VERSION ""

NS_ :

BS_:

BU_: BCM ELL ELR ERL ERR KHD N3P NAG NAP NCL NCP NPR NSP NVO PLG RSH RSL RSR SGW

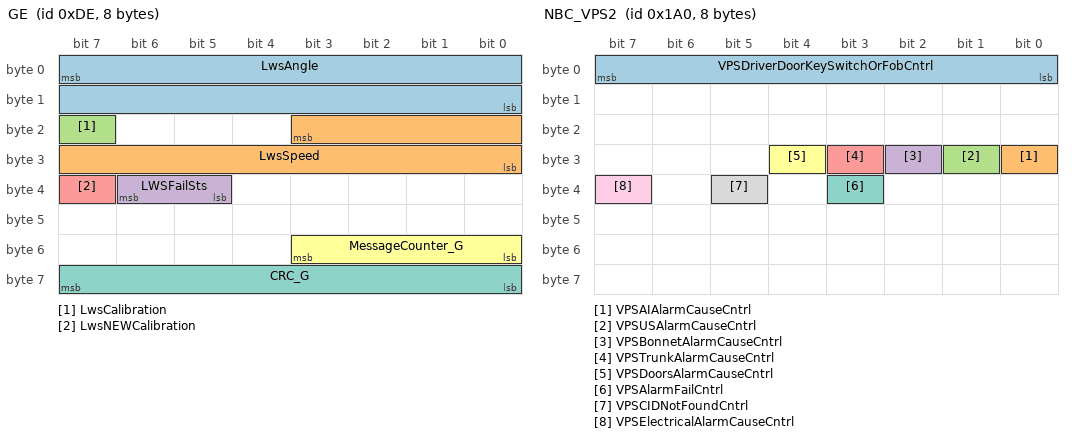
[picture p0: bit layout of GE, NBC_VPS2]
BO_ 222 GE: 8 SGW
 SG_ LwsAngle : 7|16@0+ (0.1,-720) [-720|720] "�" Vector__XXX
 SG_ LwsSpeed : 19|12@0+ (1,-2000) [-2000|2094] "�/S" Vector__XXX
 SG_ LwsCalibration : 23|1@0+ (1,0) [0|1] "" Vector__XXX
 SG_ LWSFailSts : 38|2@0+ (1,0) [0|3] "" Vector__XXX
 SG_ LwsNEWCalibration : 39|1@0+ (1,0) [0|1] "" Vector__XXX
 SG_ MessageCounter_G : 51|4@0+ (1,0) [0|15] "" Vector__XXX
 SG_ CRC_G : 63|8@0+ (1,0) [0|255] "" Vector__XXX

BO_ 359 RFHUB1: 8 BCM
 SG_ ExteriorRearSwitch : 0|1@0+ (1,0) [0|1] "" Vector__XXX
 SG_ IgnPosSts : 3|3@0+ (1,0) [0|7] "" Vector__XXX
 SG_ ValidKeySts : 5|2@0+ (1,0) [0|3] "" Vector__XXX
 SG_ CustKeyInIgnSts : 7|2@0+ (1,0) [0|3] "" Vector__XXX
 SG_ RFFuncReq : 8|5@0+ (1,0) [0|31] "" Vector__XXX
 SG_ RFFobNum : 12|4@0+ (1,0) [0|15] "" Vector__XXX
 SG_ RFRearFuncReq : 15|3@0+ (1,0) [0|7] "" Vector__XXX
 SG_ FobSearchResult : 16|8@0+ (1,0) [0|255] "" Vector__XXX
 SG_ RFReq : 19|3@0+ (1,0) [0|7] "" Vector__XXX
 SG_ EmergencyShutdown : 24|1@0+ (1,0) [0|1] "" Vector__XXX
 SG_ FobSearchFault : 32|1@0+ (1,0) [0|1] "" Vector__XXX
 SG_ HMIPowerOnReq : 33|1@0+ (1,0) [0|1] "" Vector__XXX
 SG_ FOBInterferenceAvoid : 34|1@0+ (1,0) [0|1] "raw" Vector__XXX
 SG_ DriverEnginOffRequest : 35|1@0+ (1,0) [0|1] "" Vector__XXX
 SG_ FobSearchResult_LongPressure : 39|3@0+ (1,0) [0|7] "" Vector__XXX
 SG_ FobSearchExteriorRear : 41|1@0+ (1,0) [0|1] "" Vector__XXX
 SG_ FobSearchExteriorLeft : 42|1@0+ (1,0) [0|1] "" Vector__XXX
 SG_ FobSearchExteriorRight : 43|1@0+ (1,0) [0|1] "" Vector__XXX
 SG_ FobSearchInterior : 44|1@0+ (1,0) [0|1] "" Vector__XXX
 SG_ FobSearchTrunk : 45|1@0+ (1,0) [0|1] "" Vector__XXX
 SG_ FobSearchStatus : 47|2@0+ (1,0) [0|3] "" Vector__XXX
 SG_ MessageCounter_HUB1 : 51|4@0+ (1,0) [0|15] ""  KHD
 SG_ KeyCommandReq : 52|1@0+ (1,0) [0|1] ""  KHD
 SG_ NPE_ActuationReq : 55|2@0+ (1,0) [0|3] "" Vector__XXX
 SG_ CRC_HUB1 : 63|8@0+ (1,0) [0|255] ""  KHD

BO_ 384 EXTERNAL_LIGHTS: 8 BCM
 SG_ FrontWiperServicePositionSts : 0|1@0+ (1,0) [0|1] ""  SGW
 SG_ FrontWindWiperCarWashErrSts : 1|1@0+ (1,0) [0|1] ""  SGW
 SG_ RearWindowWiperMotorErrorSts : 2|1@0+ (1,0) [0|1] ""  SGW
 SG_ RearWindowWiperSts : 3|1@0+ (1,0) [0|1] ""  NVO,SGW
 SG_ FrontWindshieldWiperMotErrSts : 4|1@0+ (1,0) [0|1] ""  SGW
 SG_ NightDaySts : 8|1@0+ (1,0) [0|1] ""  KHD,NVO,SGW
 SG_ RearFogLightSts : 9|1@0+ (1,0) [0|1] ""  SGW
 SG_ AHBFeature : 10|1@0+ (1,0) [0|1] ""  SGW
 SG_ LowBeamSts : 11|1@0+ (1,0) [0|1] ""  NVO,SGW
 SG_ HighBeamSts : 12|1@0+ (1,0) [0|1] ""  NVO,SGW
 SG_ LHParkTailLightSts : 13|1@0+ (1,0) [0|1] ""  SGW
 SG_ RHParkTailLightSts : 14|1@0+ (1,0) [0|1] ""  SGW
 SG_ LHRTurnLightFailSts : 16|1@0+ (1,0) [0|1] ""  SGW
 SG_ RHRTurnLightFailSts : 17|1@0+ (1,0) [0|1] ""  SGW
 SG_ EXT_LGH_ParkingLightCmd : 19|2@0+ (1,0) [0|3] ""  SGW
 SG_ RHeatedWindowSts : 20|1@0+ (1,0) [0|1] ""  NCL,SGW
 SG_ RHTurnSignalSts : 21|1@0+ (1,0) [0|1] ""  SGW
 SG_ LHTurnSignalSts : 22|1@0+ (1,0) [0|1] ""  SGW
 SG_ RHRearFogLightFailSts : 24|1@0+ (1,0) [0|1] ""  SGW
 SG_ LHRearFogLightFailSts : 25|1@0+ (1,0) [0|1] ""  SGW
 SG_ RHStopLightFailSts : 27|1@0+ (1,0) [0|1] ""  SGW
 SG_ LHStopLightFailSts : 28|1@0+ (1,0) [0|1] ""  SGW
 SG_ LHFTurnLightFailSts : 30|1@0+ (1,0) [0|1] ""  SGW
 SG_ RHFTurnLightFailSts : 31|1@0+ (1,0) [0|1] ""  SGW
 SG_ WindStopperSts : 34|3@0+ (1,0) [0|7] "" Vector__XXX
 SG_ PlateLightFailSts : 35|1@0+ (1,0) [0|1] ""  SGW
 SG_ LHRParkTailLightFailSts : 38|1@0+ (1,0) [0|1] ""  SGW
 SG_ RHRParkTailLightFailSts : 39|1@0+ (1,0) [0|1] ""  SGW
 SG_ ExternalLightsSts : 43|2@0+ (1,0) [0|3] ""  SGW
 SG_ MsgCnt_EXTERNAL_LIGHT : 51|4@0+ (1,0) [0|15] ""  SGW
 SG_ RearFog_Button : 53|2@0+ (1,0) [0|3] ""  SGW
 SG_ ParkingFeedbackLed : 55|2@0+ (1,0) [0|3] ""  SGW
 SG_ CRC_EXTERNAL_LIGHT : 63|8@0+ (1,0) [0|255] ""  SGW

BO_ 416 NBC_VPS2: 8 BCM
 SG_ VPSDriverDoorKeySwitchOrFobCntrl : 7|8@0+ (1,0) [0|255] ""  NCP,SGW
 SG_ VPSAIAlarmCauseCntrl : 24|1@0+ (1,0) [0|1] ""  SGW
 SG_ VPSUSAlarmCauseCntrl : 25|1@0+ (1,0) [0|1] ""  SGW
 SG_ VPSBonnetAlarmCauseCntrl : 26|1@0+ (1,0) [0|1] ""  SGW
 SG_ VPSTrunkAlarmCauseCntrl : 27|1@0+ (1,0) [0|1] ""  SGW
 SG_ VPSDoorsAlarmCauseCntrl : 28|1@0+ (1,0) [0|1] ""  SGW
 SG_ VPSAlarmFailCntrl : 35|1@0+ (1,0) [0|1] ""  SGW
 SG_ VPSCIDNotFoundCntrl : 37|1@0+ (1,0) [0|1] ""  SGW
 SG_ VPSElectricalAlarmCauseCntrl : 39|1@0+ (1,0) [0|1] ""  SGW

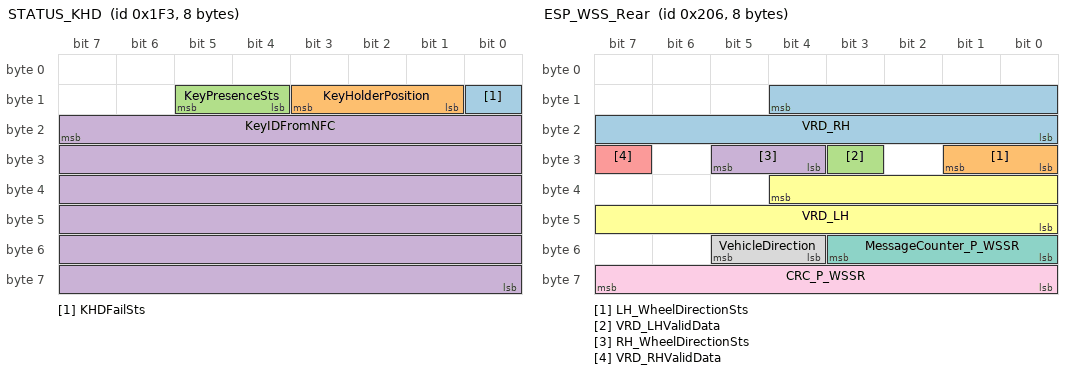
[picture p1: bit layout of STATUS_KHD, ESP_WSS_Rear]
BO_ 499 STATUS_KHD: 8 KHD
 SG_ KHDFailSts : 8|1@0+ (1,0) [0|1] ""  BCM,SGW
 SG_ KeyHolderPosition : 11|3@0+ (1,0) [0|7] ""  BCM,SGW
 SG_ KeyPresenceSts : 13|2@0+ (1,0) [0|3] ""  BCM,SGW
 SG_ KeyIDFromNFC : 23|48@0+ (1,0) [0|281474976710655] ""  BCM,SGW

BO_ 518 ESP_WSS_Rear: 8 SGW
 SG_ VRD_RH : 12|13@0+ (0.0625,0) [0.5|511.9375] "km/h"  ERL,ERR
 SG_ LH_WheelDirectionSts : 25|2@0+ (1,0) [0|3] "" Vector__XXX
 SG_ VRD_LHValidData : 27|1@0+ (1,0) [0|1] ""  ERL,ERR
 SG_ RH_WheelDirectionSts : 29|2@0+ (1,0) [0|3] "" Vector__XXX
 SG_ VRD_RHValidData : 31|1@0+ (1,0) [0|1] ""  ERL,ERR
 SG_ VRD_LH : 36|13@0+ (0.0625,0) [0.5|511.9375] "km/h"  ERL,ERR
 SG_ MessageCounter_P_WSSR : 51|4@0+ (1,0) [0|15] ""  ERL,ERR
 SG_ VehicleDirection : 53|2@0+ (1,0) [0|3] "" Vector__XXX
 SG_ CRC_P_WSSR : 63|8@0+ (1,0) [0|255] ""  ERL,ERR

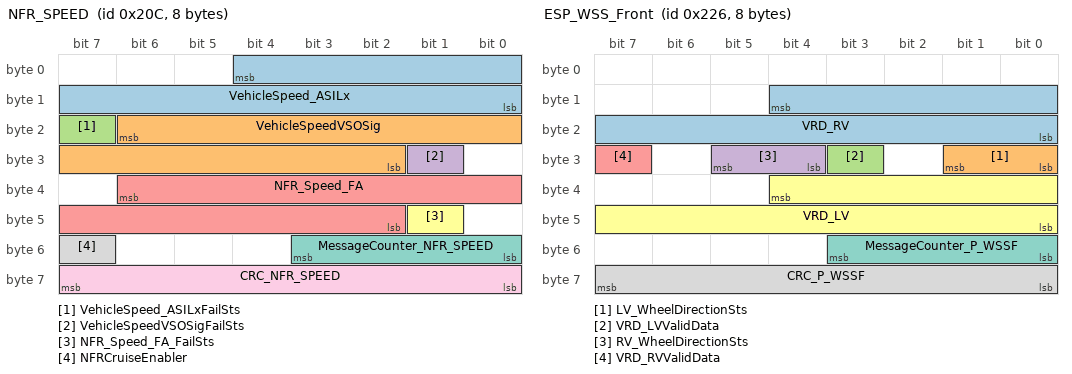
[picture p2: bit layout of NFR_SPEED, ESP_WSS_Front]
BO_ 524 NFR_SPEED: 8 SGW
 SG_ VehicleSpeed_ASILx : 4|13@0+ (0.0625,0) [0|511.9375] "km/h" Vector__XXX
 SG_ VehicleSpeedVSOSig : 22|13@0+ (0.0625,0) [0|511.9375] "km/h" Vector__XXX
 SG_ VehicleSpeed_ASILxFailSts : 23|1@0+ (1,0) [0|1] "" Vector__XXX
 SG_ VehicleSpeedVSOSigFailSts : 25|1@0+ (1,0) [0|1] "" Vector__XXX
 SG_ NFR_Speed_FA : 38|13@0+ (0.0625,0) [0|511.9375] "km/h"  ELL,ELR,ERL,ERR,KHD,NCP
 SG_ NFR_Speed_FA_FailSts : 41|1@0+ (1,0) [0|1] ""  ELL,ELR,ERL,ERR,KHD,NCP
 SG_ MessageCounter_NFR_SPEED : 51|4@0+ (1,0) [0|15] ""  ELL,ELR,ERL,ERR,NCP
 SG_ NFRCruiseEnabler : 55|1@0+ (1,0) [0|1] "" Vector__XXX
 SG_ CRC_NFR_SPEED : 63|8@0+ (1,0) [0|255] ""  ELL,ELR,ERL,ERR,NCP

BO_ 550 ESP_WSS_Front: 8 SGW
 SG_ VRD_RV : 12|13@0+ (0.0625,0) [0.5|511.9375] "km/h"  ERL,ERR
 SG_ LV_WheelDirectionSts : 25|2@0+ (1,0) [0|3] "" Vector__XXX
 SG_ VRD_LVValidData : 27|1@0+ (1,0) [0|1] ""  ERL,ERR
 SG_ RV_WheelDirectionSts : 29|2@0+ (1,0) [0|3] "" Vector__XXX
 SG_ VRD_RVValidData : 31|1@0+ (1,0) [0|1] ""  ERL,ERR
 SG_ VRD_LV : 36|13@0+ (0.0625,0) [0.5|511.9375] "km/h"  ERL,ERR
 SG_ MessageCounter_P_WSSF : 51|4@0+ (1,0) [0|15] ""  ERL,ERR
 SG_ CRC_P_WSSF : 63|8@0+ (1,0) [0|255] ""  ERL,ERR

BO_ 599 AIRBAG1: 8 BCM
 SG_ SBR2RowCentralSeatBuckleFailSts : 0|2@0+ (1,0) [0|3] "" Vector__XXX
 SG_ SBR2RowCentralSeatConfigSts : 1|1@0+ (1,0) [0|1] "" Vector__XXX
 SG_ AirBagFailSts : 7|2@0+ (1,0) [0|3] "" Vector__XXX
 SG_ SBR1RowDriverSeatFailSts : 8|2@0+ (1,0) [0|3] "" Vector__XXX
 SG_ SBR1RowDriverSeatConfigSts : 9|1@0+ (1,0) [0|1] "" Vector__XXX
 SG_ SBR2RowCentralSeatSts : 12|3@0+ (1,0) [0|7] "" Vector__XXX
 SG_ SBR1RowCentralSeatPPDFailSts : 14|2@0+ (1,0) [0|3] "" Vector__XXX
 SG_ SBR1RowPsngrSeatPPDFailSts : 17|2@0+ (1,0) [0|3] "" Vector__XXX
 SG_ SBR1RowPsngrSeatBuckleFailSts : 19|2@0+ (1,0) [0|3] "" Vector__XXX
 SG_ SBR1RowPsngrSeatConfigSts : 20|1@0+ (1,0) [0|1] "" Vector__XXX
 SG_ SBR1RowDriverSeatSts : 22|2@0+ (1,0) [0|3] "" Vector__XXX
 SG_ SBR2RowLeftSeatSts : 24|2@0+ (1,0) [0|3] ""  RSL
 SG_ SBR2RowRightSeatFailSts : 26|2@0+ (1,0) [0|3] "" Vector__XXX
 SG_ SBR2RowLeftSeatFailSts : 28|2@0+ (1,0) [0|3] "" Vector__XXX
 SG_ SBR1RowPsngrSeatSts : 31|3@0+ (1,0) [0|7] "" Vector__XXX
 SG_ CrashOutputSts : 36|8@0+ (1,0) [0|255] ""  ELL,ELR,ERL,ERR
 SG_ SBR2RowRightSeatSts : 38|2@0+ (1,0) [0|3] ""  RSR
 SG_ MessageCounter_NAB1 : 43|4@0+ (1,0) [0|15] ""  ELL,ELR,ERL,ERR,NCL,RSL,RSR
 SG_ CrashOutputValidData : 44|1@0+ (1,0) [0|1] ""  ELL,ELR,ERL,ERR
 SG_ CRC_NAB1 : 55|8@0+ (1,0) [0|255] ""  ELL,ELR,ERL,ERR,NCL,RSL,RSR
 SG_ AirBagWarningPADLampOnSts : 56|1@0+ (1,0) [0|1] "" Vector__XXX
 SG_ AirBagWarningPADLampOffSts : 57|1@0+ (1,0) [0|1] "" Vector__XXX
 SG_ SBR2RowRightSeatConfigSts : 58|1@0+ (1,0) [0|1] "" Vector__XXX
 SG_ SBR2RowLeftSeatConfigSts : 59|1@0+ (1,0) [0|1] "" Vector__XXX
 SG_ Ppd_psngr_info : 61|2@0+ (1,0) [0|3] ""  NCL
 SG_ AirBagWarningLampSts : 62|1@0+ (1,0) [0|1] "" Vector__XXX
 SG_ AirBagWarningPADPassengerAirbagS : 63|1@0+ (1,0) [0|1] "" Vector__XXX

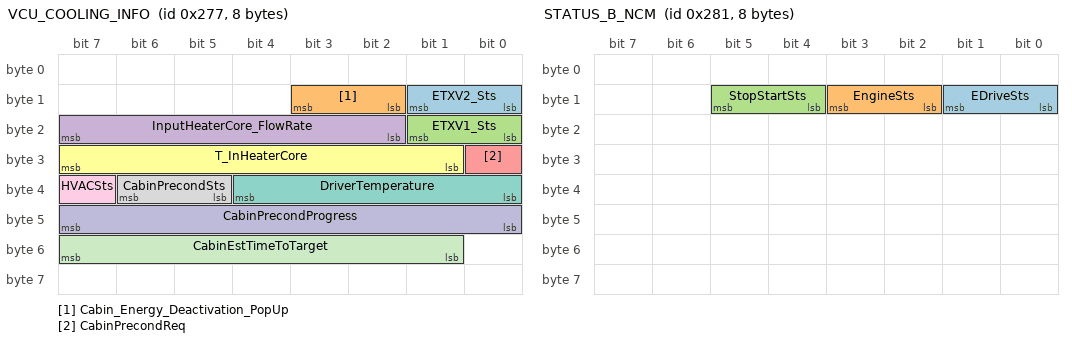
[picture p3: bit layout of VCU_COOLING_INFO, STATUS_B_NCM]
BO_ 631 VCU_COOLING_INFO: 8 SGW
 SG_ ETXV2_Sts : 9|2@0+ (1,0) [0|3] ""  NCL
 SG_ Cabin_Energy_Deactivation_PopUp : 11|2@0+ (1,0) [0|3] "" Vector__XXX
 SG_ ETXV1_Sts : 17|2@0+ (1,0) [0|3] ""  NCL
 SG_ InputHeaterCore_FlowRate : 23|6@0+ (1,0) [0|60] "l/min"  NCL
 SG_ CabinPrecondReq : 24|1@0+ (1,0) [0|1] ""  NCL
 SG_ T_InHeaterCore : 31|7@0+ (1,-20) [-20|90] "�C"  NCL
 SG_ DriverTemperature : 36|5@0+ (0.5,15.5) [15.5|28.5] ""  NCL
 SG_ CabinPrecondSts : 38|2@0+ (1,0) [0|3] "" Vector__XXX
 SG_ HVACSts : 39|1@0+ (1,0) [0|1] "" Vector__XXX
 SG_ CabinPrecondProgress : 47|8@0+ (0.5,0) [0|127.5] "%" Vector__XXX
 SG_ CabinEstTimeToTarget : 55|7@0+ (1,0) [0|127] "min" Vector__XXX

BO_ 641 STATUS_B_NCM: 8 BCM
 SG_ EDriveSts : 9|2@0+ (1,0) [0|3] ""  ELL,ELR,ERL,ERR,N3P,NAG,NAP,NCL,NCP,PLG,RSH,RSL,RSR
 SG_ EngineSts : 11|2@0+ (1,0) [0|3] ""  ELL,ELR,ERL,ERR,N3P,NAG,NAP,NCL,NCP,NPR,PLG,RSH,RSL,RSR
 SG_ StopStartSts : 13|2@0+ (1,0) [0|3] ""  ELL,ELR,ERL,ERR,NAG,NAP,NCL,NCP,PLG,RSL,RSR

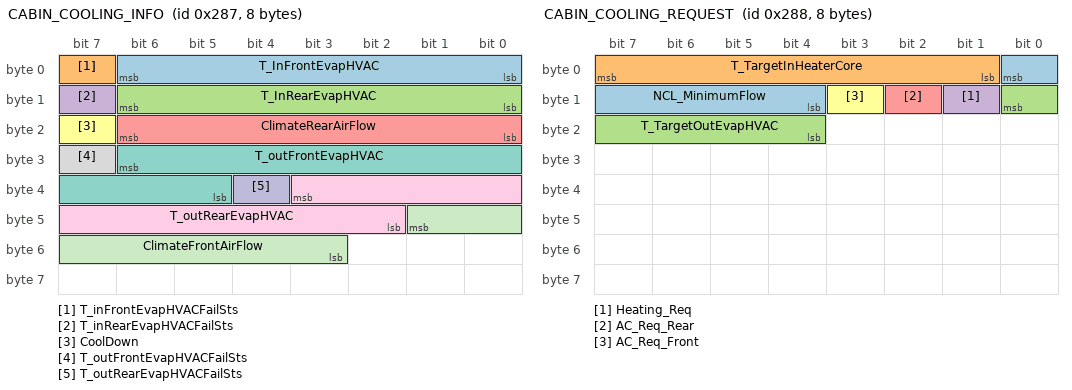
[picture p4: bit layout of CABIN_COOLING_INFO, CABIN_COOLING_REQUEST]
BO_ 647 CABIN_COOLING_INFO: 8 NCL
 SG_ T_InFrontEvapHVAC : 6|7@0+ (1,-10) [-10|90] "�C"  SGW
 SG_ T_inFrontEvapHVACFailSts : 7|1@0+ (1,0) [0|1] ""  SGW
 SG_ T_InRearEvapHVAC : 14|7@0+ (1,-10) [-10|90] "�C"  SGW
 SG_ T_inRearEvapHVACFailSts : 15|1@0+ (1,0) [0|1] ""  SGW
 SG_ ClimateRearAirFlow : 22|7@0+ (5,0) [0|500] "m3/h"  SGW
 SG_ CoolDown : 23|1@0+ (1,0) [0|1] ""  SGW
 SG_ T_outFrontEvapHVAC : 30|10@0+ (0.1,-10) [-10|70] "�C"  SGW
 SG_ T_outFrontEvapHVACFailSts : 31|1@0+ (1,0) [0|1] ""  SGW
 SG_ T_outRearEvapHVAC : 35|10@0+ (0.1,-10) [-10|70] "�C"  SGW
 SG_ T_outRearEvapHVACFailSts : 36|1@0+ (1,0) [0|1] ""  SGW
 SG_ ClimateFrontAirFlow : 41|7@0+ (5,0) [0|500] "m3/h"  SGW

BO_ 648 CABIN_COOLING_REQUEST: 8 NCL
 SG_ NCL_MinimumFlow : 0|5@0+ (1,0) [0|25] "l/min"  SGW
 SG_ T_TargetInHeaterCore : 7|7@0+ (1,-20) [-20|90] "�C"  SGW
 SG_ T_TargetOutEvapHVAC : 8|5@0+ (0.5,0) [0|10] "�C"  SGW
 SG_ Heating_Req : 9|1@0+ (1,0) [0|1] ""  SGW
 SG_ AC_Req_Rear : 10|1@0+ (1,0) [0|1] ""  SGW
 SG_ AC_Req_Front : 11|1@0+ (1,0) [0|1] ""  SGW

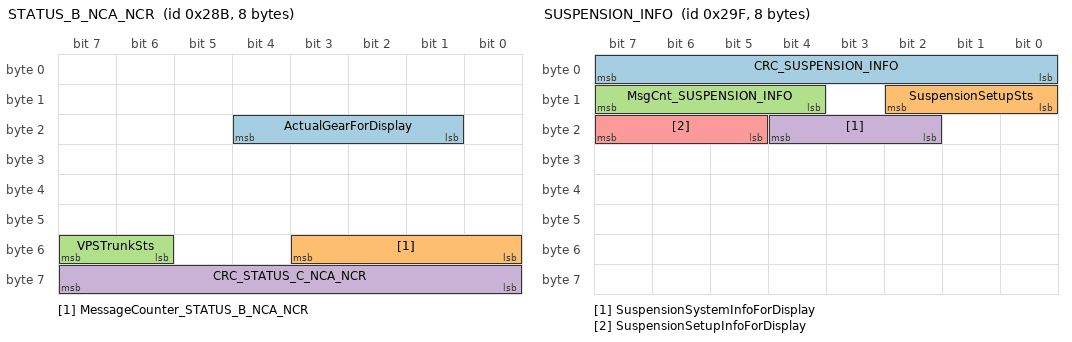
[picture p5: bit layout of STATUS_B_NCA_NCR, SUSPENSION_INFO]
BO_ 651 STATUS_B_NCA_NCR: 8 BCM
 SG_ ActualGearForDisplay : 20|4@0+ (1,0) [0|15] ""  SGW
 SG_ MessageCounter_STATUS_B_NCA_NCR : 51|4@0+ (1,0) [0|15] ""  RSL,RSR,SGW
 SG_ VPSTrunkSts : 55|2@0+ (1,0) [0|3] ""  RSL,RSR
 SG_ CRC_STATUS_C_NCA_NCR : 63|8@0+ (1,0) [0|255] ""  RSL,RSR,SGW

BO_ 671 SUSPENSION_INFO: 8 SGW
 SG_ CRC_SUSPENSION_INFO : 7|8@0+ (1,0) [0|255] ""  NVO
 SG_ SuspensionSetupSts : 10|3@0+ (1,0) [0|7] ""  NVO
 SG_ MsgCnt_SUSPENSION_INFO : 15|4@0+ (1,0) [0|14] ""  NVO
 SG_ SuspensionSystemInfoForDisplay : 20|3@0+ (1,0) [0|7] ""  NVO
 SG_ SuspensionSetupInfoForDisplay : 23|3@0+ (1,0) [0|7] "" Vector__XXX

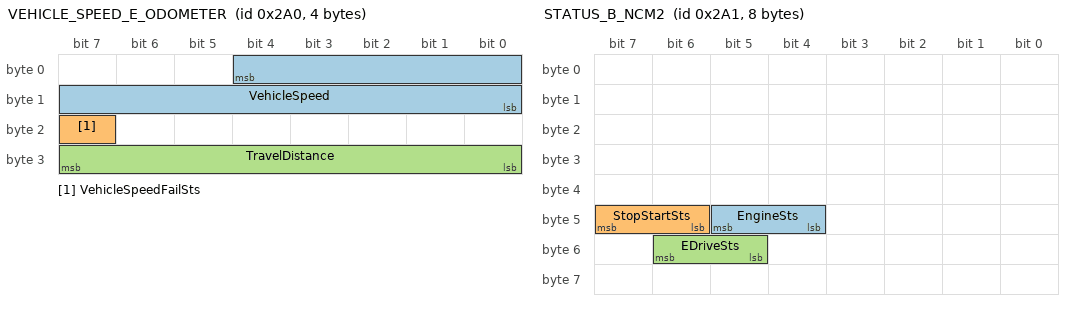
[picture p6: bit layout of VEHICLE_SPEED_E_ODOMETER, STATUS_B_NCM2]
BO_ 672 VEHICLE_SPEED_E_ODOMETER: 4 BCM
 SG_ VehicleSpeed : 4|13@0+ (0.1,0) [0|512] "km/h"  N3P,NAG,NAP,NCL,NCP,NPR,NSP,NVO,PLG,RSH,RSL,RSR,SGW
 SG_ VehicleSpeedFailSts : 23|1@0+ (1,0) [0|1] ""  N3P,NAG,NAP,NCL,NCP,NPR,NSP,NVO,PLG,RSH,RSL,RSR,SGW
 SG_ TravelDistance : 31|8@0+ (9.8,0) [0|2499] "m"  SGW

BO_ 673 STATUS_B_NCM2: 8 BCM
 SG_ EngineSts : 45|2@0+ (1,0) [0|3] ""  SGW
 SG_ StopStartSts : 47|2@0+ (1,0) [0|3] ""  SGW
 SG_ EDriveSts : 54|2@0+ (1,0) [0|3] ""  SGW

BO_ 684 STATUS_B_NAS: 4 BCM
 SG_ LWS_Angle : 7|16@0- (0.1,0) [-780|780] "�"  NSP,SGW
 SG_ LWS_OK : 23|1@0+ (1,0) [0|1] ""  NSP,SGW

BO_ 761 GEAR_INFO: 8 SGW
 SG_ GearLeverPositionforNPE : 20|3@0+ (1,0) [0|7] ""  KHD
 SG_ GearLeverFailForNPE : 24|1@0+ (1,0) [0|1] ""  KHD

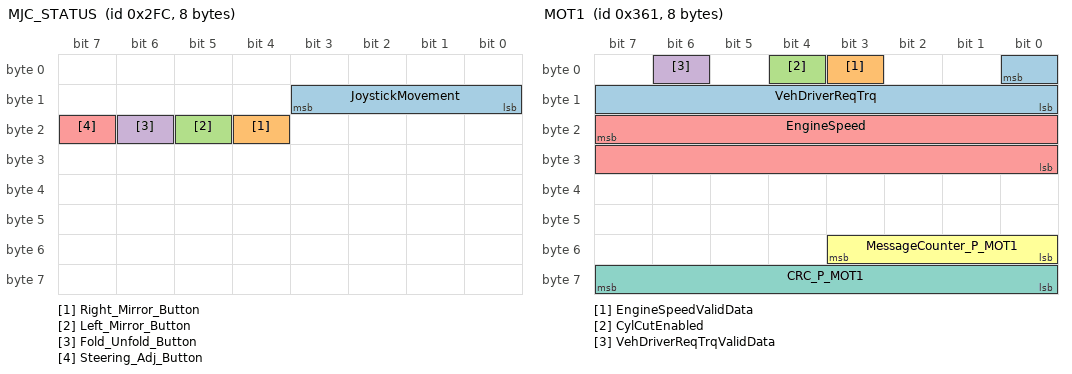
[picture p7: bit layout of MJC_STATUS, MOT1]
BO_ 764 MJC_STATUS: 8 BCM
 SG_ JoystickMovement : 11|4@0+ (1,0) [0|15] ""  NAG
 SG_ Right_Mirror_Button : 20|1@0+ (1,0) [0|1] ""  SGW
 SG_ Left_Mirror_Button : 21|1@0+ (1,0) [0|1] ""  SGW
 SG_ Fold_Unfold_Button : 22|1@0+ (1,0) [0|1] ""  SGW
 SG_ Steering_Adj_Button : 23|1@0+ (1,0) [0|1] ""  NAG

BO_ 765 AUDIO_INFO: 8 SGW
 SG_ AvasAlertSound : 10|1@0+ (1,0) [0|1] "" Vector__XXX
 SG_ AVASFailSts : 11|1@0+ (1,0) [0|1] ""  PLG

BO_ 865 MOT1: 8 SGW
 SG_ VehDriverReqTrq : 0|9@0+ (4,-508) [-508|1536] "Nm" Vector__XXX
 SG_ EngineSpeedValidData : 3|1@0+ (1,0) [0|1] ""  KHD,N3P,NCL,RSH
 SG_ CylCutEnabled : 4|1@0+ (1,0) [0|1] "" Vector__XXX
 SG_ VehDriverReqTrqValidData : 6|1@0+ (1,0) [0|1] "" Vector__XXX
 SG_ EngineSpeed : 23|16@0+ (1,0) [0|10240] "1/min"  KHD,N3P,NCL,RSH
 SG_ MessageCounter_P_MOT1 : 51|4@0+ (1,0) [0|15] ""  KHD,NCL
 SG_ CRC_P_MOT1 : 63|8@0+ (1,0) [0|255] ""  KHD,NCL

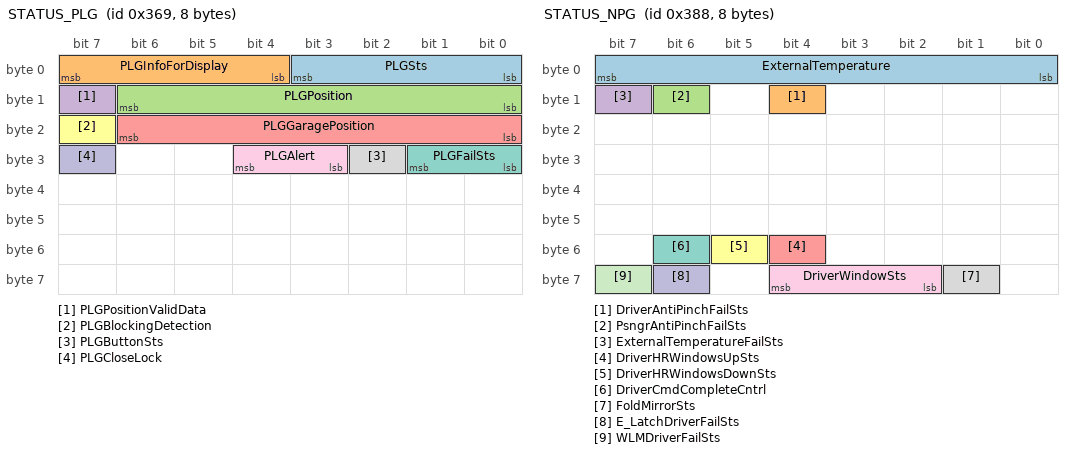
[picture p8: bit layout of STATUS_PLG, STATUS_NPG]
BO_ 873 STATUS_PLG: 8 PLG
 SG_ PLGSts : 3|4@0+ (1,0) [0|15] ""  BCM,SGW
 SG_ PLGInfoForDisplay : 7|4@0+ (1,0) [0|15] ""  SGW
 SG_ PLGPosition : 14|7@0+ (1,0) [0|100] "%"  SGW
 SG_ PLGPositionValidData : 15|1@0+ (1,0) [0|1] ""  SGW
 SG_ PLGGaragePosition : 22|7@0+ (1,0) [0|100] "%"  SGW
 SG_ PLGBlockingDetection : 23|1@0+ (1,0) [0|1] ""  SGW
 SG_ PLGFailSts : 25|2@0+ (1,0) [0|3] ""  SGW
 SG_ PLGButtonSts : 26|1@0+ (1,0) [0|1] ""  BCM,NCL,SGW
 SG_ PLGAlert : 28|2@0+ (1,0) [0|3] ""  SGW
 SG_ PLGCloseLock : 31|1@0+ (1,0) [0|1] ""  BCM,SGW

BO_ 896 STATUS_NBC: 8 BCM
 SG_ SysEOLSts : 2|1@0+ (1,0) [0|1] ""  SGW
 SG_ InternalLightSts : 3|1@0+ (1,0) [0|1] ""  KHD,NVO,SGW
 SG_ VehicleNotInUseSignaling : 4|1@0+ (1,0) [0|1] ""  SGW
 SG_ InternalBacklightStsKeyOff : 6|1@0+ (1,0) [0|1] ""  KHD,SGW
 SG_ BrakePadWearSts : 7|1@0+ (1,0) [0|1] ""  SGW
 SG_ WishWashSts : 9|1@0+ (1,0) [0|1] ""  NCL,SGW
 SG_ PsngrDoorSts : 11|1@0+ (1,0) [0|1] ""  NVO,SGW
 SG_ PLGCommand2 : 13|2@0+ (1,0) [0|3] ""  PLG,SGW
 SG_ RhatchSts : 14|1@0+ (1,0) [0|1] ""  NCL,NCP,SGW
 SG_ BonnetSts : 15|1@0+ (1,0) [0|1] ""  SGW
 SG_ ReverseGearBCSts : 18|1@0+ (1,0) [0|1] ""  NAG,NSP,SGW
 SG_ KeySts : 23|4@0+ (1,0) [0|15] "raw"  ELL,ELR,ERL,ERR,KHD,N3P,NAG,NAP,NCL,NPR,NSP,PLG,RSH,RSL,RSR,SGW
 SG_ BatteryVoltageLevel : 30|7@0+ (0.16,0) [0|18] "volt"  NAG,NAP,NCL,RSL,RSR,SGW
 SG_ NBCFISSts : 31|1@0+ (1,0) [0|1] ""  ELL,ELR,ERL,ERR,NCL,SGW
 SG_ FuelLevelFailSts : 32|1@0+ (1,0) [0|1] ""  SGW
 SG_ LowFuelWarningSts : 33|1@0+ (1,0) [0|1] ""  SGW
 SG_ FuelLevel : 47|8@0+ (1,0) [0|100] "%"  SGW
 SG_ IMMOCodeWarningLightSts : 54|7@0+ (1,0) [1|18] ""  SGW
 SG_ TurnIndicatorSts : 62|2@0+ (1,0) [0|3] ""  SGW
 SG_ RainSensorFailSts : 63|1@0+ (1,0) [0|1] ""  SGW

BO_ 904 STATUS_NPG: 8 BCM
 SG_ ExternalTemperature : 7|8@0+ (0.5,-40) [-39.5|87.5] "�C"  KHD,N3P,NAG,NAP,NCL,NCP,NPR,NSP,PLG,RSH,SGW
 SG_ DriverAntiPinchFailSts : 12|1@0+ (1,0) [0|1] ""  SGW
 SG_ PsngrAntiPinchFailSts : 14|1@0+ (1,0) [0|1] ""  SGW
 SG_ ExternalTemperatureFailSts : 15|1@0+ (1,0) [0|1] ""  KHD,N3P,NCL,NCP,NPR,NSP,PLG,RSH,SGW
 SG_ DriverHRWindowsUpSts : 52|1@0+ (1,0) [0|1] ""  NCP,SGW
 SG_ DriverHRWindowsDownSts : 53|1@0+ (1,0) [0|1] ""  NCP,SGW
 SG_ DriverCmdCompleteCntrl : 54|1@0+ (1,0) [0|1] ""  NCP,SGW
 SG_ FoldMirrorSts : 57|1@0+ (1,0) [0|1] ""  SGW
 SG_ DriverWindowSts : 60|3@0+ (1,0) [0|7] ""  NAG,NCP,SGW
 SG_ E_LatchDriverFailSts : 62|1@0+ (1,0) [0|1] ""  SGW
 SG_ WLMDriverFailSts : 63|1@0+ (1,0) [0|1] ""  SGW

BO_ 906 STATUS_NCL: 8 NCL
 SG_ MaxDefrostSts : 4|1@0+ (1,0) [0|1] ""  BCM,SGW
 SG_ RHeatedWindowCntrl : 5|1@0+ (1,0) [0|1] ""  BCM,SGW
 SG_ PowerModeSts : 13|2@0+ (1,0) [0|3] ""  BCM,SGW
 SG_ ADAS_heater : 18|1@0+ (1,0) [0|1] ""  SGW
 SG_ FogRisk : 23|1@0+ (1,0) [0|1] ""  SGW
 SG_ AirQualityIndex : 24|9@0+ (1,0) [0|511] ""  SGW
 SG_ NCL_RimHeatingCommand : 40|1@0+ (1,0) [0|1] ""  BCM,SGW
 SG_ TargetVoltage : 45|5@0+ (2,0) [0|62] "V"  NPR,SGW
 SG_ NPRActivationReq : 46|1@0+ (1,0) [0|1] ""  NPR,SGW
 SG_ NCL_FrontPassengerHeating : 49|2@0+ (1,0) [0|3] ""  NAP
 SG_ NCL_PassengerFans : 51|2@0+ (1,0) [0|3] ""  NAP
 SG_ NCL_FrontDriverHeating : 53|2@0+ (1,0) [0|3] ""  NAG
 SG_ NCL_DriverFans : 55|2@0+ (1,0) [0|3] ""  NAG
 SG_ NCL_RRHeating : 57|2@0+ (1,0) [0|3] ""  RSH
 SG_ NCL_RRFans : 59|2@0+ (1,0) [0|3] ""  RSH
 SG_ NCL_RLHeating : 61|2@0+ (1,0) [0|3] ""  RSH
 SG_ NCL_RLFans : 63|2@0+ (1,0) [0|3] ""  RSH

BO_ 952 STATUS_NSP2: 8 NSP
 SG_ FrameNumber : 1|2@0+ (1,0) [0|3] ""  SGW
 SG_ TotalFrameNumber : 3|2@0+ (1,0) [0|3] ""  SGW
 SG_ NSPFailSts : 5|2@0+ (1,0) [0|3] ""  NCP,SGW
 SG_ NSPControlSts : 7|2@0+ (1,0) [0|3] ""  SGW
 SG_ LHNSPBuzzerReqSts : 8|1@0+ (1,0) [0|1] ""  SGW
 SG_ LHLateralcolour : 10|2@0+ (1,0) [0|3] ""  SGW
 SG_ LHLateralObstacleDistance : 15|5@0+ (4,30) [30|154] "cm"  SGW
 SG_ RHNSPBuzzerReqSts : 16|1@0+ (1,0) [0|1] ""  SGW
 SG_ LHCentralcolour : 18|2@0+ (1,0) [0|3] ""  SGW
 SG_ LHCentralObstacleDistance : 23|5@0+ (4,30) [30|154] "cm"  SGW
 SG_ CNSPBuzzerReqSts : 24|1@0+ (1,0) [0|1] ""  SGW
 SG_ RHCentralcolour : 26|2@0+ (1,0) [0|3] ""  SGW
 SG_ RHCentralObstacleDistance : 31|5@0+ (4,30) [30|154] "cm"  SGW
 SG_ RHLateralcolour : 34|2@0+ (1,0) [0|3] ""  SGW
 SG_ RHLateralObstacleDistance : 39|5@0+ (4,30) [30|154] "cm"  SGW
 SG_ CapoteMovement : 45|2@0+ (1,0) [0|3] ""  NCP,SGW
 SG_ NSPBuzzerRepetitionRate : 47|2@0+ (1,0) [0|3] ""  SGW

BO_ 960 STATUS_NBC_2: 8 BCM
 SG_ ExternalLightSensorSts : 0|1@0+ (1,0) [0|1] ""  SGW
 SG_ FuelFlapSts : 1|1@0+ (1,0) [0|1] ""  SGW
 SG_ TyrePressureSystemFailSts : 8|1@0+ (1,0) [0|1] ""  SGW
 SG_ Night_E_DaySensorFailSts : 10|1@0+ (1,0) [0|1] ""  SGW
 SG_ RHRTyrePressureSts : 17|2@0+ (1,0) [0|3] ""  SGW
 SG_ LHRTyrePressureSts : 19|2@0+ (1,0) [0|3] ""  SGW
 SG_ RHFTyrePressureSts : 21|2@0+ (1,0) [0|3] ""  SGW
 SG_ LHFTyrePressureSts : 23|2@0+ (1,0) [0|3] ""  SGW
 SG_ LeftChildLockCntrl : 24|1@0+ (1,0) [0|1] ""  SGW
 SG_ RechargeFlapDisplayInfo : 28|4@0+ (1,0) [0|15] ""  SGW
 SG_ PLGBlink_Fbk : 29|1@0+ (1,0) [0|1] ""  SGW
 SG_ RimHeatingFbk : 31|2@0+ (1,0) [0|3] ""  NCL,SGW
 SG_ DriverSide : 38|1@0+ (1,0) [0|1] ""  NAG,NAP,NCP,RSL,RSR,SGW
 SG_ RHatchStsForNCP : 41|1@0+ (1,0) [0|1] ""  NCP,SGW
 SG_ PowerModeSts : 43|2@0+ (1,0) [0|3] ""  NCL,NCP,SGW
 SG_ TrunkCinchSts : 55|2@0+ (1,0) [0|3] ""  NCP,SGW
 SG_ RightChildLockCntrl : 56|1@0+ (1,0) [0|1] ""  SGW
 SG_ PLGCommandSource : 59|2@0+ (1,0) [0|3] ""  PLG,SGW
 SG_ CIDOnBoard : 60|1@0+ (1,0) [0|1] ""  NAG,SGW
 SG_ RHatchStsForPLG : 61|1@0+ (1,0) [0|1] ""  PLG,SGW
 SG_ PLGCommand : 63|2@0+ (1,0) [0|3] ""  NCL,PLG,SGW

BO_ 961 STATUS_NBC_3: 8 BCM
 SG_ UserPresence : 9|2@0+ (1,0) [0|3] ""  SGW
 SG_ RearCeilingLightsSts : 11|2@0+ (1,0) [0|3] ""  SGW
 SG_ LCC_RearDefrostCommand : 16|1@0+ (1,0) [0|1] ""  NCL,SGW
 SG_ LaunchLeverPos : 19|2@0+ (1,0) [0|3] ""  SGW
 SG_ FollowMeHomeEnable_Fbk : 23|4@0+ (1,0) [0|15] ""  SGW
 SG_ VehicleSts : 27|4@0+ (1,0) [0|7] ""  SGW
 SG_ RearRightWindowSwitch : 28|1@0+ (1,0) [0|1] ""  SGW
 SG_ RearLeftWindowSwitch : 29|1@0+ (1,0) [0|1] ""  SGW
 SG_ Deactivation_DoorOpening_Led : 30|1@0+ (1,0) [0|0] ""  SGW
 SG_ LCC_MaxDefrostCommand : 31|1@0+ (1,0) [0|1] ""  NCL,SGW
 SG_ LaunchLeverFailSts : 32|1@0+ (1,0) [0|1] ""  SGW
 SG_ LowBeam_Button : 34|2@0+ (1,0) [0|3] ""  SGW
 SG_ PlugReleaseReq : 37|1@0+ (1,0) [0|1] ""  SGW
 SG_ RearSeats : 39|2@0+ (1,0) [0|3] ""  NAG,NAP,SGW
 SG_ AHBSts : 41|2@0+ (1,0) [0|3] ""  SGW
 SG_ RearFog_Button : 43|2@0+ (1,0) [0|3] ""  SGW
 SG_ MirrorRHFailSts : 44|1@0+ (1,0) [0|1] ""  SGW
 SG_ MirrorLHFailSts : 45|1@0+ (1,0) [0|1] ""  SGW
 SG_ RearSeatsRightBackrestSts : 46|1@0+ (1,0) [0|1] ""  N3P,NAG,SGW
 SG_ RearSeatsLeftBackrestSts : 47|1@0+ (1,0) [0|1] ""  N3P,NAG,SGW

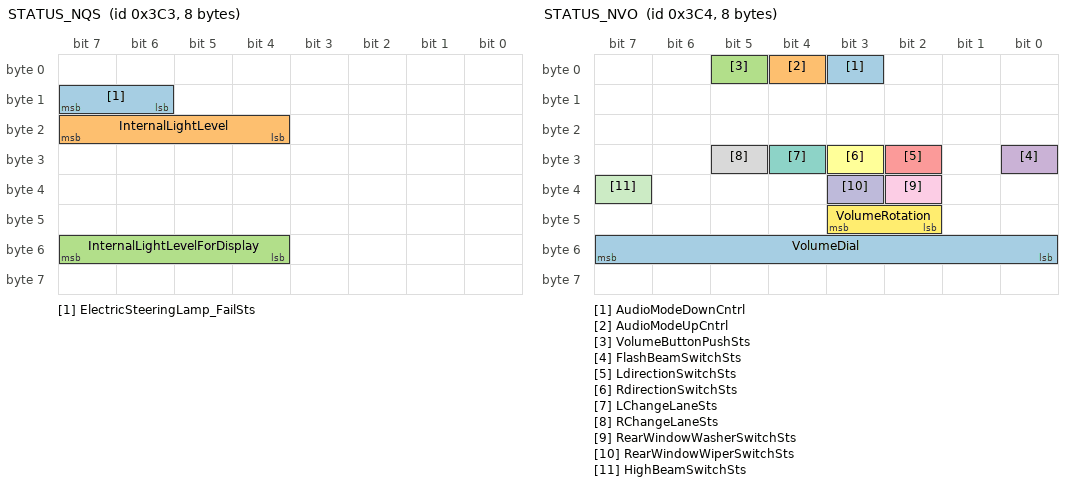
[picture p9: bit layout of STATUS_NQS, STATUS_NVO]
BO_ 963 STATUS_NQS: 8 SGW
 SG_ ElectricSteeringLamp_FailSts : 15|2@0+ (1,0) [0|3] ""  BCM
 SG_ InternalLightLevel : 23|4@0+ (1,0) [0|15] ""  BCM,NVO
 SG_ InternalLightLevelForDisplay : 55|4@0+ (1,0) [0|15] "" Vector__XXX

BO_ 964 STATUS_NVO: 8 NVO
 SG_ AudioModeDownCntrl : 3|1@0+ (1,0) [0|1] ""  BCM,SGW
 SG_ AudioModeUpCntrl : 4|1@0+ (1,0) [0|1] ""  BCM,SGW
 SG_ VolumeButtonPushSts : 5|1@0+ (1,0) [0|1] ""  BCM,SGW
 SG_ FlashBeamSwitchSts : 24|1@0+ (1,0) [0|1] ""  BCM,SGW
 SG_ LdirectionSwitchSts : 26|1@0+ (1,0) [0|1] ""  SGW
 SG_ RdirectionSwitchSts : 27|1@0+ (1,0) [0|1] ""  SGW
 SG_ LChangeLaneSts : 28|1@0+ (1,0) [0|1] ""  SGW
 SG_ RChangeLaneSts : 29|1@0+ (1,0) [0|1] ""  SGW
 SG_ RearWindowWasherSwitchSts : 34|1@0+ (1,0) [0|1] ""  BCM,SGW
 SG_ RearWindowWiperSwitchSts : 35|1@0+ (1,0) [0|1] ""  BCM,SGW
 SG_ HighBeamSwitchSts : 39|1@0+ (1,0) [0|1] ""  BCM,SGW
 SG_ VolumeRotation : 43|2@0+ (1,0) [0|3] ""  BCM,SGW
 SG_ VolumeDial : 55|8@0+ (1,0) [0|255] ""  SGW

BO_ 965 STATUS_NVO_2: 8 NVO
 SG_ ADAS_OnOffSts : 0|1@0+ (1,0) [0|1] ""  SGW
 SG_ RimTemperature : 15|8@0+ (0.5,-40) [-40|87.5] ""  BCM,NCL,SGW

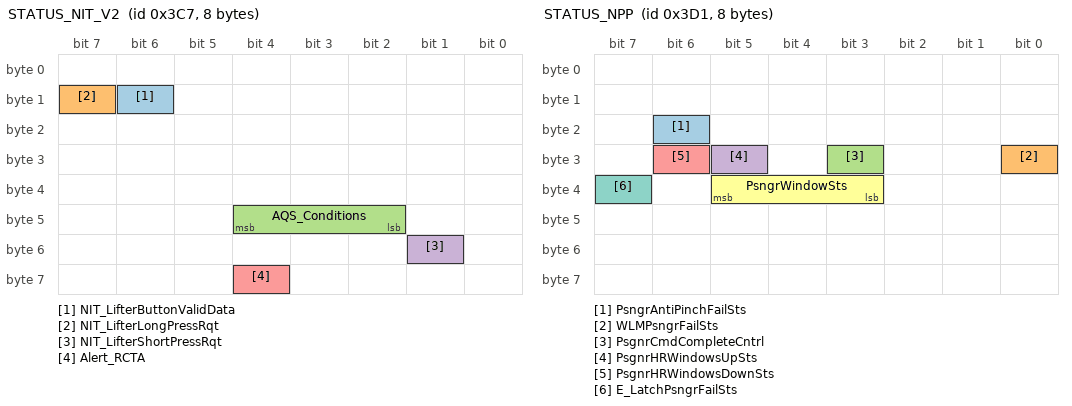
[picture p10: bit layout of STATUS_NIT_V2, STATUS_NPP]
BO_ 967 STATUS_NIT_V2: 8 SGW
 SG_ NIT_LifterButtonValidData : 14|1@0+ (1,0) [0|1] "" Vector__XXX
 SG_ NIT_LifterLongPressRqt : 15|1@0+ (1,0) [0|1] "" Vector__XXX
 SG_ AQS_Conditions : 44|3@0+ (1,0) [0|7] ""  NCL
 SG_ NIT_LifterShortPressRqt : 49|1@0+ (1,0) [0|1] "" Vector__XXX
 SG_ Alert_RCTA : 60|1@0+ (1,0) [0|1] "" Vector__XXX

BO_ 969 STATUS_NCP: 8 NCP
 SG_ CapoteBuzzerReq : 1|2@0+ (1,0) [0|3] ""  SGW
 SG_ CapoteFailSts : 3|2@0+ (1,0) [0|3] ""  BCM,NCL,SGW
 SG_ TrunkReleaseReqCntrl : 4|1@0+ (1,0) [0|1] ""  SGW
 SG_ CapoteSts : 7|3@0+ (1,0) [0|7] ""  BCM,NAG,NAP,NCL,SGW
 SG_ FrontWindowsEnable : 8|1@0+ (1,0) [0|1] ""  BCM,SGW
 SG_ TrunkEnable : 9|1@0+ (1,0) [0|1] ""  SGW
 SG_ CapoteInfoForDisplay : 15|6@0+ (1,0) [0|63] ""  SGW
 SG_ DriverHRWindowsSts : 17|2@0+ (1,0) [0|3] ""  BCM,SGW
 SG_ FrontWindowsMovementCmd : 19|2@0+ (1,0) [0|3] ""  BCM,SGW
 SG_ CapoteStsForDisplay : 23|4@0+ (1,0) [0|15] ""  SGW
 SG_ ObstacleDetectionSts : 24|2@0+ (1,0) [0|3] ""  SGW
 SG_ PowerModeSts : 26|2@0+ (1,0) [0|3] ""  BCM,SGW
 SG_ PsgnrHRWindowInitializedSts : 27|1@0+ (1,0) [0|1] ""  BCM,SGW
 SG_ DriverHRWindowInitializedSts : 28|1@0+ (1,0) [0|1] ""  BCM,SGW
 SG_ AutomaticDownCntrl : 29|1@0+ (1,0) [0|1] ""  BCM,SGW
 SG_ PsgnrHRWindowsSts : 31|2@0+ (1,0) [0|3] ""  BCM,SGW
 SG_ BackWindowInitializedSts : 32|1@0+ (1,0) [0|1] ""  SGW
 SG_ BackWindowSts : 34|2@0+ (1,0) [0|3] ""  BCM,SGW
 SG_ NCPAutoStopFailSts : 35|1@0+ (1,0) [0|1] ""  SGW
 SG_ NCPAutoStopEnableSts : 36|1@0+ (1,0) [0|1] ""  SGW
 SG_ NCPAutoStopStaySts : 37|1@0+ (1,0) [0|1] ""  SGW
 SG_ PowerStrikerUpEnable : 38|1@0+ (1,0) [0|1] ""  SGW
 SG_ TonneauCoverSts : 41|2@0+ (1,0) [0|3] ""  SGW
 SG_ STS_NCP_MsgCnt : 51|4@0+ (1,0) [0|15] ""  BCM,NAG,NAP,NCL,SGW
 SG_ CRC_STS_NCP : 63|8@0+ (1,0) [0|255] ""  BCM,NAG,NAP,NCL,SGW

BO_ 970 NPS_INFO: 8 SGW
 SG_ NPS_FrontSensorButtonSts : 23|1@0+ (1,0) [0|1] ""  NSP

BO_ 971 STATUS_ELL_V2: 8 ELL
 SG_ STS_LH_OsHandle_Lock_Active : 0|1@0+ (1,0) [0|1] ""  BCM,SGW
 SG_ STS_LH_OsHandle_Active : 1|1@0+ (1,0) [0|1] ""  BCM,SGW
 SG_ STS_LH_CinchStatus : 2|1@0+ (1,0) [0|1] ""  SGW
 SG_ STS_LH_DoorStatus : 4|2@0+ (1,0) [0|3] ""  BCM,SGW
 SG_ STS_LH_FailSts : 5|1@0+ (1,0) [0|1] ""  BCM,PLG,SGW
 SG_ STS_LH_Latch : 7|2@0+ (1,0) [0|3] ""  BCM,SGW
 SG_ STS_LH_DB_HomeSensor : 8|1@0+ (1,0) [0|1] "" Vector__XXX
 SG_ STS_LH_DB_ClockFail : 9|1@0+ (1,0) [0|1] "" Vector__XXX
 SG_ ELLCrashSts : 10|1@0+ (1,0) [0|1] ""  BCM,ELR,ERL,ERR,SGW
 SG_ STS_LH_HandleSpeedFailSts : 11|1@0+ (1,0) [0|1] ""  SGW
 SG_ STS_LH_ShortDropMode : 12|1@0+ (1,0) [0|1] ""  BCM,SGW
 SG_ STS_LH_PowerModeSts : 14|2@0+ (1,0) [0|3] ""  SGW
 SG_ STS_LH_IsHandle_Active : 15|1@0+ (1,0) [0|1] ""  BCM,SGW
 SG_ STS_LH_DB_CinchStatus : 21|1@0+ (1,0) [0|1] "" Vector__XXX
 SG_ STS_LH_DB_GStatusTEFault : 22|1@0+ (1,0) [0|1] "" Vector__XXX
 SG_ STS_LH_DB_ADC_DataReliable : 23|1@0+ (1,0) [0|1] "" Vector__XXX
 SG_ MessageCounter_STS_LH : 51|4@0+ (1,0) [0|15] ""  BCM,SGW
 SG_ CRC_STS_LH : 63|8@0+ (1,0) [0|255] ""  BCM,SGW

BO_ 972 STATUS_ELR_V2: 8 ELR
 SG_ STS_RH_OsHandle_Lock_Active : 0|1@0+ (1,0) [0|1] ""  BCM,SGW
 SG_ STS_RH_OsHandle_Active : 1|1@0+ (1,0) [0|1] ""  BCM,SGW
 SG_ STS_RH_CinchStatus : 2|1@0+ (1,0) [0|1] ""  SGW
 SG_ STS_RH_DoorStatus : 4|2@0+ (1,0) [0|3] ""  BCM,SGW
 SG_ STS_RH_FailSts : 5|1@0+ (1,0) [0|1] ""  BCM,PLG,SGW
 SG_ STS_RH_Latch : 7|2@0+ (1,0) [0|3] ""  BCM,SGW
 SG_ STS_RH_DB_HomeSensor : 8|1@0+ (1,0) [0|1] "" Vector__XXX
 SG_ STS_RH_DB_ClockFail : 9|1@0+ (1,0) [0|1] "" Vector__XXX
 SG_ ELRCrashSts : 10|1@0+ (1,0) [0|1] ""  BCM,ELL,ERL,ERR,SGW
 SG_ STS_RH_HandleSpeedFailSts : 11|1@0+ (1,0) [0|1] ""  SGW
 SG_ STS_RH_ShortDropMode : 12|1@0+ (1,0) [0|1] ""  BCM,SGW
 SG_ STS_RH_PowerModeSts : 14|2@0+ (1,0) [0|3] ""  SGW
 SG_ STS_RH_IsHandle_Active : 15|1@0+ (1,0) [0|1] ""  BCM,SGW
 SG_ STS_RH_DB_CinchStatus : 21|1@0+ (1,0) [0|1] "" Vector__XXX
 SG_ STS_RH_DB_GStatusTEFault : 22|1@0+ (1,0) [0|1] "" Vector__XXX
 SG_ STS_RH_DB_ADC_DataReliable : 23|1@0+ (1,0) [0|1] "" Vector__XXX
 SG_ MessageCounter_STS_RH : 51|4@0+ (1,0) [0|15] ""  BCM,SGW
 SG_ CRC_STS_RH : 63|8@0+ (1,0) [0|255] ""  BCM,SGW

BO_ 973 STATUS_ERL_V2: 8 ERL
 SG_ STS_LV_OsHandle_Lock_Active : 0|1@0+ (1,0) [0|1] ""  BCM,SGW
 SG_ STS_LV_OsHandle_Active : 1|1@0+ (1,0) [0|1] ""  BCM,SGW
 SG_ STS_LV_CinchStatus : 2|1@0+ (1,0) [0|1] ""  SGW
 SG_ STS_LV_DoorStatus : 4|2@0+ (1,0) [0|3] ""  BCM,SGW
 SG_ STS_LV_FailSts : 5|1@0+ (1,0) [0|1] ""  BCM,PLG,SGW
 SG_ STS_LV_Latch : 7|2@0+ (1,0) [0|3] ""  BCM,SGW
 SG_ STS_LV_PowerDoorSts : 11|4@0+ (1,0) [0|15] ""  BCM,SGW
 SG_ STS_LV_ShortDropMode : 12|1@0+ (1,0) [0|1] ""  BCM,SGW
 SG_ STS_LV_IsHandle_Active : 15|1@0+ (1,0) [0|1] ""  BCM,SGW
 SG_ STS_LV_PowerDoorPosValidData : 16|1@0+ (1,0) [0|1] ""  SGW
 SG_ STS_LV_PowerDoorPosition : 23|7@0+ (1,0) [0|100] ""  SGW
 SG_ ERLCrashSts : 24|1@0+ (1,0) [0|1] ""  BCM,ELL,ELR,ERR,SGW
 SG_ STS_LV_HandleSpeedFailSts : 25|1@0+ (1,0) [0|1] ""  SGW
 SG_ STS_LV_PDFailSts : 26|1@0+ (1,0) [0|1] ""  SGW
 SG_ STS_LV_ChildLockFailSts : 27|1@0+ (1,0) [0|1] ""  BCM,SGW
 SG_ STS_LV_DoorAlert : 29|2@0+ (1,0) [0|3] ""  PLG,SGW
 SG_ STS_LV_ChildLock_Feedback : 30|1@0+ (1,0) [0|1] ""  BCM,SGW
 SG_ STS_LV_ISwitch_Active : 31|1@0+ (1,0) [0|1] ""  BCM,SGW
 SG_ STS_LV_DB_ADC_DataReliable : 32|1@0+ (1,0) [0|1] "" Vector__XXX
 SG_ STS_LV_DB_AccFailSts_FrozenData : 33|1@0+ (1,0) [0|1] "" Vector__XXX
 SG_ STS_LV_DB_ChildLockMemFail : 34|1@0+ (1,0) [0|1] "" Vector__XXX
 SG_ STS_LV_DB_AccFailSts_WrongMode : 35|1@0+ (1,0) [0|1] "" Vector__XXX
 SG_ STS_LV_DB_HomeSensor : 36|1@0+ (1,0) [0|1] "" Vector__XXX
 SG_ STS_LV_DB_AccFailSts_NoAnswer : 37|1@0+ (1,0) [0|1] "" Vector__XXX
 SG_ STS_LV_DB_ClockFail : 38|1@0+ (1,0) [0|1] "" Vector__XXX
 SG_ LReleaseReq : 39|1@0+ (1,0) [0|1] ""  ELL,SGW
 SG_ STS_LV_DB_AccFailSts_StProcFail : 40|1@0+ (1,0) [0|1] "" Vector__XXX
 SG_ STS_LV_DB_FbDriveMode : 43|3@0+ (1,0) [0|7] "" Vector__XXX
 SG_ STS_LV_DB_DoorEngaged : 44|1@0+ (1,0) [0|1] "" Vector__XXX
 SG_ STS_LV_DB_OSSwitchClose : 45|1@0+ (1,0) [0|1] "" Vector__XXX
 SG_ STS_LV_DB_CinchStatus : 46|1@0+ (1,0) [0|1] "" Vector__XXX
 SG_ STS_LV_DB_GStatusTEFault : 47|1@0+ (1,0) [0|1] "" Vector__XXX
 SG_ MessageCounter_STS_LV : 51|4@0+ (1,0) [0|15] ""  BCM,SGW
 SG_ STS_LV_DB_PDUIssue : 54|3@0+ (1,0) [0|7] "" Vector__XXX
 SG_ STS_LV_DB_PDUActive : 55|1@0+ (1,0) [0|1] "" Vector__XXX
 SG_ CRC_STS_LV : 63|8@0+ (1,0) [0|255] ""  BCM,SGW

BO_ 974 STATUS_ERR_V2: 8 ERR
 SG_ STS_RV_OsHandle_Lock_Active : 0|1@0+ (1,0) [0|1] ""  BCM,SGW
 SG_ STS_RV_OsHandle_Active : 1|1@0+ (1,0) [0|1] ""  BCM,SGW
 SG_ STS_RV_CinchStatus : 2|1@0+ (1,0) [0|1] ""  SGW
 SG_ STS_RV_DoorStatus : 4|2@0+ (1,0) [0|3] ""  BCM,SGW
 SG_ STS_RV_FailSts : 5|1@0+ (1,0) [0|1] ""  BCM,PLG,SGW
 SG_ STS_RV_Latch : 7|2@0+ (1,0) [0|3] ""  BCM,SGW
 SG_ STS_RV_PowerDoorSts : 11|4@0+ (1,0) [0|15] ""  BCM,SGW
 SG_ STS_RV_ShortDropMode : 12|1@0+ (1,0) [0|1] ""  BCM,SGW
 SG_ STS_RV_IsHandle_Active : 15|1@0+ (1,0) [0|1] ""  BCM,SGW
 SG_ STS_RV_PowerDoorPosValidData : 16|1@0+ (1,0) [0|1] ""  SGW
 SG_ STS_RV_PowerDoorPosition : 23|7@0+ (1,0) [0|100] ""  SGW
 SG_ ERRCrashSts : 24|1@0+ (1,0) [0|1] ""  BCM,ELL,ELR,ERL,SGW
 SG_ STS_RV_HandleSpeedFailSts : 25|1@0+ (1,0) [0|1] ""  SGW
 SG_ STS_RV_PDFailSts : 26|1@0+ (1,0) [0|1] ""  SGW
 SG_ STS_RV_ChildLockFailSts : 27|1@0+ (1,0) [0|1] ""  BCM,SGW
 SG_ STS_RV_DoorAlert : 29|2@0+ (1,0) [0|3] ""  PLG,SGW
 SG_ STS_RV_ChildLock_Feedback : 30|1@0+ (1,0) [0|1] ""  BCM,SGW
 SG_ STS_RV_ISwitch_Active : 31|1@0+ (1,0) [0|1] ""  BCM,SGW
 SG_ STS_RV_DB_ADC_DataReliable : 32|1@0+ (1,0) [0|1] "" Vector__XXX
 SG_ STS_RV_DB_AccFailSts_FrozenData : 33|1@0+ (1,0) [0|1] "" Vector__XXX
 SG_ STS_RV_DB_ChildLockMemFail : 34|1@0+ (1,0) [0|1] "" Vector__XXX
 SG_ STS_RV_DB_AccFailSts_WrongMode : 35|1@0+ (1,0) [0|1] "" Vector__XXX
 SG_ STS_RV_DB_HomeSensor : 36|1@0+ (1,0) [0|1] "" Vector__XXX
 SG_ STS_RV_DB_AccFailSts_NoAnswer : 37|1@0+ (1,0) [0|1] "" Vector__XXX
 SG_ STS_RV_DB_ClockFail : 38|1@0+ (1,0) [0|1] "" Vector__XXX
 SG_ RReleaseReq : 39|1@0+ (1,0) [0|1] ""  ELR,SGW
 SG_ STS_RV_DB_AccFailSts_StProcFail : 40|1@0+ (1,0) [0|1] "" Vector__XXX
 SG_ STS_RV_DB_FbDriveMode : 43|3@0+ (1,0) [0|7] "" Vector__XXX
 SG_ STS_RV_DB_DoorEngaged : 44|1@0+ (1,0) [0|1] "" Vector__XXX
 SG_ STS_RV_DB_OSSwitchClose : 45|1@0+ (1,0) [0|1] "" Vector__XXX
 SG_ STS_RV_DB_CinchStatus : 46|1@0+ (1,0) [0|1] "" Vector__XXX
 SG_ STS_RV_DB_GStatusTEFault : 47|1@0+ (1,0) [0|1] "" Vector__XXX
 SG_ MessageCounter_STS_RV : 51|4@0+ (1,0) [0|15] ""  BCM,SGW
 SG_ STS_RV_DB_PDUIssue : 54|3@0+ (1,0) [0|7] "" Vector__XXX
 SG_ STS_RV_DB_PDUActive : 55|1@0+ (1,0) [0|1] "" Vector__XXX
 SG_ CRC_STS_RV : 63|8@0+ (1,0) [0|255] ""  BCM,SGW

BO_ 975 NBCtoEL: 8 BCM
 SG_ STS_LH_ShortDropFeedback : 0|1@0+ (1,0) [0|1] ""  ELL
 SG_ RChildlockCommandDoorSts : 1|1@0+ (1,0) [0|1] ""  ERR
 SG_ LChildlockCommandDoorSts : 2|1@0+ (1,0) [0|1] ""  ERL
 SG_ NBC_RV_Unlock : 3|1@0+ (1,0) [0|1] ""  ERR
 SG_ NBC_LV_Unlock : 4|1@0+ (1,0) [0|1] ""  ERL
 SG_ NBC_RH_Unlock : 5|1@0+ (1,0) [0|1] ""  ELR
 SG_ NBC_LH_Unlock : 6|1@0+ (1,0) [0|1] ""  ELL
 SG_ NBC_Lock : 7|1@0+ (1,0) [0|1] ""  ELL,ELR,ERL,ERR
 SG_ STS_RV_ShortDropFeedback : 13|1@0+ (1,0) [0|1] ""  ERR
 SG_ STS_LV_ShortDropFeedback : 14|1@0+ (1,0) [0|1] ""  ERL
 SG_ STS_RH_ShortDropFeedback : 15|1@0+ (1,0) [0|1] ""  ELR
 SG_ Position_FbkWLML : 19|4@0+ (10,0) [0|100] "" Vector__XXX
 SG_ Position_FbkWLMR : 23|4@0+ (10,0) [0|100] "" Vector__XXX
 SG_ Position_FbkWMRR : 43|4@0+ (10,0) [0|100] ""  ERR
 SG_ MessageCounter_NBCtoEL : 51|4@0+ (1,0) [0|15] ""  ELL,ELR,ERL,ERR
 SG_ Position_FbkWMRL : 55|4@0+ (10,0) [0|100] ""  ERL
 SG_ CRC_NBCtoEL : 63|8@0+ (1,0) [0|255] ""  ELL,ELR,ERL,ERR

BO_ 977 STATUS_NPP: 8 BCM
 SG_ PsngrAntiPinchFailSts : 22|1@0+ (1,0) [0|1] ""  SGW
 SG_ WLMPsngrFailSts : 24|1@0+ (1,0) [0|1] ""  SGW
 SG_ PsgnrCmdCompleteCntrl : 27|1@0+ (1,0) [0|1] ""  NCP,SGW
 SG_ PsgnrHRWindowsUpSts : 29|1@0+ (1,0) [0|1] ""  NCP,SGW
 SG_ PsgnrHRWindowsDownSts : 30|1@0+ (1,0) [0|1] ""  NCP,SGW
 SG_ PsngrWindowSts : 37|3@0+ (1,0) [0|7] ""  NAP,NCP,SGW
 SG_ E_LatchPsngrFailSts : 39|1@0+ (1,0) [0|1] ""  SGW

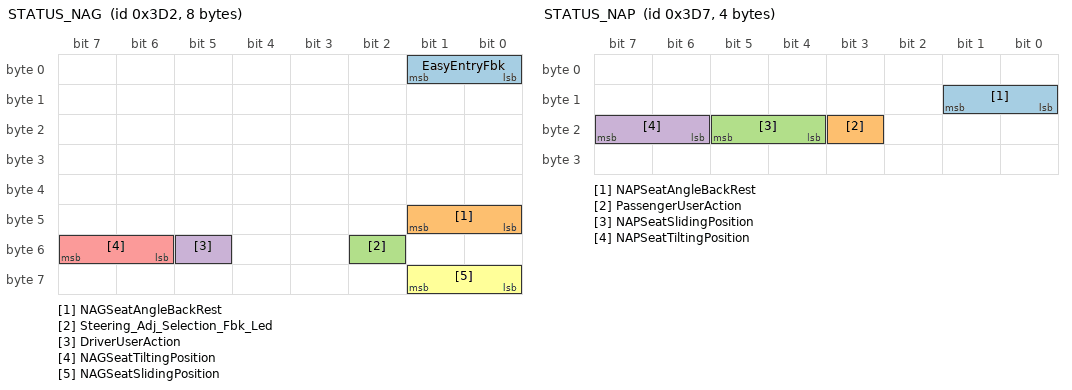
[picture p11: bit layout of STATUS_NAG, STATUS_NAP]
BO_ 978 STATUS_NAG: 8 NAG
 SG_ EasyEntryFbk : 1|2@0+ (1,0) [0|3] ""  SGW
 SG_ NAGSeatAngleBackRest : 41|2@0+ (1,0) [0|3] ""  RSL,RSR,SGW
 SG_ Steering_Adj_Selection_Fbk_Led : 50|1@0+ (1,0) [0|1] ""  BCM
 SG_ DriverUserAction : 53|1@0+ (1,0) [0|1] ""  BCM,SGW
 SG_ NAGSeatTiltingPosition : 55|2@0+ (1,0) [0|3] ""  RSL,RSR,SGW
 SG_ NAGSeatSlidingPosition : 57|2@0+ (1,0) [0|3] ""  RSL,RSR,SGW

BO_ 983 STATUS_NAP: 4 NAP
 SG_ NAPSeatAngleBackRest : 9|2@0+ (1,0) [0|3] ""  RSL,RSR
 SG_ PassengerUserAction : 19|1@0+ (1,0) [0|1] ""  BCM
 SG_ NAPSeatSlidingPosition : 21|2@0+ (1,0) [0|3] ""  RSL,RSR
 SG_ NAPSeatTiltingPosition : 23|2@0+ (1,0) [0|3] ""  RSL,RSR

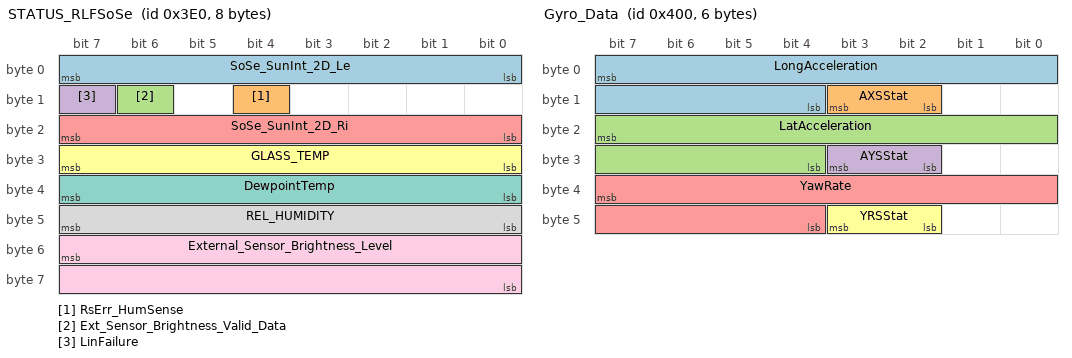
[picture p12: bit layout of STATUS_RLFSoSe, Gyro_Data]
BO_ 992 STATUS_RLFSoSe: 8 BCM
 SG_ SoSe_SunInt_2D_Le : 7|8@0+ (5,0) [0|1275] "W/m2"  NCL,SGW
 SG_ RsErr_HumSense : 12|1@0+ (1,0) [0|1] ""  NCL,SGW
 SG_ Ext_Sensor_Brightness_Valid_Data : 14|1@0+ (1,0) [0|1] ""  SGW
 SG_ LinFailure : 15|1@0+ (1,0) [0|1] ""  NCL,SGW
 SG_ SoSe_SunInt_2D_Ri : 23|8@0+ (5,0) [0|1275] "W/m2"  NCL,SGW
 SG_ GLASS_TEMP : 31|8@0+ (0.5,-40) [-40|87.5] "�C"  NCL,NPR,SGW
 SG_ DewpointTemp : 39|8@0+ (0.5,-40) [-40|87.5] "�C"  NCL,SGW
 SG_ REL_HUMIDITY : 47|8@0+ (0.5,0) [0|127.5] "%"  NCL,SGW
 SG_ External_Sensor_Brightness_Level : 55|16@0+ (1,0) [0|65535] "lux"  SGW

BO_ 1024 Gyro_Data: 6 BCM
 SG_ LongAcceleration : 7|12@0+ (0.02,-40.96) [-40.96|40.92] "m/s�" Vector__XXX
 SG_ AXSStat : 11|2@0+ (1,0) [0|3] "" Vector__XXX
 SG_ LatAcceleration : 23|12@0+ (0.02,-40.96) [-40.96|40.92] "m/s�"  NCP
 SG_ AYSStat : 27|2@0+ (1,0) [0|3] ""  NCP
 SG_ YawRate : 39|12@0+ (0.08,-163.84) [-163.84|163.68] "�/s" Vector__XXX
 SG_ YRSStat : 43|2@0+ (1,0) [0|3] "" Vector__XXX

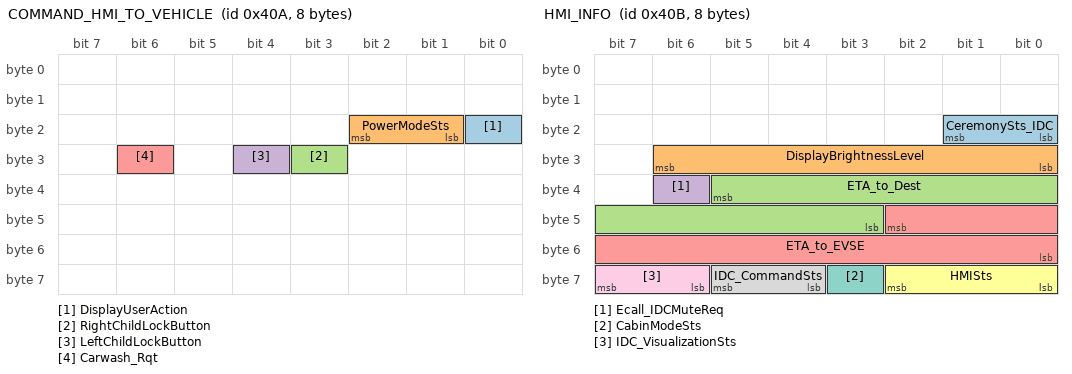
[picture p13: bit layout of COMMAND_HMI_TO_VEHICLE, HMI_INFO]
BO_ 1034 COMMAND_HMI_TO_VEHICLE: 8 SGW
 SG_ DisplayUserAction : 16|1@0+ (1,0) [0|1] ""  BCM
 SG_ PowerModeSts : 18|2@0+ (1,0) [0|3] ""  BCM
 SG_ RightChildLockButton : 27|1@0+ (1,0) [0|1] ""  BCM
 SG_ LeftChildLockButton : 28|1@0+ (1,0) [0|1] ""  BCM
 SG_ Carwash_Rqt : 30|1@0+ (1,0) [0|1] "" Vector__XXX

BO_ 1035 HMI_INFO: 8 SGW
 SG_ CeremonySts_IDC : 17|2@0+ (1,0) [0|3] "" Vector__XXX
 SG_ DisplayBrightnessLevel : 30|7@0+ (1,0) [0|127] "" Vector__XXX
 SG_ ETA_to_Dest : 37|11@0+ (1,0) [0|2047] "min" Vector__XXX
 SG_ Ecall_IDCMuteReq : 38|1@0+ (1,0) [0|1] "" Vector__XXX
 SG_ ETA_to_EVSE : 42|11@0+ (1,0) [0|2047] "min" Vector__XXX
 SG_ HMISts : 58|3@0+ (1,0) [0|3] ""  KHD,N3P,NAG,NAP,NCL,RSH,RSL,RSR
 SG_ CabinModeSts : 59|1@0+ (1,0) [0|1] ""  NCL
 SG_ IDC_CommandSts : 61|2@0+ (1,0) [0|3] "" Vector__XXX
 SG_ IDC_VisualizationSts : 63|2@0+ (1,0) [0|3] "" Vector__XXX

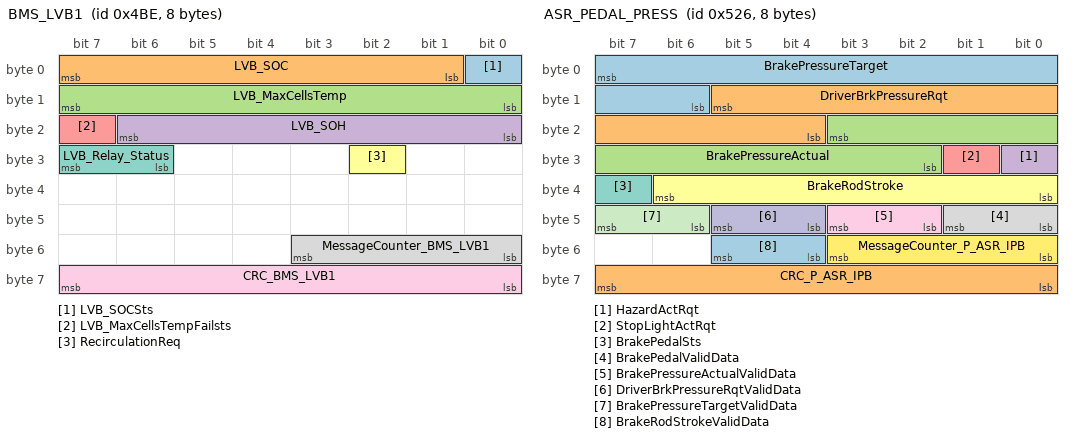
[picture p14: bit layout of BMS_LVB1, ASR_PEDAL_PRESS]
BO_ 1214 BMS_LVB1: 8 SGW
 SG_ LVB_SOCSts : 0|1@0+ (1,0) [0|1] ""  NAG,NAP,NCL,RSL,RSR
 SG_ LVB_SOC : 7|7@0+ (1,0) [0|100] "%"  NAG,NAP,NCL,RSL,RSR
 SG_ LVB_MaxCellsTemp : 15|8@0+ (1,-45) [-45|170] "�C" Vector__XXX
 SG_ LVB_SOH : 22|7@0+ (1,0) [0|100] "%" Vector__XXX
 SG_ LVB_MaxCellsTempFailsts : 23|1@0+ (1,0) [0|1] "" Vector__XXX
 SG_ RecirculationReq : 26|1@0+ (1,0) [0|1] ""  NCL
 SG_ LVB_Relay_Status : 31|2@0+ (1,0) [0|3] "" Vector__XXX
 SG_ MessageCounter_BMS_LVB1 : 51|4@0+ (1,0) [0|15] ""  NAG,NAP,NCL,RSL,RSR
 SG_ CRC_BMS_LVB1 : 63|8@0+ (1,0) [0|255] ""  NAG,NAP,NCL,RSL,RSR

BO_ 1313 STATUS_DOORS: 8 BCM
 SG_ STS_DRS_DriverLatchsts : 1|2@0+ (1,0) [0|3] "" Vector__XXX
 SG_ STS_DRS_PsngrDoorSts : 3|2@0+ (1,0) [0|3] ""  NAG,NAP,RSL,RSR
 SG_ STS_DRS_DriverDoorSts : 5|2@0+ (1,0) [0|3] ""  NAG,NAP,RSL,RSR
 SG_ STS_DRS_VPSTrunkSts : 7|2@0+ (1,0) [0|3] "" Vector__XXX
 SG_ STS_DRS_RearRightLatchsts : 9|2@0+ (1,0) [0|3] "" Vector__XXX
 SG_ STS_DRS_RearLeftDoorSts : 11|2@0+ (1,0) [0|3] ""  NAG,NAP,RSL,RSR
 SG_ STS_DRS_RearRightDoorSts : 13|2@0+ (1,0) [0|3] ""  NAG,NAP,RSL,RSR
 SG_ STS_DRS_PsngrLatchsts : 15|2@0+ (1,0) [0|3] "" Vector__XXX
 SG_ STS_DRS_PsngrWindowSts : 17|3@0+ (1,0) [0|7] "" Vector__XXX
 SG_ STS_DRS_DriverWindowSts : 20|3@0+ (1,0) [0|7] "" Vector__XXX
 SG_ STS_DRS_VPSLockValidData : 21|1@0+ (1,0) [0|1] "" Vector__XXX
 SG_ STS_DRS_RearLeftLatchsts : 23|2@0+ (1,0) [0|3] "" Vector__XXX
 SG_ TrunkInternalButton : 24|1@0+ (1,0) [0|1] "" Vector__XXX
 SG_ STS_DRS_RearRightWindowSts : 27|3@0+ (1,0) [0|7] "" Vector__XXX
 SG_ STS_DRS_RearLeftWindowSts : 30|3@0+ (1,0) [0|7] "" Vector__XXX
 SG_ Interior_Lock : 35|1@0+ (1,0) [0|1] "" Vector__XXX
 SG_ VPSDoorSts : 37|2@0+ (1,0) [0|3] ""  KHD
 SG_ LockUnlockDoors_Button : 38|1@0+ (1,0) [0|1] "" Vector__XXX
 SG_ TrunkExternalButton : 39|1@0+ (1,0) [0|1] "" Vector__XXX
 SG_ MessageCounter_STS_DRS : 51|4@0+ (1,0) [0|15] ""  KHD,NAG,NAP
 SG_ CRC_STS_DRS : 63|8@0+ (1,0) [0|255] ""  KHD,NAG,NAP

BO_ 1318 ASR_PEDAL_PRESS: 8 SGW
 SG_ BrakePressureTarget : 7|10@0+ (0.25,0) [0|200] "bar" Vector__XXX
 SG_ DriverBrkPressureRqt : 13|10@0+ (0.25,0) [0|200] "bar"  KHD
 SG_ BrakePressureActual : 19|10@0+ (0.25,0) [0|200] "bar" Vector__XXX
 SG_ HazardActRqt : 24|1@0+ (1,0) [0|1] "" Vector__XXX
 SG_ StopLightActRqt : 25|1@0+ (1,0) [0|1] "" Vector__XXX
 SG_ BrakeRodStroke : 38|7@0+ (0.2,0) [0|20] "mm" Vector__XXX
 SG_ BrakePedalSts : 39|1@0+ (1,0) [0|1] "" Vector__XXX
 SG_ BrakePedalValidData : 41|2@0+ (1,0) [0|3] "" Vector__XXX
 SG_ BrakePressureActualValidData : 43|2@0+ (1,0) [0|3] "" Vector__XXX
 SG_ DriverBrkPressureRqtValidData : 45|2@0+ (1,0) [0|3] ""  KHD
 SG_ BrakePressureTargetValidData : 47|2@0+ (1,0) [0|3] "" Vector__XXX
 SG_ MessageCounter_P_ASR_IPB : 51|4@0+ (1,0) [0|15] ""  KHD
 SG_ BrakeRodStrokeValidData : 53|2@0+ (1,0) [0|3] "" Vector__XXX
 SG_ CRC_P_ASR_IPB : 63|8@0+ (1,0) [0|255] ""  KHD

BO_ 1351 HAPTIC1: 8 SGW
 SG_ HALF_CHIME_TYPESts : 3|4@0+ (1,0) [0|15] "" Vector__XXX
 SG_ TSR_Fault : 4|1@0+ (1,0) [0|1] "" Vector__XXX
 SG_ TSR_ON : 5|1@0+ (1,0) [0|1] "" Vector__XXX
 SG_ LDWSystemSts : 7|2@0+ (1,0) [0|3] "" Vector__XXX
 SG_ StatusLKA : 9|2@0+ (1,0) [0|3] "" Vector__XXX
 SG_ LDWSensitivitySts : 13|2@0+ (1,0) [0|3] "" Vector__XXX
 SG_ HALF_RF_CHIME_RQSts : 14|1@0+ (1,0) [0|1] "" Vector__XXX
 SG_ HALF_LF_CHIME_RQSts : 15|1@0+ (1,0) [0|1] "" Vector__XXX
 SG_ TSA_ON : 17|2@0+ (1,0) [0|3] "" Vector__XXX
 SG_ HandsOnSts : 21|3@0+ (1,0) [0|7] "" Vector__XXX
 SG_ StatusDDA : 23|2@0+ (1,0) [0|3] "" Vector__XXX
 SG_ ADAS_Unavailable_Camera : 27|2@0+ (1,0) [0|3] "" Vector__XXX
 SG_ TSAMainSign2Fbk : 29|2@0+ (1,0) [0|3] "" Vector__XXX
 SG_ TSASignChangeFbk : 31|2@0+ (1,0) [0|3] "" Vector__XXX
 SG_ DDAW_Level : 35|4@0+ (1,0) [0|15] "" Vector__XXX
 SG_ DrowsinessSts : 37|2@0+ (1,0) [0|3] "" Vector__XXX
 SG_ LDWWarningType_fbk : 39|2@0+ (1,0) [0|3] "" Vector__XXX
 SG_ DisplaySts : 40|8@0+ (1,0) [0|255] "" Vector__XXX
 SG_ SensorBlinded : 41|1@0+ (1,0) [0|1] "" Vector__XXX
 SG_ AHBFault : 42|1@0+ (1,0) [0|1] "" Vector__XXX
 SG_ AHB_ON : 43|1@0+ (1,0) [0|1] "" Vector__XXX
 SG_ TSR_Sts : 46|1@0+ (1,0) [0|1] "" Vector__XXX
 SG_ HALF_heaterSts : 47|1@0+ (1,0) [0|1] ""  NCL
 SG_ DDAW_Index : 48|9@0+ (0.2,0) [0|100] "" Vector__XXX

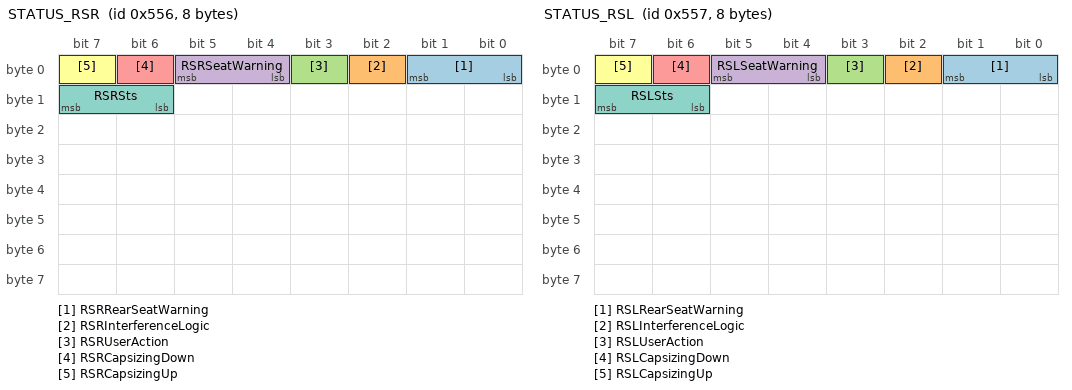
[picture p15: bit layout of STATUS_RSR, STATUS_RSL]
BO_ 1366 STATUS_RSR: 8 RSR
 SG_ RSRRearSeatWarning : 1|2@0+ (1,0) [0|3] ""  SGW
 SG_ RSRInterferenceLogic : 2|1@0+ (1,0) [0|1] ""  NAG,NAP,SGW
 SG_ RSRUserAction : 3|1@0+ (1,0) [0|1] ""  BCM
 SG_ RSRSeatWarning : 5|2@0+ (1,0) [0|3] ""  NAG,NAP
 SG_ RSRCapsizingDown : 6|1@0+ (1,0) [0|1] ""  NAG,NAP,SGW
 SG_ RSRCapsizingUp : 7|1@0+ (1,0) [0|1] ""  NAG,NAP,SGW
 SG_ RSRSts : 15|2@0+ (1,0) [0|3] ""  NAG,NAP

BO_ 1367 STATUS_RSL: 8 RSL
 SG_ RSLRearSeatWarning : 1|2@0+ (1,0) [0|3] ""  SGW
 SG_ RSLInterferenceLogic : 2|1@0+ (1,0) [0|1] ""  NAG,NAP,SGW
 SG_ RSLUserAction : 3|1@0+ (1,0) [0|1] ""  BCM
 SG_ RSLSeatWarning : 5|2@0+ (1,0) [0|3] ""  NAG,NAP
 SG_ RSLCapsizingDown : 6|1@0+ (1,0) [0|1] ""  NAG,NAP,SGW
 SG_ RSLCapsizingUp : 7|1@0+ (1,0) [0|1] ""  NAG,NAP,SGW
 SG_ RSLSts : 15|2@0+ (1,0) [0|3] ""  NAG,NAP

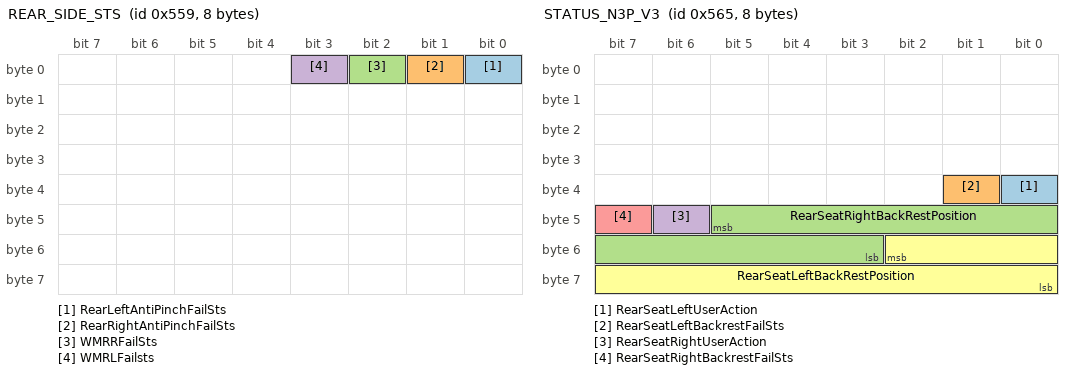
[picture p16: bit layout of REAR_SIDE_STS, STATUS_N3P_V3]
BO_ 1369 REAR_SIDE_STS: 8 BCM
 SG_ RearLeftAntiPinchFailSts : 0|1@0+ (1,0) [0|1] ""  SGW
 SG_ RearRightAntiPinchFailSts : 1|1@0+ (1,0) [0|1] ""  SGW
 SG_ WMRRFailSts : 2|1@0+ (1,0) [0|1] ""  SGW
 SG_ WMRLFailsts : 3|1@0+ (1,0) [0|1] ""  SGW

BO_ 1381 STATUS_N3P_V3: 8 N3P
 SG_ RearSeatLeftUserAction : 32|1@0+ (1,0) [0|1] ""  BCM
 SG_ RearSeatLeftBackrestFailSts : 33|1@0+ (1,0) [0|1] "" Vector__XXX
 SG_ RearSeatRightBackRestPosition : 45|11@0+ (1,0) [0|2047] "" Vector__XXX
 SG_ RearSeatRightUserAction : 46|1@0+ (1,0) [0|1] ""  BCM
 SG_ RearSeatRightBackrestFailSts : 47|1@0+ (1,0) [0|1] "" Vector__XXX
 SG_ RearSeatLeftBackRestPosition : 50|11@0+ (1,0) [0|2047] "" Vector__XXX

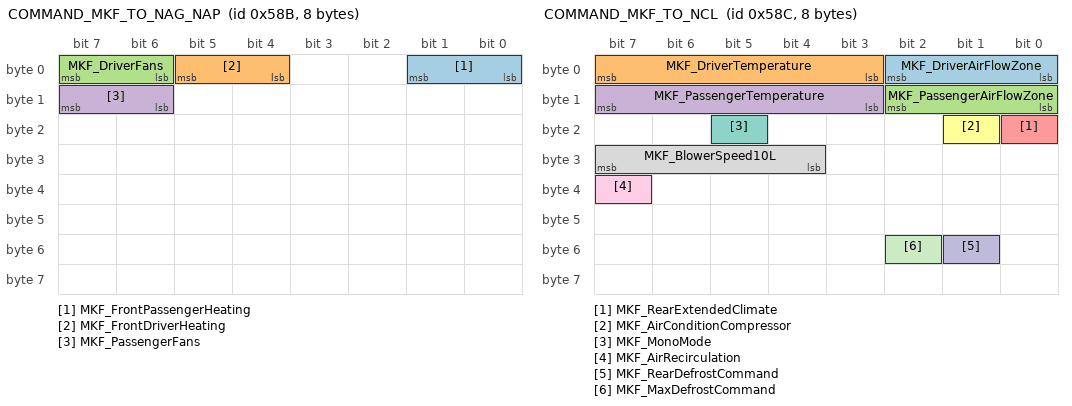
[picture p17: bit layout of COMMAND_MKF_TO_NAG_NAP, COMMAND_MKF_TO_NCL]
BO_ 1419 COMMAND_MKF_TO_NAG_NAP: 8 Vector__XXX
 SG_ MKF_FrontPassengerHeating : 1|2@0+ (1,0) [0|3] ""  NCL
 SG_ MKF_FrontDriverHeating : 5|2@0+ (1,0) [0|3] ""  NCL
 SG_ MKF_DriverFans : 7|2@0+ (1,0) [0|3] ""  NCL
 SG_ MKF_PassengerFans : 15|2@0+ (1,0) [0|3] ""  NCL

BO_ 1420 COMMAND_MKF_TO_NCL: 8 Vector__XXX
 SG_ MKF_DriverAirFlowZone : 2|3@0+ (1,0) [0|7] ""  NCL
 SG_ MKF_DriverTemperature : 7|5@0+ (0.5,15.5) [15.5|28.5] ""  NCL
 SG_ MKF_PassengerAirFlowZone : 10|3@0+ (1,0) [0|7] ""  NCL
 SG_ MKF_PassengerTemperature : 15|5@0+ (0.5,15.5) [15.5|28.5] ""  NCL
 SG_ MKF_RearExtendedClimate : 16|1@0+ (1,0) [0|1] ""  NCL
 SG_ MKF_AirConditionCompressor : 17|1@0+ (1,0) [0|1] ""  NCL
 SG_ MKF_MonoMode : 21|1@0+ (1,0) [0|1] ""  NCL
 SG_ MKF_BlowerSpeed10L : 31|4@0+ (1,0) [0|15] ""  NCL
 SG_ MKF_AirRecirculation : 39|1@0+ (1,0) [0|1] ""  NCL
 SG_ MKF_RearDefrostCommand : 49|1@0+ (1,0) [0|1] ""  NCL
 SG_ MKF_MaxDefrostCommand : 50|1@0+ (1,0) [0|1] ""  NCL

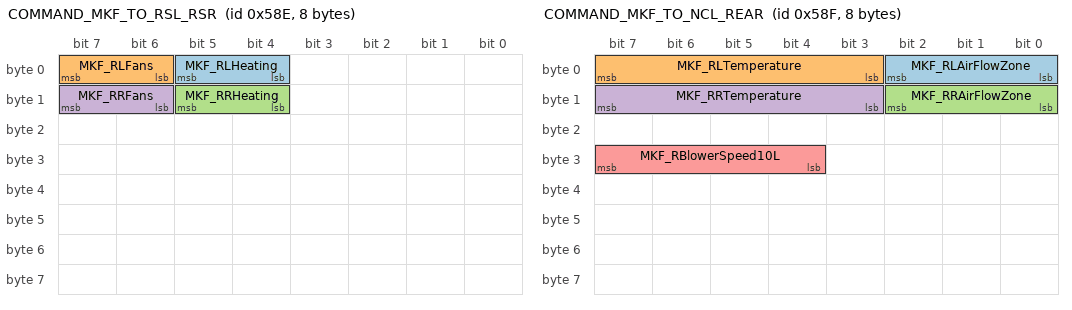
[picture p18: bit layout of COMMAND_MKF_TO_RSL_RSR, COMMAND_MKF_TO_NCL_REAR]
BO_ 1422 COMMAND_MKF_TO_RSL_RSR: 8 Vector__XXX
 SG_ MKF_RLHeating : 5|2@0+ (1,0) [0|3] ""  NCL
 SG_ MKF_RLFans : 7|2@0+ (1,0) [0|3] ""  NCL
 SG_ MKF_RRHeating : 13|2@0+ (1,0) [0|3] ""  NCL
 SG_ MKF_RRFans : 15|2@0+ (1,0) [0|3] ""  NCL

BO_ 1423 COMMAND_MKF_TO_NCL_REAR: 8 Vector__XXX
 SG_ MKF_RLAirFlowZone : 2|3@0+ (1,0) [0|7] ""  NCL
 SG_ MKF_RLTemperature : 7|5@0+ (0.5,15.5) [15.5|28.5] ""  NCL
 SG_ MKF_RRAirFlowZone : 10|3@0+ (1,0) [0|7] ""  NCL
 SG_ MKF_RRTemperature : 15|5@0+ (0.5,15.5) [15.5|28.5] ""  NCL
 SG_ MKF_RBlowerSpeed10L : 31|4@0+ (1,0) [0|15] ""  NCL

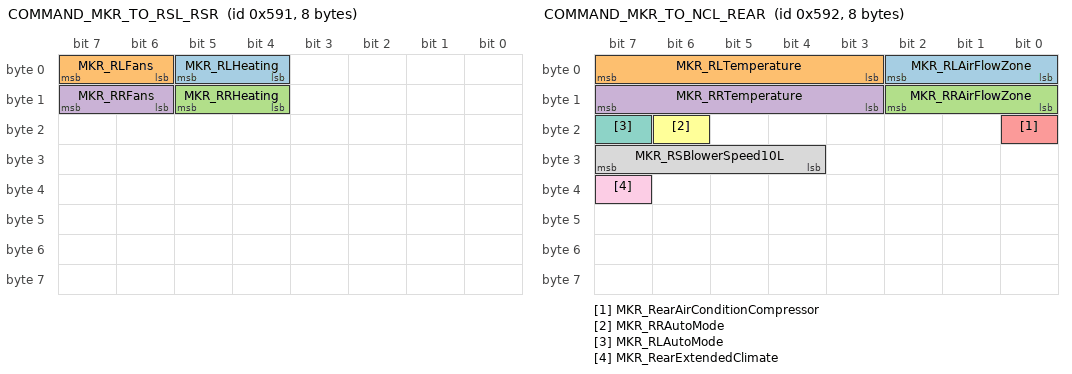
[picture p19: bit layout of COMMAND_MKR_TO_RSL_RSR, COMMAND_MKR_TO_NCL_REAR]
BO_ 1425 COMMAND_MKR_TO_RSL_RSR: 8 Vector__XXX
 SG_ MKR_RLHeating : 5|2@0+ (1,0) [0|3] ""  NCL
 SG_ MKR_RLFans : 7|2@0+ (1,0) [0|3] ""  NCL
 SG_ MKR_RRHeating : 13|2@0+ (1,0) [0|3] ""  NCL
 SG_ MKR_RRFans : 15|2@0+ (1,0) [0|3] ""  NCL

BO_ 1426 COMMAND_MKR_TO_NCL_REAR: 8 Vector__XXX
 SG_ MKR_RLAirFlowZone : 2|3@0+ (1,0) [0|7] ""  NCL
 SG_ MKR_RLTemperature : 7|5@0+ (0.5,15.5) [15.5|28.5] ""  NCL
 SG_ MKR_RRAirFlowZone : 10|3@0+ (1,0) [0|7] ""  NCL
 SG_ MKR_RRTemperature : 15|5@0+ (0.5,15.5) [15.5|28.5] ""  NCL
 SG_ MKR_RearAirConditionCompressor : 16|1@0+ (1,0) [0|1] ""  NCL
 SG_ MKR_RRAutoMode : 22|1@0+ (1,0) [0|1] ""  NCL
 SG_ MKR_RLAutoMode : 23|1@0+ (1,0) [0|1] ""  NCL
 SG_ MKR_RSBlowerSpeed10L : 31|4@0+ (1,0) [0|15] ""  NCL
 SG_ MKR_RearExtendedClimate : 39|1@0+ (1,0) [0|1] ""  NCL

CM_ "Network database provenance and ownership metadata redacted.";
CM_ BU_ BCM "Nodo Body Computer";
CM_ BU_ NCL "Nodo Climatizzatore";
CM_ BU_ NCP "Nodo Capote";
CM_ BU_ NSP "Nodo Sensore Parcheggio";
CM_ BU_ NVO "Nodo Volante";
CM_ SG_ 222 CRC_G "CRC according to SAE J1850 standard ";
CM_ SG_ 359 RFRearFuncReq "Signal name: RFRearFuncReq";
CM_ SG_ 359 FobSearchResult "   7         6       5       4         3              2                 1                 0
|Status|Status|Fault|Trunk|Interior|ExteriorRight|ExteriorLeft|ExteriorRear|

Status is 2 bits encoded as:
  7     6
  0     0   = NO_ACTION
  0     1   = IN_PROGRESS
  1     0   = COMPLETE
  1     1   = TIMEOUT

Fault: 0 = NO_FAULT, 1 = FAULT

Trunk, Interior, ExteriorRight, ExteriorLeft, ExteriorRear: 
0 = NO_FOB_IN_ZONE, 1 = FOB_IN_ZONE";
CM_ SG_ 359 FobSearchResult_LongPressure "Passive Entry system (ASC-PE)";
CM_ SG_ 384 LHRearFogLightFailSts "For 937 only:
The signal name used in 937 is RearFogLightFailSts";
CM_ SG_ 384 LHStopLightFailSts "For 937 only:
The signal name used in 937 is StopLightFailSts";
CM_ SG_ 384 LHFTurnLightFailSts "For 937 only:
The signal name used in 937 is LHTurnLightFailSts";
CM_ SG_ 384 RHFTurnLightFailSts "For 937 only:
The signal name used in 937 is RHTurnLightFailSts";
CM_ SG_ 384 LHRParkTailLightFailSts "For 937 only:
The signal name used in 937 is LHParkTailLightFailSts";
CM_ SG_ 384 RHRParkTailLightFailSts "For 937 only:
The signal name used in 937 is RHParkTailLightFailSts";
CM_ SG_ 416 VPSDriverDoorKeySwitchOrFobCntrl "{For PE: Sig_name = VPSDriverDoorKeySwitchOrFobCntrl}";
CM_ SG_ 518 VRD_RH "Wheel Speed Right Rear.
{For NON-S&S applications: Range_MIN = 2,75}
IF speed < Range_MIN then speed = Range_MIN
Signal not valid for 600ms after startup";
CM_ SG_ 518 LH_WheelDirectionSts "Left Rear.
Signal not valid for 600ms after startup";
CM_ SG_ 518 VRD_LHValidData "Signal not valid for 600ms after startup";
CM_ SG_ 518 RH_WheelDirectionSts "Right Rear.
Signal not valid for 600ms after startup";
CM_ SG_ 518 VRD_RHValidData "Signal not valid for 600ms after startup";
CM_ SG_ 518 VRD_LH "Wheel Speed Left Rear.
{For NON-S&S applications: Range_MIN = 2,75}
IF speed < Range_MIN then speed = Range_MIN
Signal not valid for 600ms after startup";
CM_ SG_ 524 VehicleSpeedVSOSig "Speed is computed based on driven wheels (rear wheels for this vehicle platform)
This value is computed as the STATUS_C-NFR.VehicleSpeed received by NBC.
Signal not valid for 500ms after startup ";
CM_ SG_ 524 VehicleSpeedVSOSigFailSts "Signal not valid for 500ms after startup";
CM_ SG_ 524 MessageCounter_NFR_SPEED "SAE J1850";
CM_ SG_ 524 CRC_NFR_SPEED "According to SAE J1850";
CM_ SG_ 550 VRD_RV "Wheel Speed Right Front.
{For NON-S&S applications: Range_MIN = 2,75}
IF speed < Range_MIN then speed = Range_MIN
Signal not valid for 600ms after startup";
CM_ SG_ 550 LV_WheelDirectionSts "Left Front.
Signal not valid for 600ms after startup";
CM_ SG_ 550 VRD_LVValidData "Signal not valid for 600ms after startup";
CM_ SG_ 550 RV_WheelDirectionSts "Right Front.
Signal not valid for 600ms after startup";
CM_ SG_ 550 VRD_RVValidData "Signal not valid for 600ms after startup";
CM_ SG_ 550 VRD_LV "Wheel Speed Left Front.
{For NON-S&S applications: Range_MIN = 2,75}
IF speed < Range_MIN then speed = Range_MIN
Signal not valid for 600ms after startup";
CM_ SG_ 599 CRC_NAB1 "According SAE J-1850";
CM_ SG_ 672 VehicleSpeed "For 841 the Accuracy is 2%
Signal not valid for 600ms after startup";
CM_ SG_ 672 VehicleSpeedFailSts "Signal not valid for 600ms after startup";
CM_ BO_ 684 "gateway on B-CAN about info from NAS (C-CAN)";
CM_ SG_ 684 LWS_OK "Steering Angle Value Valid";
CM_ SG_ 865 VehDriverReqTrq "Nm @ clutch level";
CM_ SG_ 865 CylCutEnabled "Partial_cylinder_injection_cut_[enabled/not_enabled]_for_DCT";
CM_ SG_ 865 EngineSpeed "For this vehicle application FFFFhex means :
Data NotValid (Failure)
140322: Remove NOTE $FFFF as invalid value";
CM_ SG_ 896 SysEOLSts "See document 'Programmazione EOL e diagnostica'";
CM_ SG_ 896 FuelLevel "Note for F149:
The value 0xFF means signal 'Not Valid'";
CM_ SG_ 906 FogRisk "This signal indicates that the  windscreen fogging conditions are verified";
CM_ SG_ 960 RHatchStsForPLG "It indicates to PLG the status of Trunk_latch microswitch";
CM_ SG_ 969 CapoteInfoForDisplay "The Property and Value details are reported in the F045";
CM_ SG_ 969 CapoteStsForDisplay "The Property and Value details are reported in the F045";
CM_ SG_ 969 NCPAutoStopFailSts "This signal indicates if is present a faillure related to NCP that compromises S&S functionality";
CM_ SG_ 969 NCPAutoStopEnableSts "This signal indicates if the conditions managed by NCP needed for enabling the automatic stop are fulfilled or not";
CM_ SG_ 969 NCPAutoStopStaySts "This signal indicates if the conditions managed by NCP needed for remaining with the engine in automatic stop or not.";
CM_ SG_ 971 MessageCounter_STS_LH "Passive Entry system (ASC-PE)";
CM_ SG_ 971 CRC_STS_LH "According SAE J-1850 - Passive Entry system (ASC-PE)";
CM_ SG_ 972 MessageCounter_STS_RH "Passive Entry system (ASC-PE)";
CM_ SG_ 972 CRC_STS_RH "According SAE J-1850 - Passive Entry system (ASC-PE)";
CM_ SG_ 973 STS_LV_PowerDoorPosition "Passive Entry system (ASC-PE)";
CM_ SG_ 973 MessageCounter_STS_LV "Passive Entry system (ASC-PE)";
CM_ SG_ 973 CRC_STS_LV "According SAE J-1850 - Passive Entry system (ASC-PE)";
CM_ SG_ 974 STS_RV_PowerDoorPosition "Passive Entry system (ASC-PE)";
CM_ SG_ 974 MessageCounter_STS_RV "Passive Entry system (ASC-PE)";
CM_ SG_ 974 CRC_STS_RV "According SAE J-1850 - Passive Entry system (ASC-PE)";
CM_ SG_ 975 CRC_NBCtoEL "According SAE J-1850 - Passive Entry system (ASC-PE)";
CM_ SG_ 1313 STS_DRS_DriverLatchsts "Passive Entry system (ASC-PE)";
CM_ SG_ 1313 STS_DRS_PsngrDoorSts "Passive Entry system (ASC-PE)";
CM_ SG_ 1313 STS_DRS_DriverDoorSts "Passive Entry system (ASC-PE)";
CM_ SG_ 1313 STS_DRS_RearRightLatchsts "Passive Entry system (ASC-PE)";
CM_ SG_ 1313 STS_DRS_RearLeftDoorSts "Passive Entry system (ASC-PE)";
CM_ SG_ 1313 STS_DRS_RearRightDoorSts "Passive Entry system (ASC-PE)";
CM_ SG_ 1313 STS_DRS_PsngrLatchsts "Passive Entry system (ASC-PE)";
CM_ SG_ 1313 STS_DRS_RearLeftLatchsts "Passive Entry system (ASC-PE)";
CM_ SG_ 1313 MessageCounter_STS_DRS "Passive Entry system (ASC-PE)";
CM_ SG_ 1313 CRC_STS_DRS "According SAE J-1850 - Passive Entry system (ASC-PE)";
CM_ SG_ 1318 BrakePressureTarget "Target pressure value available by wire (p_TAR), it includes externnal brake requests (ACC, ?) NOT Available in Back Up mode";
CM_ SG_ 1318 DriverBrkPressureRqt "If valid, it is the master cylinder pressure (pMC), in the 'driver circuit'. Only in by wire mode is related to Brake Rod Stroke (sPTS) by the DBR-curve. In back Up mode reflects the actual pressure in the caliper circuit. ";
CM_ SG_ 1318 BrakePressureActual "Maximum pressure value available at wheels (pS_SP). NOTAvailable in Back Up mode";
CM_ SG_ 1318 StopLightActRqt "This signal is internally used by NBC only. There aren?t any changes for Gateway Function.";
CM_ SG_ 1318 BrakeRodStroke "Available in both 'by wire' and 'Back Up' mode.
Indicate if the Bake pedal is pressed or not AND the amount of the Rod stroke";
CM_ SG_ 1318 BrakePedalSts "Available in both 'by wire' and 'Back Up' mode.
Indicate if the Bake pedal is pressed or not";
CM_ SG_ 1318 DriverBrkPressureRqtValidData "Signal not valid for 800ms after startup";
BA_DEF_ SG_  "GenSigSendType" ENUM  "NotUsed","OnWrite","OnWriteWithRepetition","OnChange","OnChangeWithRepetition","IfActive","IfActiveWithRepetition","NoSigSendType";
BA_DEF_ SG_  "GenSigInactiveValue" INT 0 2147483647;
BA_DEF_ SG_  "GenSigStartValue" INT 0 2147483647;
BA_DEF_ BO_  "DiagState" ENUM  "No","Yes";
BA_DEF_ BO_  "GenMsgDelayTime" INT 0 65535;
BA_DEF_ BO_  "GenMsgCycleTimeFast" INT 0 65535;
BA_DEF_ BO_  "GenMsgStartDelayTime" INT 0 65535;
BA_DEF_ BO_  "GenMsgILSupport" ENUM  "No","Yes";
BA_DEF_ BO_  "GenMsgTimeoutTime" INT 0 10000;
BA_DEF_ BO_  "GenMsgSendType" ENUM  "Cyclic","NotUsed","NotUsed","NotUsed","NotUsed","NotUsed","NotUsed","NotUsed","NoMsgSendType";
BA_DEF_ BO_  "NmMessage" ENUM  "No","Yes";
BA_DEF_ BO_  "Type" ENUM  "P","C","PE","COC","PE_Cntrl","E","E_Cntrl","OC","S","BAF","DC","EM","MM","-";
BA_DEF_ BO_  "Period" INT 0 65535;
BA_DEF_ BU_  "TpOwnSystemEcuNumber" HEX 0 255;
BA_DEF_ BU_  "NwmNodeType" ENUM  "kMaster","kSlave15","kSlave30","none";
BA_DEF_ BU_  "NmNodeType" ENUM  "kMaster","kSlave15","kSlave30","none";
BA_DEF_ BU_  "ILUsed" ENUM  "No","Yes";
BA_DEF_ BU_  "NmNode" ENUM  "No","Yes";
BA_DEF_ BU_  "NmStationAddress" HEX 0 255;
BA_DEF_ BU_  "NodeLayerModules" STRING ;
BA_DEF_ BU_  "Description" STRING ;
BA_DEF_ BU_  "NodeAddress" INT 0 127;
BA_DEF_  "Manufacturer" STRING ;
BA_DEF_  "VersionYear" INT 0 99;
BA_DEF_  "VersionWeek" INT 0 53;
BA_DEF_  "Version" HEX 0 255;
BA_DEF_  "DBName" STRING ;
BA_DEF_  "Baudrate_ARB" INT 0 1000000;
BA_DEF_  "Baudrate_DATA" INT 0 0;
BA_DEF_  "NmType" STRING ;
BA_DEF_  "BusType" STRING ;
BA_DEF_ SG_  "EventTrans" ENUM  "Yes","No";
BA_DEF_ SG_  "Accuracy" STRING ;
BA_DEF_ SG_  "SignalAge" INT 0 100000;
BA_DEF_ SG_  "InitialValue" INT -65536 65535;
BA_DEF_ BO_  "DiagResponse" ENUM  "No","Yes";
BA_DEF_ BO_  "DiagRequest" ENUM  "No","Yes";
BA_DEF_ BO_  "GenMsgCycleTime" INT 0 10000;
BA_DEF_ SG_  "SystemSignalLongSymbol" STRING ;
BA_DEF_DEF_  "GenSigSendType" "NoSigSendType";
BA_DEF_DEF_  "GenSigInactiveValue" 0;
BA_DEF_DEF_  "GenSigStartValue" 0;
BA_DEF_DEF_  "DiagState" "No";
BA_DEF_DEF_  "GenMsgDelayTime" 0;
BA_DEF_DEF_  "GenMsgCycleTimeFast" 0;
BA_DEF_DEF_  "GenMsgStartDelayTime" 0;
BA_DEF_DEF_  "GenMsgILSupport" "No";
BA_DEF_DEF_  "GenMsgTimeoutTime" 0;
BA_DEF_DEF_  "GenMsgSendType" "NoMsgSendType";
BA_DEF_DEF_  "NmMessage" "No";
BA_DEF_DEF_  "Type" "-";
BA_DEF_DEF_  "Period" 0;
BA_DEF_DEF_  "TpOwnSystemEcuNumber" 0;
BA_DEF_DEF_  "NwmNodeType" "none";
BA_DEF_DEF_  "NmNodeType" "none";
BA_DEF_DEF_  "ILUsed" "Yes";
BA_DEF_DEF_  "NmNode" "Yes";
BA_DEF_DEF_  "NmStationAddress" 0;
BA_DEF_DEF_  "NodeLayerModules" "Osek_TP.dll";
BA_DEF_DEF_  "Description" "";
BA_DEF_DEF_  "NodeAddress" 0;
BA_DEF_DEF_  "Manufacturer" "OEM";
BA_DEF_DEF_  "VersionYear" 13;
BA_DEF_DEF_  "VersionWeek" 51;
BA_DEF_DEF_  "Version" 160;
BA_DEF_DEF_  "DBName" "CAN";
BA_DEF_DEF_  "Baudrate_ARB" 500000;
BA_DEF_DEF_  "Baudrate_DATA" 500000;
BA_DEF_DEF_  "NmType" "";
BA_DEF_DEF_  "BusType" "";
BA_DEF_DEF_  "EventTrans" "No";
BA_DEF_DEF_  "Accuracy" "";
BA_DEF_DEF_  "SignalAge" 0;
BA_DEF_DEF_  "InitialValue" 0;
BA_DEF_DEF_  "DiagResponse" "No";
BA_DEF_DEF_  "DiagRequest" "No";
BA_DEF_DEF_  "GenMsgCycleTime" 0;
BA_DEF_DEF_  "SystemSignalLongSymbol" "";
BA_ "BusType" "CAN";
BA_ "NmType" "FIAT";
BA_ "Version" 0;
BA_ "VersionWeek" 0;
BA_ "VersionYear" 0;
BA_ "DBName" "BHCAN";
BA_ "Description" BU_ BCM "Body Computer Module";
BA_ "NmNodeType" BU_ BCM 0;
BA_ "NmStationAddress" BU_ BCM 64;
BA_ "NwmNodeType" BU_ BCM 0;
BA_ "TpOwnSystemEcuNumber" BU_ BCM 64;
BA_ "NmNodeType" BU_ ELL 2;
BA_ "NmStationAddress" BU_ ELL 115;
BA_ "NodeAddress" BU_ ELL 94;
BA_ "NwmNodeType" BU_ ELL 2;
BA_ "TpOwnSystemEcuNumber" BU_ ELL 115;
BA_ "NmNodeType" BU_ ELR 2;
BA_ "NmStationAddress" BU_ ELR 114;
BA_ "NodeAddress" BU_ ELR 95;
BA_ "NwmNodeType" BU_ ELR 2;
BA_ "TpOwnSystemEcuNumber" BU_ ELR 114;
BA_ "NmNodeType" BU_ ERL 2;
BA_ "NmStationAddress" BU_ ERL 124;
BA_ "NodeAddress" BU_ ERL 96;
BA_ "NwmNodeType" BU_ ERL 2;
BA_ "TpOwnSystemEcuNumber" BU_ ERL 124;
BA_ "NmNodeType" BU_ ERR 2;
BA_ "NmStationAddress" BU_ ERR 125;
BA_ "NodeAddress" BU_ ERR 97;
BA_ "NwmNodeType" BU_ ERR 2;
BA_ "TpOwnSystemEcuNumber" BU_ ERR 125;
BA_ "NmNodeType" BU_ KHD 2;
BA_ "NmStationAddress" BU_ KHD 99;
BA_ "NodeAddress" BU_ KHD 87;
BA_ "NwmNodeType" BU_ KHD 2;
BA_ "TpOwnSystemEcuNumber" BU_ KHD 99;
BA_ "Description" BU_ N3P "Nodo 3 posti";
BA_ "NmStationAddress" BU_ N3P 226;
BA_ "NodeAddress" BU_ N3P 121;
BA_ "TpOwnSystemEcuNumber" BU_ N3P 226;
BA_ "Description" BU_ NAG "Nodo Assetto Guidatore";
BA_ "NmNodeType" BU_ NAG 2;
BA_ "NmStationAddress" BU_ NAG 26;
BA_ "NodeAddress" BU_ NAG 18;
BA_ "NwmNodeType" BU_ NAG 2;
BA_ "TpOwnSystemEcuNumber" BU_ NAG 26;
BA_ "Description" BU_ NAP "Nodo Assetto Passeggero";
BA_ "NmNodeType" BU_ NAP 2;
BA_ "NmStationAddress" BU_ NAP 155;
BA_ "NodeAddress" BU_ NAP 23;
BA_ "NwmNodeType" BU_ NAP 2;
BA_ "TpOwnSystemEcuNumber" BU_ NAP 155;
BA_ "NmNodeType" BU_ NCL 2;
BA_ "NmStationAddress" BU_ NCL 8;
BA_ "NodeAddress" BU_ NCL 10;
BA_ "NwmNodeType" BU_ NCL 2;
BA_ "TpOwnSystemEcuNumber" BU_ NCL 8;
BA_ "NmNodeType" BU_ NCP 2;
BA_ "NmStationAddress" BU_ NCP 28;
BA_ "NodeAddress" BU_ NCP 31;
BA_ "NwmNodeType" BU_ NCP 2;
BA_ "TpOwnSystemEcuNumber" BU_ NCP 28;
BA_ "NmStationAddress" BU_ NPR 81;
BA_ "NodeAddress" BU_ NPR 120;
BA_ "TpOwnSystemEcuNumber" BU_ NPR 81;
BA_ "Description" BU_ NSP "Nodo Sensore Parcheggio";
BA_ "NmStationAddress" BU_ NSP 134;
BA_ "NodeAddress" BU_ NSP 24;
BA_ "TpOwnSystemEcuNumber" BU_ NSP 134;
BA_ "NmStationAddress" BU_ NVO 143;
BA_ "NodeAddress" BU_ NVO 4;
BA_ "TpOwnSystemEcuNumber" BU_ NVO 143;
BA_ "Description" BU_ PLG "Portellone";
BA_ "NmStationAddress" BU_ PLG 138;
BA_ "NodeAddress" BU_ PLG 9;
BA_ "TpOwnSystemEcuNumber" BU_ PLG 138;
BA_ "Description" BU_ RSH "Rear Seat Heater";
BA_ "NmNodeType" BU_ RSH 2;
BA_ "NmStationAddress" BU_ RSH 227;
BA_ "NodeAddress" BU_ RSH 122;
BA_ "NwmNodeType" BU_ RSH 2;
BA_ "TpOwnSystemEcuNumber" BU_ RSH 227;
BA_ "Description" BU_ RSL "Rear Seat Left";
BA_ "NmNodeType" BU_ RSL 2;
BA_ "NmStationAddress" BU_ RSL 94;
BA_ "NodeAddress" BU_ RSL 81;
BA_ "NwmNodeType" BU_ RSL 2;
BA_ "TpOwnSystemEcuNumber" BU_ RSL 94;
BA_ "Description" BU_ RSR "Rear Seat Right";
BA_ "NmNodeType" BU_ RSR 2;
BA_ "NmStationAddress" BU_ RSR 95;
BA_ "NodeAddress" BU_ RSR 82;
BA_ "NwmNodeType" BU_ RSR 2;
BA_ "TpOwnSystemEcuNumber" BU_ RSR 95;
BA_ "NmStationAddress" BU_ SGW 203;
BA_ "NodeAddress" BU_ SGW 89;
BA_ "TpOwnSystemEcuNumber" BU_ SGW 203;
BA_ "GenMsgCycleTime" BO_ 222 10;
BA_ "GenMsgILSupport" BO_ 222 1;
BA_ "GenMsgSendType" BO_ 222 0;
BA_ "GenMsgTimeoutTime" BO_ 222 2500;
BA_ "Period" BO_ 222 10;
BA_ "Type" BO_ 222 1;
BA_ "GenMsgCycleTime" BO_ 359 20;
BA_ "GenMsgILSupport" BO_ 359 1;
BA_ "GenMsgSendType" BO_ 359 0;
BA_ "GenMsgTimeoutTime" BO_ 359 2500;
BA_ "Period" BO_ 359 20;
BA_ "Type" BO_ 359 1;
BA_ "GenMsgCycleTime" BO_ 384 250;
BA_ "GenMsgILSupport" BO_ 384 1;
BA_ "GenMsgSendType" BO_ 384 0;
BA_ "GenMsgTimeoutTime" BO_ 384 2500;
BA_ "Period" BO_ 384 250;
BA_ "Type" BO_ 384 3;
BA_ "GenMsgILSupport" BO_ 416 1;
BA_ "GenMsgTimeoutTime" BO_ 416 2500;
BA_ "Type" BO_ 416 8;
BA_ "GenMsgCycleTime" BO_ 499 20;
BA_ "GenMsgILSupport" BO_ 499 1;
BA_ "GenMsgSendType" BO_ 499 0;
BA_ "GenMsgTimeoutTime" BO_ 499 2500;
BA_ "Period" BO_ 499 20;
BA_ "Type" BO_ 499 1;
BA_ "GenMsgCycleTime" BO_ 518 20;
BA_ "GenMsgILSupport" BO_ 518 1;
BA_ "GenMsgSendType" BO_ 518 0;
BA_ "GenMsgTimeoutTime" BO_ 518 2500;
BA_ "Period" BO_ 518 20;
BA_ "Type" BO_ 518 0;
BA_ "GenMsgCycleTime" BO_ 524 20;
BA_ "GenMsgILSupport" BO_ 524 1;
BA_ "GenMsgSendType" BO_ 524 0;
BA_ "GenMsgTimeoutTime" BO_ 524 2500;
BA_ "Period" BO_ 524 20;
BA_ "Type" BO_ 524 0;
BA_ "GenMsgCycleTime" BO_ 550 20;
BA_ "GenMsgILSupport" BO_ 550 1;
BA_ "GenMsgSendType" BO_ 550 0;
BA_ "GenMsgTimeoutTime" BO_ 550 2500;
BA_ "Period" BO_ 550 20;
BA_ "Type" BO_ 550 0;
BA_ "GenMsgCycleTime" BO_ 599 100;
BA_ "GenMsgDelayTime" BO_ 599 10;
BA_ "GenMsgILSupport" BO_ 599 1;
BA_ "GenMsgSendType" BO_ 599 0;
BA_ "GenMsgTimeoutTime" BO_ 599 2500;
BA_ "Period" BO_ 599 100;
BA_ "Type" BO_ 599 3;
BA_ "GenMsgCycleTime" BO_ 631 100;
BA_ "GenMsgILSupport" BO_ 631 1;
BA_ "GenMsgSendType" BO_ 631 0;
BA_ "GenMsgTimeoutTime" BO_ 631 2500;
BA_ "Period" BO_ 631 100;
BA_ "Type" BO_ 631 1;
BA_ "GenMsgCycleTime" BO_ 641 50;
BA_ "GenMsgDelayTime" BO_ 641 10;
BA_ "GenMsgILSupport" BO_ 641 1;
BA_ "GenMsgSendType" BO_ 641 0;
BA_ "GenMsgStartDelayTime" BO_ 641 10;
BA_ "GenMsgTimeoutTime" BO_ 641 2500;
BA_ "Period" BO_ 641 50;
BA_ "Type" BO_ 641 0;
BA_ "GenMsgCycleTime" BO_ 647 100;
BA_ "GenMsgILSupport" BO_ 647 1;
BA_ "GenMsgSendType" BO_ 647 0;
BA_ "GenMsgTimeoutTime" BO_ 647 2500;
BA_ "Period" BO_ 647 100;
BA_ "Type" BO_ 647 1;
BA_ "GenMsgCycleTime" BO_ 648 100;
BA_ "GenMsgILSupport" BO_ 648 1;
BA_ "GenMsgSendType" BO_ 648 0;
BA_ "GenMsgTimeoutTime" BO_ 648 2500;
BA_ "Period" BO_ 648 100;
BA_ "Type" BO_ 648 1;
BA_ "GenMsgCycleTime" BO_ 651 100;
BA_ "GenMsgDelayTime" BO_ 651 10;
BA_ "GenMsgILSupport" BO_ 651 1;
BA_ "GenMsgSendType" BO_ 651 0;
BA_ "GenMsgStartDelayTime" BO_ 651 10;
BA_ "GenMsgTimeoutTime" BO_ 651 2500;
BA_ "Period" BO_ 651 100;
BA_ "Type" BO_ 651 0;
BA_ "GenMsgCycleTime" BO_ 671 100;
BA_ "GenMsgILSupport" BO_ 671 1;
BA_ "GenMsgTimeoutTime" BO_ 671 2500;
BA_ "Period" BO_ 671 100;
BA_ "Type" BO_ 671 1;
BA_ "GenMsgCycleTime" BO_ 672 100;
BA_ "GenMsgDelayTime" BO_ 672 10;
BA_ "GenMsgILSupport" BO_ 672 1;
BA_ "GenMsgSendType" BO_ 672 0;
BA_ "GenMsgStartDelayTime" BO_ 672 10;
BA_ "GenMsgTimeoutTime" BO_ 672 2500;
BA_ "Period" BO_ 672 100;
BA_ "Type" BO_ 672 1;
BA_ "GenMsgCycleTime" BO_ 673 50;
BA_ "GenMsgILSupport" BO_ 673 1;
BA_ "GenMsgSendType" BO_ 673 0;
BA_ "GenMsgTimeoutTime" BO_ 673 2500;
BA_ "Period" BO_ 673 50;
BA_ "Type" BO_ 673 1;
BA_ "GenMsgCycleTime" BO_ 684 100;
BA_ "GenMsgDelayTime" BO_ 684 10;
BA_ "GenMsgILSupport" BO_ 684 1;
BA_ "GenMsgSendType" BO_ 684 0;
BA_ "GenMsgStartDelayTime" BO_ 684 10;
BA_ "GenMsgTimeoutTime" BO_ 684 2500;
BA_ "Period" BO_ 684 100;
BA_ "Type" BO_ 684 0;
BA_ "GenMsgCycleTime" BO_ 761 100;
BA_ "GenMsgILSupport" BO_ 761 1;
BA_ "GenMsgSendType" BO_ 761 0;
BA_ "GenMsgTimeoutTime" BO_ 761 2500;
BA_ "Period" BO_ 761 100;
BA_ "Type" BO_ 761 1;
BA_ "GenMsgCycleTime" BO_ 764 100;
BA_ "GenMsgILSupport" BO_ 764 1;
BA_ "GenMsgSendType" BO_ 764 0;
BA_ "GenMsgTimeoutTime" BO_ 764 2500;
BA_ "Period" BO_ 764 100;
BA_ "Type" BO_ 764 1;
BA_ "GenMsgCycleTime" BO_ 765 100;
BA_ "GenMsgILSupport" BO_ 765 1;
BA_ "GenMsgSendType" BO_ 765 0;
BA_ "GenMsgTimeoutTime" BO_ 765 2500;
BA_ "Period" BO_ 765 100;
BA_ "Type" BO_ 765 1;
BA_ "GenMsgCycleTime" BO_ 865 10;
BA_ "GenMsgILSupport" BO_ 865 1;
BA_ "GenMsgSendType" BO_ 865 0;
BA_ "GenMsgTimeoutTime" BO_ 865 2500;
BA_ "Period" BO_ 865 10;
BA_ "Type" BO_ 865 0;
BA_ "GenMsgCycleTime" BO_ 873 250;
BA_ "GenMsgILSupport" BO_ 873 1;
BA_ "GenMsgSendType" BO_ 873 0;
BA_ "GenMsgTimeoutTime" BO_ 873 2500;
BA_ "Period" BO_ 873 250;
BA_ "Type" BO_ 873 3;
BA_ "GenMsgCycleTime" BO_ 896 250;
BA_ "GenMsgDelayTime" BO_ 896 10;
BA_ "GenMsgILSupport" BO_ 896 1;
BA_ "GenMsgSendType" BO_ 896 0;
BA_ "GenMsgStartDelayTime" BO_ 896 10;
BA_ "GenMsgTimeoutTime" BO_ 896 2500;
BA_ "Period" BO_ 896 250;
BA_ "Type" BO_ 896 3;
BA_ "GenMsgCycleTime" BO_ 904 500;
BA_ "GenMsgILSupport" BO_ 904 1;
BA_ "GenMsgSendType" BO_ 904 0;
BA_ "GenMsgTimeoutTime" BO_ 904 2500;
BA_ "Period" BO_ 904 500;
BA_ "Type" BO_ 904 3;
BA_ "GenMsgCycleTime" BO_ 906 500;
BA_ "GenMsgILSupport" BO_ 906 1;
BA_ "GenMsgSendType" BO_ 906 0;
BA_ "GenMsgTimeoutTime" BO_ 906 2500;
BA_ "Period" BO_ 906 500;
BA_ "Type" BO_ 906 3;
BA_ "GenMsgCycleTime" BO_ 952 1000;
BA_ "GenMsgILSupport" BO_ 952 1;
BA_ "GenMsgSendType" BO_ 952 0;
BA_ "GenMsgTimeoutTime" BO_ 952 2500;
BA_ "Period" BO_ 952 1000;
BA_ "Type" BO_ 952 3;
BA_ "GenMsgCycleTime" BO_ 960 250;
BA_ "GenMsgILSupport" BO_ 960 1;
BA_ "GenMsgSendType" BO_ 960 0;
BA_ "GenMsgTimeoutTime" BO_ 960 2500;
BA_ "Period" BO_ 960 250;
BA_ "Type" BO_ 960 3;
BA_ "GenMsgCycleTime" BO_ 961 250;
BA_ "GenMsgILSupport" BO_ 961 1;
BA_ "GenMsgSendType" BO_ 961 0;
BA_ "GenMsgTimeoutTime" BO_ 961 2500;
BA_ "Period" BO_ 961 250;
BA_ "Type" BO_ 961 3;
BA_ "GenMsgCycleTime" BO_ 963 500;
BA_ "GenMsgILSupport" BO_ 963 1;
BA_ "GenMsgSendType" BO_ 963 0;
BA_ "GenMsgTimeoutTime" BO_ 963 2500;
BA_ "Period" BO_ 963 500;
BA_ "Type" BO_ 963 3;
BA_ "GenMsgCycleTime" BO_ 964 500;
BA_ "GenMsgILSupport" BO_ 964 1;
BA_ "GenMsgSendType" BO_ 964 0;
BA_ "GenMsgTimeoutTime" BO_ 964 2500;
BA_ "Period" BO_ 964 500;
BA_ "Type" BO_ 964 3;
BA_ "GenMsgCycleTime" BO_ 965 500;
BA_ "GenMsgILSupport" BO_ 965 1;
BA_ "GenMsgSendType" BO_ 965 0;
BA_ "GenMsgTimeoutTime" BO_ 965 2500;
BA_ "Period" BO_ 965 500;
BA_ "Type" BO_ 965 3;
BA_ "GenMsgCycleTime" BO_ 967 500;
BA_ "GenMsgILSupport" BO_ 967 1;
BA_ "GenMsgSendType" BO_ 967 0;
BA_ "GenMsgTimeoutTime" BO_ 967 2500;
BA_ "Period" BO_ 967 500;
BA_ "Type" BO_ 967 3;
BA_ "GenMsgCycleTime" BO_ 969 500;
BA_ "GenMsgILSupport" BO_ 969 1;
BA_ "GenMsgSendType" BO_ 969 0;
BA_ "GenMsgTimeoutTime" BO_ 969 2500;
BA_ "Period" BO_ 969 500;
BA_ "Type" BO_ 969 3;
BA_ "GenMsgCycleTime" BO_ 970 250;
BA_ "GenMsgILSupport" BO_ 970 1;
BA_ "GenMsgSendType" BO_ 970 0;
BA_ "GenMsgTimeoutTime" BO_ 970 2500;
BA_ "Period" BO_ 970 250;
BA_ "Type" BO_ 970 3;
BA_ "GenMsgCycleTime" BO_ 971 200;
BA_ "GenMsgILSupport" BO_ 971 1;
BA_ "GenMsgSendType" BO_ 971 0;
BA_ "GenMsgTimeoutTime" BO_ 971 2500;
BA_ "Period" BO_ 971 200;
BA_ "Type" BO_ 971 3;
BA_ "GenMsgCycleTime" BO_ 972 200;
BA_ "GenMsgILSupport" BO_ 972 1;
BA_ "GenMsgSendType" BO_ 972 0;
BA_ "GenMsgTimeoutTime" BO_ 972 2500;
BA_ "Period" BO_ 972 200;
BA_ "Type" BO_ 972 3;
BA_ "GenMsgCycleTime" BO_ 973 200;
BA_ "GenMsgILSupport" BO_ 973 1;
BA_ "GenMsgSendType" BO_ 973 0;
BA_ "GenMsgTimeoutTime" BO_ 973 2500;
BA_ "Period" BO_ 973 200;
BA_ "Type" BO_ 973 3;
BA_ "GenMsgCycleTime" BO_ 974 200;
BA_ "GenMsgILSupport" BO_ 974 1;
BA_ "GenMsgSendType" BO_ 974 0;
BA_ "GenMsgTimeoutTime" BO_ 974 2500;
BA_ "Period" BO_ 974 200;
BA_ "Type" BO_ 974 3;
BA_ "GenMsgCycleTime" BO_ 975 250;
BA_ "GenMsgILSupport" BO_ 975 1;
BA_ "GenMsgSendType" BO_ 975 0;
BA_ "GenMsgTimeoutTime" BO_ 975 2500;
BA_ "Period" BO_ 975 250;
BA_ "Type" BO_ 975 3;
BA_ "GenMsgCycleTime" BO_ 977 500;
BA_ "GenMsgILSupport" BO_ 977 1;
BA_ "GenMsgSendType" BO_ 977 0;
BA_ "GenMsgTimeoutTime" BO_ 977 2500;
BA_ "Period" BO_ 977 500;
BA_ "Type" BO_ 977 3;
BA_ "GenMsgCycleTime" BO_ 978 500;
BA_ "GenMsgILSupport" BO_ 978 1;
BA_ "GenMsgSendType" BO_ 978 0;
BA_ "GenMsgTimeoutTime" BO_ 978 2500;
BA_ "Period" BO_ 978 500;
BA_ "Type" BO_ 978 3;
BA_ "GenMsgCycleTime" BO_ 983 500;
BA_ "GenMsgILSupport" BO_ 983 1;
BA_ "GenMsgSendType" BO_ 983 0;
BA_ "GenMsgTimeoutTime" BO_ 983 2500;
BA_ "Period" BO_ 983 500;
BA_ "Type" BO_ 983 3;
BA_ "GenMsgCycleTime" BO_ 992 250;
BA_ "GenMsgILSupport" BO_ 992 1;
BA_ "GenMsgSendType" BO_ 992 0;
BA_ "GenMsgTimeoutTime" BO_ 992 2500;
BA_ "Period" BO_ 992 250;
BA_ "Type" BO_ 992 0;
BA_ "GenMsgCycleTime" BO_ 1024 60;
BA_ "GenMsgDelayTime" BO_ 1024 10;
BA_ "GenMsgILSupport" BO_ 1024 1;
BA_ "GenMsgSendType" BO_ 1024 0;
BA_ "GenMsgStartDelayTime" BO_ 1024 10;
BA_ "GenMsgTimeoutTime" BO_ 1024 2500;
BA_ "Period" BO_ 1024 60;
BA_ "Type" BO_ 1024 0;
BA_ "GenMsgCycleTime" BO_ 1034 500;
BA_ "GenMsgILSupport" BO_ 1034 1;
BA_ "GenMsgTimeoutTime" BO_ 1034 2500;
BA_ "Period" BO_ 1034 500;
BA_ "Type" BO_ 1034 3;
BA_ "GenMsgCycleTime" BO_ 1035 100;
BA_ "GenMsgILSupport" BO_ 1035 1;
BA_ "GenMsgSendType" BO_ 1035 0;
BA_ "GenMsgTimeoutTime" BO_ 1035 2500;
BA_ "Period" BO_ 1035 100;
BA_ "Type" BO_ 1035 1;
BA_ "GenMsgCycleTime" BO_ 1214 500;
BA_ "GenMsgILSupport" BO_ 1214 1;
BA_ "GenMsgSendType" BO_ 1214 0;
BA_ "GenMsgTimeoutTime" BO_ 1214 2500;
BA_ "Period" BO_ 1214 500;
BA_ "Type" BO_ 1214 1;
BA_ "GenMsgCycleTime" BO_ 1313 100;
BA_ "GenMsgDelayTime" BO_ 1313 10;
BA_ "GenMsgILSupport" BO_ 1313 1;
BA_ "GenMsgSendType" BO_ 1313 0;
BA_ "GenMsgTimeoutTime" BO_ 1313 2500;
BA_ "Period" BO_ 1313 100;
BA_ "Type" BO_ 1313 1;
BA_ "GenMsgCycleTime" BO_ 1318 20;
BA_ "GenMsgILSupport" BO_ 1318 1;
BA_ "GenMsgSendType" BO_ 1318 0;
BA_ "GenMsgTimeoutTime" BO_ 1318 2500;
BA_ "Period" BO_ 1318 20;
BA_ "Type" BO_ 1318 0;
BA_ "GenMsgCycleTime" BO_ 1351 250;
BA_ "GenMsgILSupport" BO_ 1351 1;
BA_ "GenMsgTimeoutTime" BO_ 1351 2500;
BA_ "Period" BO_ 1351 250;
BA_ "Type" BO_ 1351 3;
BA_ "GenMsgCycleTime" BO_ 1366 500;
BA_ "GenMsgILSupport" BO_ 1366 1;
BA_ "GenMsgSendType" BO_ 1366 0;
BA_ "GenMsgStartDelayTime" BO_ 1366 10;
BA_ "GenMsgTimeoutTime" BO_ 1366 2500;
BA_ "Period" BO_ 1366 500;
BA_ "Type" BO_ 1366 0;
BA_ "GenMsgCycleTime" BO_ 1367 500;
BA_ "GenMsgILSupport" BO_ 1367 1;
BA_ "GenMsgSendType" BO_ 1367 0;
BA_ "GenMsgStartDelayTime" BO_ 1367 10;
BA_ "GenMsgTimeoutTime" BO_ 1367 2500;
BA_ "Period" BO_ 1367 500;
BA_ "Type" BO_ 1367 0;
BA_ "GenMsgCycleTime" BO_ 1369 500;
BA_ "GenMsgILSupport" BO_ 1369 1;
BA_ "GenMsgSendType" BO_ 1369 0;
BA_ "GenMsgTimeoutTime" BO_ 1369 2500;
BA_ "Period" BO_ 1369 500;
BA_ "Type" BO_ 1369 3;
BA_ "GenMsgCycleTime" BO_ 1381 500;
BA_ "GenMsgILSupport" BO_ 1381 1;
BA_ "GenMsgSendType" BO_ 1381 0;
BA_ "GenMsgTimeoutTime" BO_ 1381 2500;
BA_ "Period" BO_ 1381 500;
BA_ "Type" BO_ 1381 3;
BA_ "GenMsgILSupport" BO_ 1419 1;
BA_ "GenMsgTimeoutTime" BO_ 1419 2500;
BA_ "Type" BO_ 1419 5;
BA_ "GenMsgILSupport" BO_ 1420 1;
BA_ "GenMsgTimeoutTime" BO_ 1420 2500;
BA_ "Type" BO_ 1420 5;
BA_ "GenMsgILSupport" BO_ 1422 1;
BA_ "GenMsgTimeoutTime" BO_ 1422 2500;
BA_ "Type" BO_ 1422 5;
BA_ "GenMsgILSupport" BO_ 1423 1;
BA_ "GenMsgTimeoutTime" BO_ 1423 2500;
BA_ "Type" BO_ 1423 5;
BA_ "GenMsgILSupport" BO_ 1425 1;
BA_ "GenMsgTimeoutTime" BO_ 1425 2500;
BA_ "Type" BO_ 1425 5;
BA_ "GenMsgILSupport" BO_ 1426 1;
BA_ "GenMsgTimeoutTime" BO_ 1426 2500;
BA_ "Type" BO_ 1426 5;
BA_ "Accuracy" SG_ 222 LwsAngle "� 2,8 �";
BA_ "GenSigStartValue" SG_ 222 LwsAngle 7200;
BA_ "SignalAge" SG_ 222 LwsAngle 10;
BA_ "Accuracy" SG_ 222 LwsSpeed "15 �/S";
BA_ "GenSigStartValue" SG_ 222 LwsSpeed 2000;
BA_ "SignalAge" SG_ 222 LwsSpeed 10;
BA_ "SignalAge" SG_ 222 MessageCounter_G 10;
BA_ "EventTrans" SG_ 384 FrontWindWiperCarWashErrSts 0;
BA_ "GenSigSendType" SG_ 384 FrontWindWiperCarWashErrSts 3;
BA_ "EventTrans" SG_ 384 RearWindowWiperMotorErrorSts 0;
BA_ "GenSigSendType" SG_ 384 RearWindowWiperMotorErrorSts 3;
BA_ "EventTrans" SG_ 384 RearWindowWiperSts 0;
BA_ "GenSigSendType" SG_ 384 RearWindowWiperSts 3;
BA_ "EventTrans" SG_ 384 FrontWindshieldWiperMotErrSts 0;
BA_ "GenSigSendType" SG_ 384 FrontWindshieldWiperMotErrSts 3;
BA_ "GenSigSendType" SG_ 384 NightDaySts 3;
BA_ "EventTrans" SG_ 384 RearFogLightSts 0;
BA_ "GenSigSendType" SG_ 384 RearFogLightSts 3;
BA_ "EventTrans" SG_ 384 AHBFeature 0;
BA_ "GenSigSendType" SG_ 384 AHBFeature 3;
BA_ "EventTrans" SG_ 384 LowBeamSts 0;
BA_ "GenSigSendType" SG_ 384 LowBeamSts 3;
BA_ "EventTrans" SG_ 384 HighBeamSts 0;
BA_ "GenSigSendType" SG_ 384 HighBeamSts 3;
BA_ "EventTrans" SG_ 384 LHParkTailLightSts 0;
BA_ "GenSigSendType" SG_ 384 LHParkTailLightSts 3;
BA_ "EventTrans" SG_ 384 RHParkTailLightSts 0;
BA_ "GenSigSendType" SG_ 384 RHParkTailLightSts 3;
BA_ "EventTrans" SG_ 384 RHeatedWindowSts 0;
BA_ "GenSigSendType" SG_ 384 RHeatedWindowSts 3;
BA_ "EventTrans" SG_ 384 RHTurnSignalSts 0;
BA_ "GenSigSendType" SG_ 384 RHTurnSignalSts 3;
BA_ "EventTrans" SG_ 384 LHTurnSignalSts 0;
BA_ "GenSigSendType" SG_ 384 LHTurnSignalSts 3;
BA_ "EventTrans" SG_ 384 ExternalLightsSts 0;
BA_ "GenSigSendType" SG_ 384 ExternalLightsSts 3;
BA_ "EventTrans" SG_ 416 VPSDriverDoorKeySwitchOrFobCntrl 0;
BA_ "GenSigSendType" SG_ 416 VPSDriverDoorKeySwitchOrFobCntrl 1;
BA_ "EventTrans" SG_ 416 VPSAIAlarmCauseCntrl 0;
BA_ "GenSigSendType" SG_ 416 VPSAIAlarmCauseCntrl 1;
BA_ "EventTrans" SG_ 416 VPSUSAlarmCauseCntrl 0;
BA_ "GenSigSendType" SG_ 416 VPSUSAlarmCauseCntrl 1;
BA_ "EventTrans" SG_ 416 VPSBonnetAlarmCauseCntrl 0;
BA_ "GenSigSendType" SG_ 416 VPSBonnetAlarmCauseCntrl 1;
BA_ "EventTrans" SG_ 416 VPSTrunkAlarmCauseCntrl 0;
BA_ "GenSigSendType" SG_ 416 VPSTrunkAlarmCauseCntrl 1;
BA_ "EventTrans" SG_ 416 VPSDoorsAlarmCauseCntrl 0;
BA_ "GenSigSendType" SG_ 416 VPSDoorsAlarmCauseCntrl 1;
BA_ "EventTrans" SG_ 416 VPSAlarmFailCntrl 0;
BA_ "GenSigSendType" SG_ 416 VPSAlarmFailCntrl 1;
BA_ "EventTrans" SG_ 416 VPSCIDNotFoundCntrl 0;
BA_ "GenSigSendType" SG_ 416 VPSCIDNotFoundCntrl 1;
BA_ "EventTrans" SG_ 416 VPSElectricalAlarmCauseCntrl 0;
BA_ "GenSigSendType" SG_ 416 VPSElectricalAlarmCauseCntrl 1;
BA_ "GenSigStartValue" SG_ 499 KeyHolderPosition 1;
BA_ "InitialValue" SG_ 499 KeyHolderPosition 1;
BA_ "Accuracy" SG_ 518 VRD_RH "� 0,0625 km/h";
BA_ "SignalAge" SG_ 518 VRD_RH 10;
BA_ "GenSigStartValue" SG_ 518 LH_WheelDirectionSts 3;
BA_ "InitialValue" SG_ 518 LH_WheelDirectionSts 3;
BA_ "GenSigStartValue" SG_ 518 VRD_LHValidData 1;
BA_ "InitialValue" SG_ 518 VRD_LHValidData 1;
BA_ "GenSigStartValue" SG_ 518 RH_WheelDirectionSts 3;
BA_ "InitialValue" SG_ 518 RH_WheelDirectionSts 3;
BA_ "GenSigStartValue" SG_ 518 VRD_RHValidData 1;
BA_ "InitialValue" SG_ 518 VRD_RHValidData 1;
BA_ "Accuracy" SG_ 518 VRD_LH "� 0,0625 km/h";
BA_ "SignalAge" SG_ 518 VRD_LH 10;
BA_ "Accuracy" SG_ 524 VehicleSpeed_ASILx "� 0,0625km/h";
BA_ "SignalAge" SG_ 524 VehicleSpeed_ASILx 10;
BA_ "Accuracy" SG_ 524 VehicleSpeedVSOSig "� 0,0625km/h";
BA_ "SignalAge" SG_ 524 VehicleSpeedVSOSig 10;
BA_ "GenSigStartValue" SG_ 524 VehicleSpeed_ASILxFailSts 1;
BA_ "InitialValue" SG_ 524 VehicleSpeed_ASILxFailSts 1;
BA_ "GenSigStartValue" SG_ 524 VehicleSpeedVSOSigFailSts 1;
BA_ "InitialValue" SG_ 524 VehicleSpeedVSOSigFailSts 1;
BA_ "Accuracy" SG_ 524 NFR_Speed_FA "� 0,0625km/h";
BA_ "SignalAge" SG_ 524 NFR_Speed_FA 20;
BA_ "GenSigStartValue" SG_ 524 NFR_Speed_FA_FailSts 1;
BA_ "InitialValue" SG_ 524 NFR_Speed_FA_FailSts 1;
BA_ "SignalAge" SG_ 524 NFR_Speed_FA_FailSts 20;
BA_ "Accuracy" SG_ 550 VRD_RV "� 0,0625 km/h";
BA_ "SignalAge" SG_ 550 VRD_RV 10;
BA_ "GenSigStartValue" SG_ 550 LV_WheelDirectionSts 3;
BA_ "InitialValue" SG_ 550 LV_WheelDirectionSts 3;
BA_ "GenSigStartValue" SG_ 550 VRD_LVValidData 1;
BA_ "InitialValue" SG_ 550 VRD_LVValidData 1;
BA_ "GenSigStartValue" SG_ 550 RV_WheelDirectionSts 3;
BA_ "InitialValue" SG_ 550 RV_WheelDirectionSts 3;
BA_ "GenSigStartValue" SG_ 550 VRD_RVValidData 1;
BA_ "InitialValue" SG_ 550 VRD_RVValidData 1;
BA_ "Accuracy" SG_ 550 VRD_LV "� 0,0625 km/h";
BA_ "SignalAge" SG_ 550 VRD_LV 10;
BA_ "GenSigStartValue" SG_ 599 SBR2RowCentralSeatBuckleFailSts 3;
BA_ "InitialValue" SG_ 599 SBR2RowCentralSeatBuckleFailSts 3;
BA_ "EventTrans" SG_ 599 AirBagFailSts 0;
BA_ "GenSigSendType" SG_ 599 AirBagFailSts 3;
BA_ "GenSigStartValue" SG_ 599 AirBagFailSts 2;
BA_ "InitialValue" SG_ 599 AirBagFailSts 2;
BA_ "EventTrans" SG_ 599 SBR1RowDriverSeatFailSts 0;
BA_ "GenSigSendType" SG_ 599 SBR1RowDriverSeatFailSts 3;
BA_ "GenSigStartValue" SG_ 599 SBR1RowDriverSeatFailSts 3;
BA_ "InitialValue" SG_ 599 SBR1RowDriverSeatFailSts 3;
BA_ "EventTrans" SG_ 599 SBR1RowDriverSeatConfigSts 0;
BA_ "GenSigSendType" SG_ 599 SBR1RowDriverSeatConfigSts 3;
BA_ "GenSigStartValue" SG_ 599 SBR2RowCentralSeatSts 7;
BA_ "InitialValue" SG_ 599 SBR2RowCentralSeatSts 7;
BA_ "EventTrans" SG_ 599 SBR1RowCentralSeatPPDFailSts 0;
BA_ "GenSigSendType" SG_ 599 SBR1RowCentralSeatPPDFailSts 3;
BA_ "GenSigStartValue" SG_ 599 SBR1RowCentralSeatPPDFailSts 3;
BA_ "InitialValue" SG_ 599 SBR1RowCentralSeatPPDFailSts 3;
BA_ "EventTrans" SG_ 599 SBR1RowPsngrSeatPPDFailSts 0;
BA_ "GenSigSendType" SG_ 599 SBR1RowPsngrSeatPPDFailSts 3;
BA_ "GenSigStartValue" SG_ 599 SBR1RowPsngrSeatPPDFailSts 3;
BA_ "InitialValue" SG_ 599 SBR1RowPsngrSeatPPDFailSts 3;
BA_ "EventTrans" SG_ 599 SBR1RowPsngrSeatBuckleFailSts 0;
BA_ "GenSigSendType" SG_ 599 SBR1RowPsngrSeatBuckleFailSts 3;
BA_ "GenSigStartValue" SG_ 599 SBR1RowPsngrSeatBuckleFailSts 3;
BA_ "InitialValue" SG_ 599 SBR1RowPsngrSeatBuckleFailSts 3;
BA_ "EventTrans" SG_ 599 SBR1RowPsngrSeatConfigSts 0;
BA_ "GenSigSendType" SG_ 599 SBR1RowPsngrSeatConfigSts 3;
BA_ "EventTrans" SG_ 599 SBR1RowDriverSeatSts 0;
BA_ "GenSigSendType" SG_ 599 SBR1RowDriverSeatSts 3;
BA_ "GenSigStartValue" SG_ 599 SBR1RowDriverSeatSts 3;
BA_ "InitialValue" SG_ 599 SBR1RowDriverSeatSts 3;
BA_ "EventTrans" SG_ 599 SBR2RowLeftSeatSts 0;
BA_ "GenSigSendType" SG_ 599 SBR2RowLeftSeatSts 3;
BA_ "GenSigStartValue" SG_ 599 SBR2RowLeftSeatSts 3;
BA_ "InitialValue" SG_ 599 SBR2RowLeftSeatSts 3;
BA_ "EventTrans" SG_ 599 SBR2RowRightSeatFailSts 0;
BA_ "GenSigSendType" SG_ 599 SBR2RowRightSeatFailSts 3;
BA_ "GenSigStartValue" SG_ 599 SBR2RowRightSeatFailSts 3;
BA_ "InitialValue" SG_ 599 SBR2RowRightSeatFailSts 3;
BA_ "EventTrans" SG_ 599 SBR2RowLeftSeatFailSts 0;
BA_ "GenSigSendType" SG_ 599 SBR2RowLeftSeatFailSts 3;
BA_ "GenSigStartValue" SG_ 599 SBR2RowLeftSeatFailSts 3;
BA_ "InitialValue" SG_ 599 SBR2RowLeftSeatFailSts 3;
BA_ "EventTrans" SG_ 599 SBR1RowPsngrSeatSts 0;
BA_ "GenSigSendType" SG_ 599 SBR1RowPsngrSeatSts 3;
BA_ "GenSigStartValue" SG_ 599 SBR1RowPsngrSeatSts 7;
BA_ "InitialValue" SG_ 599 SBR1RowPsngrSeatSts 7;
BA_ "EventTrans" SG_ 599 CrashOutputSts 0;
BA_ "GenSigSendType" SG_ 599 CrashOutputSts 3;
BA_ "EventTrans" SG_ 599 SBR2RowRightSeatSts 0;
BA_ "GenSigSendType" SG_ 599 SBR2RowRightSeatSts 3;
BA_ "GenSigStartValue" SG_ 599 SBR2RowRightSeatSts 3;
BA_ "InitialValue" SG_ 599 SBR2RowRightSeatSts 3;
BA_ "SignalAge" SG_ 599 MessageCounter_NAB1 10;
BA_ "EventTrans" SG_ 599 CrashOutputValidData 0;
BA_ "GenSigSendType" SG_ 599 CrashOutputValidData 3;
BA_ "SignalAge" SG_ 599 CRC_NAB1 10;
BA_ "EventTrans" SG_ 599 AirBagWarningPADLampOnSts 0;
BA_ "GenSigSendType" SG_ 599 AirBagWarningPADLampOnSts 3;
BA_ "EventTrans" SG_ 599 AirBagWarningPADLampOffSts 0;
BA_ "GenSigSendType" SG_ 599 AirBagWarningPADLampOffSts 3;
BA_ "EventTrans" SG_ 599 SBR2RowRightSeatConfigSts 0;
BA_ "GenSigSendType" SG_ 599 SBR2RowRightSeatConfigSts 3;
BA_ "EventTrans" SG_ 599 SBR2RowLeftSeatConfigSts 0;
BA_ "GenSigSendType" SG_ 599 SBR2RowLeftSeatConfigSts 3;
BA_ "EventTrans" SG_ 599 Ppd_psngr_info 0;
BA_ "GenSigSendType" SG_ 599 Ppd_psngr_info 3;
BA_ "EventTrans" SG_ 599 AirBagWarningLampSts 0;
BA_ "GenSigSendType" SG_ 599 AirBagWarningLampSts 3;
BA_ "SystemSignalLongSymbol" SG_ 599 AirBagWarningPADPassengerAirbagS "AirBagWarningPADPassengerAirbagSts";
BA_ "GenSigStartValue" SG_ 631 T_InHeaterCore 40;
BA_ "InitialValue" SG_ 631 T_InHeaterCore 20;
BA_ "GenSigStartValue" SG_ 647 T_InFrontEvapHVAC 30;
BA_ "InitialValue" SG_ 647 T_InFrontEvapHVAC 20;
BA_ "GenSigStartValue" SG_ 647 T_InRearEvapHVAC 30;
BA_ "InitialValue" SG_ 647 T_InRearEvapHVAC 20;
BA_ "GenSigStartValue" SG_ 647 T_outFrontEvapHVAC 300;
BA_ "InitialValue" SG_ 647 T_outFrontEvapHVAC 20;
BA_ "GenSigStartValue" SG_ 647 T_outRearEvapHVAC 300;
BA_ "InitialValue" SG_ 647 T_outRearEvapHVAC 20;
BA_ "GenSigStartValue" SG_ 648 T_TargetInHeaterCore 40;
BA_ "InitialValue" SG_ 648 T_TargetInHeaterCore 20;
BA_ "GenSigStartValue" SG_ 648 T_TargetOutEvapHVAC 20;
BA_ "InitialValue" SG_ 648 T_TargetOutEvapHVAC 10;
BA_ "GenSigStartValue" SG_ 671 SuspensionSetupSts 1;
BA_ "InitialValue" SG_ 671 SuspensionSetupSts 1;
BA_ "Accuracy" SG_ 672 VehicleSpeed "� 1/16 km/h";
BA_ "SignalAge" SG_ 672 VehicleSpeed 100;
BA_ "GenSigStartValue" SG_ 672 VehicleSpeedFailSts 1;
BA_ "InitialValue" SG_ 672 VehicleSpeedFailSts 1;
BA_ "Accuracy" SG_ 672 TravelDistance "� 0,7%";
BA_ "Accuracy" SG_ 684 LWS_Angle "� 2,5�";
BA_ "SignalAge" SG_ 684 LWS_Angle 10;
BA_ "InitialValue" SG_ 865 VehDriverReqTrq -508;
BA_ "GenSigStartValue" SG_ 865 EngineSpeedValidData 1;
BA_ "InitialValue" SG_ 865 EngineSpeedValidData 1;
BA_ "Accuracy" SG_ 865 EngineSpeed "� 1/min";
BA_ "EventTrans" SG_ 873 PLGSts 0;
BA_ "GenSigSendType" SG_ 873 PLGSts 3;
BA_ "EventTrans" SG_ 873 PLGInfoForDisplay 0;
BA_ "GenSigSendType" SG_ 873 PLGInfoForDisplay 3;
BA_ "Accuracy" SG_ 873 PLGPosition "1";
BA_ "EventTrans" SG_ 873 PLGPosition 0;
BA_ "GenSigSendType" SG_ 873 PLGPosition 3;
BA_ "SignalAge" SG_ 873 PLGPosition 50;
BA_ "EventTrans" SG_ 873 PLGPositionValidData 0;
BA_ "GenSigSendType" SG_ 873 PLGPositionValidData 3;
BA_ "Accuracy" SG_ 873 PLGGaragePosition "1";
BA_ "GenSigStartValue" SG_ 873 PLGGaragePosition 50;
BA_ "InitialValue" SG_ 873 PLGGaragePosition 50;
BA_ "SignalAge" SG_ 873 PLGGaragePosition 50;
BA_ "EventTrans" SG_ 873 PLGBlockingDetection 0;
BA_ "GenSigSendType" SG_ 873 PLGBlockingDetection 3;
BA_ "EventTrans" SG_ 873 PLGFailSts 0;
BA_ "GenSigSendType" SG_ 873 PLGFailSts 3;
BA_ "EventTrans" SG_ 873 PLGButtonSts 0;
BA_ "GenSigSendType" SG_ 873 PLGButtonSts 3;
BA_ "EventTrans" SG_ 873 PLGCloseLock 0;
BA_ "GenSigSendType" SG_ 873 PLGCloseLock 3;
BA_ "EventTrans" SG_ 896 InternalLightSts 0;
BA_ "GenSigSendType" SG_ 896 InternalLightSts 3;
BA_ "EventTrans" SG_ 896 WishWashSts 0;
BA_ "GenSigSendType" SG_ 896 WishWashSts 3;
BA_ "GenSigSendType" SG_ 896 PsngrDoorSts 3;
BA_ "EventTrans" SG_ 896 PLGCommand2 0;
BA_ "GenSigSendType" SG_ 896 PLGCommand2 3;
BA_ "GenSigStartValue" SG_ 896 PLGCommand2 1;
BA_ "InitialValue" SG_ 896 PLGCommand2 1;
BA_ "EventTrans" SG_ 896 RhatchSts 0;
BA_ "GenSigSendType" SG_ 896 RhatchSts 3;
BA_ "EventTrans" SG_ 896 BonnetSts 0;
BA_ "GenSigSendType" SG_ 896 BonnetSts 3;
BA_ "EventTrans" SG_ 896 ReverseGearBCSts 0;
BA_ "GenSigSendType" SG_ 896 ReverseGearBCSts 3;
BA_ "EventTrans" SG_ 896 KeySts 0;
BA_ "GenSigSendType" SG_ 896 KeySts 3;
BA_ "Accuracy" SG_ 896 BatteryVoltageLevel "�0,05V";
BA_ "SignalAge" SG_ 896 BatteryVoltageLevel 1000;
BA_ "EventTrans" SG_ 896 NBCFISSts 0;
BA_ "GenSigSendType" SG_ 896 NBCFISSts 3;
BA_ "EventTrans" SG_ 896 LowFuelWarningSts 0;
BA_ "GenSigSendType" SG_ 896 LowFuelWarningSts 3;
BA_ "Accuracy" SG_ 896 FuelLevel "�2,5 at 17,5%";
BA_ "EventTrans" SG_ 896 IMMOCodeWarningLightSts 0;
BA_ "GenSigSendType" SG_ 896 IMMOCodeWarningLightSts 3;
BA_ "GenSigStartValue" SG_ 896 IMMOCodeWarningLightSts 18;
BA_ "InitialValue" SG_ 896 IMMOCodeWarningLightSts 18;
BA_ "Accuracy" SG_ 904 ExternalTemperature "0,5 �C (-10 �C / +20�C)";
BA_ "GenSigStartValue" SG_ 904 ExternalTemperature 1;
BA_ "InitialValue" SG_ 904 ExternalTemperature -39;
BA_ "SignalAge" SG_ 904 ExternalTemperature 50;
BA_ "EventTrans" SG_ 904 DriverAntiPinchFailSts 0;
BA_ "GenSigSendType" SG_ 904 DriverAntiPinchFailSts 3;
BA_ "EventTrans" SG_ 904 DriverHRWindowsUpSts 0;
BA_ "GenSigSendType" SG_ 904 DriverHRWindowsUpSts 3;
BA_ "EventTrans" SG_ 904 DriverHRWindowsDownSts 0;
BA_ "GenSigSendType" SG_ 904 DriverHRWindowsDownSts 3;
BA_ "EventTrans" SG_ 904 DriverCmdCompleteCntrl 0;
BA_ "GenSigSendType" SG_ 904 DriverCmdCompleteCntrl 3;
BA_ "EventTrans" SG_ 904 FoldMirrorSts 0;
BA_ "GenSigSendType" SG_ 904 FoldMirrorSts 3;
BA_ "EventTrans" SG_ 904 DriverWindowSts 0;
BA_ "GenSigSendType" SG_ 904 DriverWindowSts 3;
BA_ "EventTrans" SG_ 904 E_LatchDriverFailSts 0;
BA_ "GenSigSendType" SG_ 904 E_LatchDriverFailSts 3;
BA_ "EventTrans" SG_ 904 WLMDriverFailSts 0;
BA_ "GenSigSendType" SG_ 904 WLMDriverFailSts 3;
BA_ "EventTrans" SG_ 906 MaxDefrostSts 0;
BA_ "GenSigSendType" SG_ 906 MaxDefrostSts 3;
BA_ "EventTrans" SG_ 906 RHeatedWindowCntrl 0;
BA_ "GenSigSendType" SG_ 906 RHeatedWindowCntrl 3;
BA_ "EventTrans" SG_ 906 ADAS_heater 0;
BA_ "GenSigSendType" SG_ 906 ADAS_heater 3;
BA_ "GenSigStartValue" SG_ 906 ADAS_heater 1;
BA_ "InitialValue" SG_ 906 ADAS_heater 1;
BA_ "EventTrans" SG_ 906 FogRisk 0;
BA_ "GenSigSendType" SG_ 906 FogRisk 3;
BA_ "EventTrans" SG_ 906 AirQualityIndex 0;
BA_ "GenSigSendType" SG_ 906 AirQualityIndex 3;
BA_ "EventTrans" SG_ 906 NCL_RimHeatingCommand 0;
BA_ "GenSigSendType" SG_ 906 NCL_RimHeatingCommand 3;
BA_ "GenSigSendType" SG_ 906 NCL_FrontPassengerHeating 3;
BA_ "GenSigSendType" SG_ 906 NCL_PassengerFans 3;
BA_ "GenSigSendType" SG_ 906 NCL_FrontDriverHeating 3;
BA_ "GenSigSendType" SG_ 906 NCL_DriverFans 3;
BA_ "GenSigSendType" SG_ 906 NCL_RRHeating 3;
BA_ "GenSigSendType" SG_ 906 NCL_RRFans 3;
BA_ "GenSigSendType" SG_ 906 NCL_RLHeating 3;
BA_ "GenSigSendType" SG_ 906 NCL_RLFans 3;
BA_ "EventTrans" SG_ 952 FrameNumber 0;
BA_ "GenSigSendType" SG_ 952 FrameNumber 3;
BA_ "EventTrans" SG_ 952 TotalFrameNumber 0;
BA_ "GenSigSendType" SG_ 952 TotalFrameNumber 3;
BA_ "GenSigStartValue" SG_ 952 TotalFrameNumber 1;
BA_ "InitialValue" SG_ 952 TotalFrameNumber 1;
BA_ "EventTrans" SG_ 952 NSPFailSts 0;
BA_ "GenSigSendType" SG_ 952 NSPFailSts 3;
BA_ "EventTrans" SG_ 952 NSPControlSts 0;
BA_ "GenSigSendType" SG_ 952 NSPControlSts 3;
BA_ "EventTrans" SG_ 952 LHNSPBuzzerReqSts 0;
BA_ "GenSigSendType" SG_ 952 LHNSPBuzzerReqSts 3;
BA_ "EventTrans" SG_ 952 LHLateralcolour 0;
BA_ "GenSigSendType" SG_ 952 LHLateralcolour 3;
BA_ "Accuracy" SG_ 952 LHLateralObstacleDistance "4 cm";
BA_ "EventTrans" SG_ 952 LHLateralObstacleDistance 0;
BA_ "GenSigSendType" SG_ 952 LHLateralObstacleDistance 3;
BA_ "GenSigStartValue" SG_ 952 LHLateralObstacleDistance 31;
BA_ "InitialValue" SG_ 952 LHLateralObstacleDistance 154;
BA_ "EventTrans" SG_ 952 RHNSPBuzzerReqSts 0;
BA_ "GenSigSendType" SG_ 952 RHNSPBuzzerReqSts 3;
BA_ "EventTrans" SG_ 952 LHCentralcolour 0;
BA_ "GenSigSendType" SG_ 952 LHCentralcolour 3;
BA_ "Accuracy" SG_ 952 LHCentralObstacleDistance "4 cm";
BA_ "EventTrans" SG_ 952 LHCentralObstacleDistance 0;
BA_ "GenSigSendType" SG_ 952 LHCentralObstacleDistance 3;
BA_ "GenSigStartValue" SG_ 952 LHCentralObstacleDistance 31;
BA_ "InitialValue" SG_ 952 LHCentralObstacleDistance 154;
BA_ "EventTrans" SG_ 952 CNSPBuzzerReqSts 0;
BA_ "GenSigSendType" SG_ 952 CNSPBuzzerReqSts 3;
BA_ "EventTrans" SG_ 952 RHCentralcolour 0;
BA_ "GenSigSendType" SG_ 952 RHCentralcolour 3;
BA_ "Accuracy" SG_ 952 RHCentralObstacleDistance "4 cm";
BA_ "EventTrans" SG_ 952 RHCentralObstacleDistance 0;
BA_ "GenSigSendType" SG_ 952 RHCentralObstacleDistance 3;
BA_ "GenSigStartValue" SG_ 952 RHCentralObstacleDistance 31;
BA_ "InitialValue" SG_ 952 RHCentralObstacleDistance 154;
BA_ "EventTrans" SG_ 952 RHLateralcolour 0;
BA_ "GenSigSendType" SG_ 952 RHLateralcolour 3;
BA_ "Accuracy" SG_ 952 RHLateralObstacleDistance "4 cm";
BA_ "EventTrans" SG_ 952 RHLateralObstacleDistance 0;
BA_ "GenSigSendType" SG_ 952 RHLateralObstacleDistance 3;
BA_ "GenSigStartValue" SG_ 952 RHLateralObstacleDistance 31;
BA_ "InitialValue" SG_ 952 RHLateralObstacleDistance 154;
BA_ "EventTrans" SG_ 952 CapoteMovement 0;
BA_ "GenSigSendType" SG_ 952 CapoteMovement 3;
BA_ "EventTrans" SG_ 952 NSPBuzzerRepetitionRate 0;
BA_ "GenSigSendType" SG_ 952 NSPBuzzerRepetitionRate 3;
BA_ "EventTrans" SG_ 960 FuelFlapSts 0;
BA_ "GenSigSendType" SG_ 960 FuelFlapSts 3;
BA_ "EventTrans" SG_ 960 Night_E_DaySensorFailSts 0;
BA_ "GenSigSendType" SG_ 960 Night_E_DaySensorFailSts 3;
BA_ "EventTrans" SG_ 960 RechargeFlapDisplayInfo 0;
BA_ "GenSigSendType" SG_ 960 RechargeFlapDisplayInfo 3;
BA_ "GenSigStartValue" SG_ 960 RechargeFlapDisplayInfo 7;
BA_ "InitialValue" SG_ 960 RechargeFlapDisplayInfo 7;
BA_ "EventTrans" SG_ 960 RimHeatingFbk 0;
BA_ "GenSigSendType" SG_ 960 RimHeatingFbk 3;
BA_ "EventTrans" SG_ 960 RHatchStsForNCP 0;
BA_ "GenSigSendType" SG_ 960 RHatchStsForNCP 3;
BA_ "EventTrans" SG_ 960 PLGCommandSource 0;
BA_ "GenSigSendType" SG_ 960 PLGCommandSource 3;
BA_ "EventTrans" SG_ 960 RHatchStsForPLG 0;
BA_ "GenSigSendType" SG_ 960 RHatchStsForPLG 3;
BA_ "EventTrans" SG_ 960 PLGCommand 0;
BA_ "GenSigSendType" SG_ 960 PLGCommand 3;
BA_ "EventTrans" SG_ 961 FollowMeHomeEnable_Fbk 0;
BA_ "GenSigSendType" SG_ 961 FollowMeHomeEnable_Fbk 3;
BA_ "EventTrans" SG_ 963 ElectricSteeringLamp_FailSts 0;
BA_ "GenSigSendType" SG_ 963 ElectricSteeringLamp_FailSts 3;
BA_ "EventTrans" SG_ 963 InternalLightLevel 0;
BA_ "GenSigSendType" SG_ 963 InternalLightLevel 3;
BA_ "EventTrans" SG_ 963 InternalLightLevelForDisplay 0;
BA_ "GenSigSendType" SG_ 963 InternalLightLevelForDisplay 3;
BA_ "EventTrans" SG_ 964 AudioModeDownCntrl 0;
BA_ "GenSigSendType" SG_ 964 AudioModeDownCntrl 3;
BA_ "EventTrans" SG_ 964 AudioModeUpCntrl 0;
BA_ "GenSigSendType" SG_ 964 AudioModeUpCntrl 3;
BA_ "EventTrans" SG_ 964 VolumeButtonPushSts 0;
BA_ "GenSigSendType" SG_ 964 VolumeButtonPushSts 3;
BA_ "EventTrans" SG_ 964 FlashBeamSwitchSts 0;
BA_ "GenSigSendType" SG_ 964 FlashBeamSwitchSts 3;
BA_ "EventTrans" SG_ 964 LdirectionSwitchSts 0;
BA_ "GenSigSendType" SG_ 964 LdirectionSwitchSts 3;
BA_ "EventTrans" SG_ 964 RdirectionSwitchSts 0;
BA_ "GenSigSendType" SG_ 964 RdirectionSwitchSts 3;
BA_ "EventTrans" SG_ 964 LChangeLaneSts 0;
BA_ "GenSigSendType" SG_ 964 LChangeLaneSts 3;
BA_ "EventTrans" SG_ 964 RChangeLaneSts 0;
BA_ "GenSigSendType" SG_ 964 RChangeLaneSts 3;
BA_ "EventTrans" SG_ 964 RearWindowWasherSwitchSts 0;
BA_ "GenSigSendType" SG_ 964 RearWindowWasherSwitchSts 3;
BA_ "EventTrans" SG_ 964 RearWindowWiperSwitchSts 0;
BA_ "GenSigSendType" SG_ 964 RearWindowWiperSwitchSts 3;
BA_ "EventTrans" SG_ 964 HighBeamSwitchSts 0;
BA_ "GenSigSendType" SG_ 964 HighBeamSwitchSts 3;
BA_ "EventTrans" SG_ 964 VolumeRotation 0;
BA_ "GenSigSendType" SG_ 964 VolumeRotation 3;
BA_ "EventTrans" SG_ 964 VolumeDial 0;
BA_ "GenSigSendType" SG_ 964 VolumeDial 3;
BA_ "EventTrans" SG_ 965 ADAS_OnOffSts 0;
BA_ "GenSigSendType" SG_ 965 ADAS_OnOffSts 3;
BA_ "EventTrans" SG_ 965 RimTemperature 0;
BA_ "GenSigSendType" SG_ 965 RimTemperature 3;
BA_ "InitialValue" SG_ 965 RimTemperature -40;
BA_ "EventTrans" SG_ 967 NIT_LifterLongPressRqt 0;
BA_ "GenSigSendType" SG_ 967 NIT_LifterLongPressRqt 3;
BA_ "EventTrans" SG_ 967 AQS_Conditions 0;
BA_ "GenSigSendType" SG_ 967 AQS_Conditions 3;
BA_ "EventTrans" SG_ 967 NIT_LifterShortPressRqt 0;
BA_ "GenSigSendType" SG_ 967 NIT_LifterShortPressRqt 3;
BA_ "EventTrans" SG_ 969 CapoteBuzzerReq 0;
BA_ "GenSigSendType" SG_ 969 CapoteBuzzerReq 3;
BA_ "EventTrans" SG_ 969 CapoteFailSts 0;
BA_ "GenSigSendType" SG_ 969 CapoteFailSts 3;
BA_ "EventTrans" SG_ 969 TrunkReleaseReqCntrl 0;
BA_ "GenSigSendType" SG_ 969 TrunkReleaseReqCntrl 3;
BA_ "EventTrans" SG_ 969 CapoteSts 0;
BA_ "GenSigSendType" SG_ 969 CapoteSts 3;
BA_ "EventTrans" SG_ 969 FrontWindowsEnable 0;
BA_ "GenSigSendType" SG_ 969 FrontWindowsEnable 3;
BA_ "GenSigStartValue" SG_ 969 FrontWindowsEnable 1;
BA_ "InitialValue" SG_ 969 FrontWindowsEnable 1;
BA_ "EventTrans" SG_ 969 TrunkEnable 0;
BA_ "GenSigSendType" SG_ 969 TrunkEnable 3;
BA_ "GenSigStartValue" SG_ 969 TrunkEnable 1;
BA_ "InitialValue" SG_ 969 TrunkEnable 1;
BA_ "EventTrans" SG_ 969 CapoteInfoForDisplay 0;
BA_ "GenSigSendType" SG_ 969 CapoteInfoForDisplay 3;
BA_ "EventTrans" SG_ 969 DriverHRWindowsSts 0;
BA_ "GenSigSendType" SG_ 969 DriverHRWindowsSts 3;
BA_ "GenSigStartValue" SG_ 969 DriverHRWindowsSts 2;
BA_ "InitialValue" SG_ 969 DriverHRWindowsSts 2;
BA_ "EventTrans" SG_ 969 FrontWindowsMovementCmd 0;
BA_ "GenSigSendType" SG_ 969 FrontWindowsMovementCmd 3;
BA_ "EventTrans" SG_ 969 CapoteStsForDisplay 0;
BA_ "GenSigSendType" SG_ 969 CapoteStsForDisplay 3;
BA_ "EventTrans" SG_ 969 ObstacleDetectionSts 0;
BA_ "GenSigSendType" SG_ 969 ObstacleDetectionSts 3;
BA_ "EventTrans" SG_ 969 PsgnrHRWindowInitializedSts 0;
BA_ "GenSigSendType" SG_ 969 PsgnrHRWindowInitializedSts 3;
BA_ "EventTrans" SG_ 969 DriverHRWindowInitializedSts 0;
BA_ "GenSigSendType" SG_ 969 DriverHRWindowInitializedSts 3;
BA_ "EventTrans" SG_ 969 AutomaticDownCntrl 0;
BA_ "GenSigSendType" SG_ 969 AutomaticDownCntrl 3;
BA_ "EventTrans" SG_ 969 PsgnrHRWindowsSts 0;
BA_ "GenSigSendType" SG_ 969 PsgnrHRWindowsSts 3;
BA_ "GenSigStartValue" SG_ 969 PsgnrHRWindowsSts 2;
BA_ "InitialValue" SG_ 969 PsgnrHRWindowsSts 2;
BA_ "EventTrans" SG_ 969 BackWindowInitializedSts 0;
BA_ "GenSigSendType" SG_ 969 BackWindowInitializedSts 3;
BA_ "EventTrans" SG_ 969 BackWindowSts 0;
BA_ "GenSigSendType" SG_ 969 BackWindowSts 3;
BA_ "GenSigStartValue" SG_ 969 BackWindowSts 2;
BA_ "InitialValue" SG_ 969 BackWindowSts 2;
BA_ "EventTrans" SG_ 969 NCPAutoStopFailSts 0;
BA_ "GenSigSendType" SG_ 969 NCPAutoStopFailSts 3;
BA_ "EventTrans" SG_ 969 NCPAutoStopEnableSts 0;
BA_ "GenSigSendType" SG_ 969 NCPAutoStopEnableSts 3;
BA_ "EventTrans" SG_ 969 NCPAutoStopStaySts 0;
BA_ "GenSigSendType" SG_ 969 NCPAutoStopStaySts 3;
BA_ "EventTrans" SG_ 969 PowerStrikerUpEnable 0;
BA_ "GenSigSendType" SG_ 969 PowerStrikerUpEnable 3;
BA_ "GenSigStartValue" SG_ 969 PowerStrikerUpEnable 1;
BA_ "InitialValue" SG_ 969 PowerStrikerUpEnable 1;
BA_ "GenSigSendType" SG_ 969 TonneauCoverSts 3;
BA_ "EventTrans" SG_ 970 NPS_FrontSensorButtonSts 0;
BA_ "GenSigSendType" SG_ 970 NPS_FrontSensorButtonSts 3;
BA_ "EventTrans" SG_ 971 STS_LH_OsHandle_Lock_Active 0;
BA_ "GenSigSendType" SG_ 971 STS_LH_OsHandle_Lock_Active 3;
BA_ "EventTrans" SG_ 971 STS_LH_OsHandle_Active 0;
BA_ "GenSigSendType" SG_ 971 STS_LH_OsHandle_Active 3;
BA_ "EventTrans" SG_ 971 STS_LH_CinchStatus 0;
BA_ "GenSigSendType" SG_ 971 STS_LH_CinchStatus 3;
BA_ "EventTrans" SG_ 971 STS_LH_DoorStatus 0;
BA_ "GenSigSendType" SG_ 971 STS_LH_DoorStatus 3;
BA_ "EventTrans" SG_ 971 STS_LH_FailSts 0;
BA_ "GenSigSendType" SG_ 971 STS_LH_FailSts 3;
BA_ "EventTrans" SG_ 971 STS_LH_Latch 0;
BA_ "GenSigSendType" SG_ 971 STS_LH_Latch 3;
BA_ "EventTrans" SG_ 971 ELLCrashSts 0;
BA_ "GenSigSendType" SG_ 971 ELLCrashSts 3;
BA_ "EventTrans" SG_ 971 STS_LH_HandleSpeedFailSts 0;
BA_ "GenSigSendType" SG_ 971 STS_LH_HandleSpeedFailSts 3;
BA_ "EventTrans" SG_ 971 STS_LH_ShortDropMode 0;
BA_ "GenSigSendType" SG_ 971 STS_LH_ShortDropMode 3;
BA_ "EventTrans" SG_ 971 STS_LH_PowerModeSts 0;
BA_ "GenSigSendType" SG_ 971 STS_LH_PowerModeSts 3;
BA_ "EventTrans" SG_ 971 STS_LH_IsHandle_Active 0;
BA_ "GenSigSendType" SG_ 971 STS_LH_IsHandle_Active 3;
BA_ "SignalAge" SG_ 971 CRC_STS_LH 10;
BA_ "EventTrans" SG_ 972 STS_RH_OsHandle_Lock_Active 0;
BA_ "GenSigSendType" SG_ 972 STS_RH_OsHandle_Lock_Active 3;
BA_ "EventTrans" SG_ 972 STS_RH_OsHandle_Active 0;
BA_ "GenSigSendType" SG_ 972 STS_RH_OsHandle_Active 3;
BA_ "EventTrans" SG_ 972 STS_RH_CinchStatus 0;
BA_ "GenSigSendType" SG_ 972 STS_RH_CinchStatus 3;
BA_ "EventTrans" SG_ 972 STS_RH_DoorStatus 0;
BA_ "GenSigSendType" SG_ 972 STS_RH_DoorStatus 3;
BA_ "EventTrans" SG_ 972 STS_RH_FailSts 0;
BA_ "GenSigSendType" SG_ 972 STS_RH_FailSts 3;
BA_ "EventTrans" SG_ 972 STS_RH_Latch 0;
BA_ "GenSigSendType" SG_ 972 STS_RH_Latch 3;
BA_ "EventTrans" SG_ 972 ELRCrashSts 0;
BA_ "GenSigSendType" SG_ 972 ELRCrashSts 3;
BA_ "EventTrans" SG_ 972 STS_RH_HandleSpeedFailSts 0;
BA_ "GenSigSendType" SG_ 972 STS_RH_HandleSpeedFailSts 3;
BA_ "EventTrans" SG_ 972 STS_RH_ShortDropMode 0;
BA_ "GenSigSendType" SG_ 972 STS_RH_ShortDropMode 3;
BA_ "EventTrans" SG_ 972 STS_RH_PowerModeSts 0;
BA_ "GenSigSendType" SG_ 972 STS_RH_PowerModeSts 3;
BA_ "EventTrans" SG_ 972 STS_RH_IsHandle_Active 0;
BA_ "GenSigSendType" SG_ 972 STS_RH_IsHandle_Active 3;
BA_ "SignalAge" SG_ 972 CRC_STS_RH 10;
BA_ "EventTrans" SG_ 973 STS_LV_OsHandle_Lock_Active 0;
BA_ "GenSigSendType" SG_ 973 STS_LV_OsHandle_Lock_Active 3;
BA_ "EventTrans" SG_ 973 STS_LV_OsHandle_Active 0;
BA_ "GenSigSendType" SG_ 973 STS_LV_OsHandle_Active 3;
BA_ "EventTrans" SG_ 973 STS_LV_CinchStatus 0;
BA_ "GenSigSendType" SG_ 973 STS_LV_CinchStatus 3;
BA_ "GenSigStartValue" SG_ 973 STS_LV_CinchStatus 1;
BA_ "InitialValue" SG_ 973 STS_LV_CinchStatus 1;
BA_ "EventTrans" SG_ 973 STS_LV_DoorStatus 0;
BA_ "GenSigSendType" SG_ 973 STS_LV_DoorStatus 3;
BA_ "EventTrans" SG_ 973 STS_LV_FailSts 0;
BA_ "GenSigSendType" SG_ 973 STS_LV_FailSts 3;
BA_ "EventTrans" SG_ 973 STS_LV_Latch 0;
BA_ "GenSigSendType" SG_ 973 STS_LV_Latch 3;
BA_ "EventTrans" SG_ 973 STS_LV_PowerDoorSts 0;
BA_ "GenSigSendType" SG_ 973 STS_LV_PowerDoorSts 3;
BA_ "EventTrans" SG_ 973 STS_LV_ShortDropMode 0;
BA_ "GenSigSendType" SG_ 973 STS_LV_ShortDropMode 3;
BA_ "EventTrans" SG_ 973 STS_LV_IsHandle_Active 0;
BA_ "GenSigSendType" SG_ 973 STS_LV_IsHandle_Active 3;
BA_ "EventTrans" SG_ 973 STS_LV_PowerDoorPosValidData 0;
BA_ "GenSigSendType" SG_ 973 STS_LV_PowerDoorPosValidData 3;
BA_ "EventTrans" SG_ 973 ERLCrashSts 0;
BA_ "GenSigSendType" SG_ 973 ERLCrashSts 3;
BA_ "EventTrans" SG_ 973 STS_LV_HandleSpeedFailSts 0;
BA_ "GenSigSendType" SG_ 973 STS_LV_HandleSpeedFailSts 3;
BA_ "EventTrans" SG_ 973 STS_LV_PDFailSts 0;
BA_ "GenSigSendType" SG_ 973 STS_LV_PDFailSts 3;
BA_ "EventTrans" SG_ 973 STS_LV_ChildLockFailSts 0;
BA_ "GenSigSendType" SG_ 973 STS_LV_ChildLockFailSts 3;
BA_ "EventTrans" SG_ 973 STS_LV_DoorAlert 0;
BA_ "GenSigSendType" SG_ 973 STS_LV_DoorAlert 3;
BA_ "EventTrans" SG_ 973 STS_LV_ChildLock_Feedback 0;
BA_ "GenSigSendType" SG_ 973 STS_LV_ChildLock_Feedback 3;
BA_ "EventTrans" SG_ 973 STS_LV_ISwitch_Active 0;
BA_ "GenSigSendType" SG_ 973 STS_LV_ISwitch_Active 3;
BA_ "EventTrans" SG_ 973 LReleaseReq 0;
BA_ "GenSigSendType" SG_ 973 LReleaseReq 3;
BA_ "SignalAge" SG_ 973 CRC_STS_LV 10;
BA_ "EventTrans" SG_ 974 STS_RV_OsHandle_Lock_Active 0;
BA_ "GenSigSendType" SG_ 974 STS_RV_OsHandle_Lock_Active 3;
BA_ "EventTrans" SG_ 974 STS_RV_OsHandle_Active 0;
BA_ "GenSigSendType" SG_ 974 STS_RV_OsHandle_Active 3;
BA_ "EventTrans" SG_ 974 STS_RV_CinchStatus 0;
BA_ "GenSigSendType" SG_ 974 STS_RV_CinchStatus 3;
BA_ "GenSigStartValue" SG_ 974 STS_RV_CinchStatus 1;
BA_ "InitialValue" SG_ 974 STS_RV_CinchStatus 1;
BA_ "EventTrans" SG_ 974 STS_RV_DoorStatus 0;
BA_ "GenSigSendType" SG_ 974 STS_RV_DoorStatus 3;
BA_ "EventTrans" SG_ 974 STS_RV_FailSts 0;
BA_ "GenSigSendType" SG_ 974 STS_RV_FailSts 3;
BA_ "EventTrans" SG_ 974 STS_RV_Latch 0;
BA_ "GenSigSendType" SG_ 974 STS_RV_Latch 3;
BA_ "EventTrans" SG_ 974 STS_RV_PowerDoorSts 0;
BA_ "GenSigSendType" SG_ 974 STS_RV_PowerDoorSts 3;
BA_ "EventTrans" SG_ 974 STS_RV_ShortDropMode 0;
BA_ "GenSigSendType" SG_ 974 STS_RV_ShortDropMode 3;
BA_ "EventTrans" SG_ 974 STS_RV_IsHandle_Active 0;
BA_ "GenSigSendType" SG_ 974 STS_RV_IsHandle_Active 3;
BA_ "EventTrans" SG_ 974 STS_RV_PowerDoorPosValidData 0;
BA_ "GenSigSendType" SG_ 974 STS_RV_PowerDoorPosValidData 3;
BA_ "EventTrans" SG_ 974 ERRCrashSts 0;
BA_ "GenSigSendType" SG_ 974 ERRCrashSts 3;
BA_ "EventTrans" SG_ 974 STS_RV_HandleSpeedFailSts 0;
BA_ "GenSigSendType" SG_ 974 STS_RV_HandleSpeedFailSts 3;
BA_ "EventTrans" SG_ 974 STS_RV_PDFailSts 0;
BA_ "GenSigSendType" SG_ 974 STS_RV_PDFailSts 3;
BA_ "EventTrans" SG_ 974 STS_RV_ChildLockFailSts 0;
BA_ "GenSigSendType" SG_ 974 STS_RV_ChildLockFailSts 3;
BA_ "EventTrans" SG_ 974 STS_RV_DoorAlert 0;
BA_ "GenSigSendType" SG_ 974 STS_RV_DoorAlert 3;
BA_ "EventTrans" SG_ 974 STS_RV_ChildLock_Feedback 0;
BA_ "GenSigSendType" SG_ 974 STS_RV_ChildLock_Feedback 3;
BA_ "EventTrans" SG_ 974 STS_RV_ISwitch_Active 0;
BA_ "GenSigSendType" SG_ 974 STS_RV_ISwitch_Active 3;
BA_ "EventTrans" SG_ 974 RReleaseReq 0;
BA_ "GenSigSendType" SG_ 974 RReleaseReq 3;
BA_ "SignalAge" SG_ 974 CRC_STS_RV 10;
BA_ "EventTrans" SG_ 975 STS_LH_ShortDropFeedback 0;
BA_ "GenSigSendType" SG_ 975 STS_LH_ShortDropFeedback 3;
BA_ "EventTrans" SG_ 975 NBC_RV_Unlock 0;
BA_ "GenSigSendType" SG_ 975 NBC_RV_Unlock 3;
BA_ "EventTrans" SG_ 975 NBC_LV_Unlock 0;
BA_ "GenSigSendType" SG_ 975 NBC_LV_Unlock 3;
BA_ "EventTrans" SG_ 975 NBC_RH_Unlock 0;
BA_ "GenSigSendType" SG_ 975 NBC_RH_Unlock 3;
BA_ "EventTrans" SG_ 975 NBC_LH_Unlock 0;
BA_ "GenSigSendType" SG_ 975 NBC_LH_Unlock 3;
BA_ "EventTrans" SG_ 975 NBC_Lock 0;
BA_ "GenSigSendType" SG_ 975 NBC_Lock 3;
BA_ "EventTrans" SG_ 975 STS_RV_ShortDropFeedback 0;
BA_ "GenSigSendType" SG_ 975 STS_RV_ShortDropFeedback 3;
BA_ "EventTrans" SG_ 975 STS_LV_ShortDropFeedback 0;
BA_ "GenSigSendType" SG_ 975 STS_LV_ShortDropFeedback 3;
BA_ "EventTrans" SG_ 975 STS_RH_ShortDropFeedback 0;
BA_ "GenSigSendType" SG_ 975 STS_RH_ShortDropFeedback 3;
BA_ "EventTrans" SG_ 977 PsngrAntiPinchFailSts 0;
BA_ "GenSigSendType" SG_ 977 PsngrAntiPinchFailSts 3;
BA_ "EventTrans" SG_ 977 WLMPsngrFailSts 0;
BA_ "GenSigSendType" SG_ 977 WLMPsngrFailSts 3;
BA_ "EventTrans" SG_ 977 PsgnrCmdCompleteCntrl 0;
BA_ "GenSigSendType" SG_ 977 PsgnrCmdCompleteCntrl 3;
BA_ "EventTrans" SG_ 977 PsgnrHRWindowsUpSts 0;
BA_ "GenSigSendType" SG_ 977 PsgnrHRWindowsUpSts 3;
BA_ "EventTrans" SG_ 977 PsgnrHRWindowsDownSts 0;
BA_ "GenSigSendType" SG_ 977 PsgnrHRWindowsDownSts 3;
BA_ "EventTrans" SG_ 977 PsngrWindowSts 0;
BA_ "GenSigSendType" SG_ 977 PsngrWindowSts 3;
BA_ "EventTrans" SG_ 977 E_LatchPsngrFailSts 0;
BA_ "GenSigSendType" SG_ 977 E_LatchPsngrFailSts 3;
BA_ "EventTrans" SG_ 978 NAGSeatAngleBackRest 0;
BA_ "GenSigSendType" SG_ 978 NAGSeatAngleBackRest 3;
BA_ "EventTrans" SG_ 978 DriverUserAction 0;
BA_ "GenSigSendType" SG_ 978 DriverUserAction 3;
BA_ "EventTrans" SG_ 978 NAGSeatTiltingPosition 0;
BA_ "GenSigSendType" SG_ 978 NAGSeatTiltingPosition 3;
BA_ "EventTrans" SG_ 978 NAGSeatSlidingPosition 0;
BA_ "GenSigSendType" SG_ 978 NAGSeatSlidingPosition 3;
BA_ "EventTrans" SG_ 983 NAPSeatAngleBackRest 0;
BA_ "GenSigSendType" SG_ 983 NAPSeatAngleBackRest 3;
BA_ "EventTrans" SG_ 983 PassengerUserAction 0;
BA_ "GenSigSendType" SG_ 983 PassengerUserAction 3;
BA_ "EventTrans" SG_ 983 NAPSeatSlidingPosition 0;
BA_ "GenSigSendType" SG_ 983 NAPSeatSlidingPosition 3;
BA_ "EventTrans" SG_ 983 NAPSeatTiltingPosition 0;
BA_ "GenSigSendType" SG_ 983 NAPSeatTiltingPosition 3;
BA_ "GenSigStartValue" SG_ 992 SoSe_SunInt_2D_Le 252;
BA_ "InitialValue" SG_ 992 SoSe_SunInt_2D_Le 1260;
BA_ "GenSigStartValue" SG_ 992 SoSe_SunInt_2D_Ri 252;
BA_ "InitialValue" SG_ 992 SoSe_SunInt_2D_Ri 1260;
BA_ "GenSigStartValue" SG_ 992 GLASS_TEMP 252;
BA_ "InitialValue" SG_ 992 GLASS_TEMP 86;
BA_ "GenSigStartValue" SG_ 992 DewpointTemp 252;
BA_ "InitialValue" SG_ 992 DewpointTemp 86;
BA_ "GenSigStartValue" SG_ 992 REL_HUMIDITY 252;
BA_ "InitialValue" SG_ 992 REL_HUMIDITY 126;
BA_ "GenSigStartValue" SG_ 992 External_Sensor_Brightness_Level 65532;
BA_ "InitialValue" SG_ 992 External_Sensor_Brightness_Level 65532;
BA_ "Accuracy" SG_ 1024 LongAcceleration "0.02";
BA_ "GenSigStartValue" SG_ 1024 LongAcceleration 2048;
BA_ "SignalAge" SG_ 1024 LongAcceleration 10;
BA_ "GenSigStartValue" SG_ 1024 AXSStat 3;
BA_ "InitialValue" SG_ 1024 AXSStat 3;
BA_ "Accuracy" SG_ 1024 LatAcceleration "0.02";
BA_ "GenSigStartValue" SG_ 1024 LatAcceleration 2048;
BA_ "SignalAge" SG_ 1024 LatAcceleration 10;
BA_ "GenSigStartValue" SG_ 1024 AYSStat 3;
BA_ "InitialValue" SG_ 1024 AYSStat 3;
BA_ "Accuracy" SG_ 1024 YawRate "0.08";
BA_ "GenSigStartValue" SG_ 1024 YawRate 2048;
BA_ "SignalAge" SG_ 1024 YawRate 10;
BA_ "GenSigStartValue" SG_ 1024 YRSStat 3;
BA_ "InitialValue" SG_ 1024 YRSStat 3;
BA_ "EventTrans" SG_ 1034 DisplayUserAction 0;
BA_ "GenSigSendType" SG_ 1034 DisplayUserAction 3;
BA_ "EventTrans" SG_ 1034 PowerModeSts 0;
BA_ "GenSigSendType" SG_ 1034 PowerModeSts 3;
BA_ "EventTrans" SG_ 1034 RightChildLockButton 0;
BA_ "GenSigSendType" SG_ 1034 RightChildLockButton 3;
BA_ "EventTrans" SG_ 1034 LeftChildLockButton 0;
BA_ "GenSigSendType" SG_ 1034 LeftChildLockButton 3;
BA_ "EventTrans" SG_ 1034 Carwash_Rqt 0;
BA_ "GenSigSendType" SG_ 1034 Carwash_Rqt 3;
BA_ "InitialValue" SG_ 1214 LVB_MaxCellsTemp -45;
BA_ "GenSigStartValue" SG_ 1214 LVB_SOH 127;
BA_ "InitialValue" SG_ 1214 LVB_SOH 127;
BA_ "GenSigStartValue" SG_ 1214 LVB_Relay_Status 3;
BA_ "InitialValue" SG_ 1214 LVB_Relay_Status 3;
BA_ "EventTrans" SG_ 1313 LockUnlockDoors_Button 0;
BA_ "GenSigSendType" SG_ 1313 LockUnlockDoors_Button 3;
BA_ "SignalAge" SG_ 1313 CRC_STS_DRS 10;
BA_ "Accuracy" SG_ 1318 BrakePressureTarget "� 5 bar";
BA_ "SignalAge" SG_ 1318 BrakePressureTarget 7;
BA_ "Accuracy" SG_ 1318 DriverBrkPressureRqt "� 5 bar";
BA_ "SignalAge" SG_ 1318 DriverBrkPressureRqt 7;
BA_ "Accuracy" SG_ 1318 BrakePressureActual "� 5 bar";
BA_ "SignalAge" SG_ 1318 BrakePressureActual 7;
BA_ "EventTrans" SG_ 1351 HALF_CHIME_TYPESts 0;
BA_ "GenSigSendType" SG_ 1351 HALF_CHIME_TYPESts 3;
BA_ "EventTrans" SG_ 1351 TSR_Fault 0;
BA_ "GenSigSendType" SG_ 1351 TSR_Fault 3;
BA_ "EventTrans" SG_ 1351 TSR_ON 0;
BA_ "GenSigSendType" SG_ 1351 TSR_ON 3;
BA_ "EventTrans" SG_ 1351 LDWSystemSts 0;
BA_ "GenSigSendType" SG_ 1351 LDWSystemSts 3;
BA_ "GenSigStartValue" SG_ 1351 LDWSystemSts 2;
BA_ "InitialValue" SG_ 1351 LDWSystemSts 2;
BA_ "GenSigStartValue" SG_ 1351 StatusLKA 3;
BA_ "InitialValue" SG_ 1351 StatusLKA 3;
BA_ "GenSigStartValue" SG_ 1351 LDWSensitivitySts 3;
BA_ "InitialValue" SG_ 1351 LDWSensitivitySts 3;
BA_ "EventTrans" SG_ 1351 HALF_RF_CHIME_RQSts 0;
BA_ "GenSigSendType" SG_ 1351 HALF_RF_CHIME_RQSts 3;
BA_ "EventTrans" SG_ 1351 HALF_LF_CHIME_RQSts 0;
BA_ "GenSigSendType" SG_ 1351 HALF_LF_CHIME_RQSts 3;
BA_ "EventTrans" SG_ 1351 HandsOnSts 0;
BA_ "GenSigSendType" SG_ 1351 HandsOnSts 3;
BA_ "GenSigStartValue" SG_ 1351 HandsOnSts 6;
BA_ "InitialValue" SG_ 1351 HandsOnSts 6;
BA_ "GenSigStartValue" SG_ 1351 DrowsinessSts 3;
BA_ "InitialValue" SG_ 1351 DrowsinessSts 3;
BA_ "GenSigStartValue" SG_ 1351 LDWWarningType_fbk 3;
BA_ "InitialValue" SG_ 1351 LDWWarningType_fbk 3;
BA_ "EventTrans" SG_ 1351 DisplaySts 0;
BA_ "GenSigSendType" SG_ 1351 DisplaySts 3;
BA_ "EventTrans" SG_ 1351 SensorBlinded 0;
BA_ "GenSigSendType" SG_ 1351 SensorBlinded 3;
BA_ "EventTrans" SG_ 1351 AHBFault 0;
BA_ "GenSigSendType" SG_ 1351 AHBFault 3;
BA_ "EventTrans" SG_ 1351 AHB_ON 0;
BA_ "GenSigSendType" SG_ 1351 AHB_ON 3;
BA_ "EventTrans" SG_ 1351 TSR_Sts 0;
BA_ "GenSigSendType" SG_ 1351 TSR_Sts 3;
BA_ "EventTrans" SG_ 1351 HALF_heaterSts 0;
BA_ "GenSigSendType" SG_ 1351 HALF_heaterSts 3;
BA_ "EventTrans" SG_ 1369 RearLeftAntiPinchFailSts 0;
BA_ "GenSigSendType" SG_ 1369 RearLeftAntiPinchFailSts 3;
BA_ "EventTrans" SG_ 1369 RearRightAntiPinchFailSts 0;
BA_ "GenSigSendType" SG_ 1369 RearRightAntiPinchFailSts 3;
BA_ "EventTrans" SG_ 1369 WMRRFailSts 0;
BA_ "GenSigSendType" SG_ 1369 WMRRFailSts 3;
BA_ "EventTrans" SG_ 1369 WMRLFailsts 0;
BA_ "GenSigSendType" SG_ 1369 WMRLFailsts 3;
BA_ "EventTrans" SG_ 1381 RearSeatLeftUserAction 0;
BA_ "GenSigSendType" SG_ 1381 RearSeatLeftUserAction 3;
BA_ "EventTrans" SG_ 1381 RearSeatLeftBackrestFailSts 0;
BA_ "GenSigSendType" SG_ 1381 RearSeatLeftBackrestFailSts 3;
BA_ "EventTrans" SG_ 1381 RearSeatRightUserAction 0;
BA_ "GenSigSendType" SG_ 1381 RearSeatRightUserAction 3;
BA_ "EventTrans" SG_ 1381 RearSeatRightBackrestFailSts 0;
BA_ "GenSigSendType" SG_ 1381 RearSeatRightBackrestFailSts 3;
BA_ "EventTrans" SG_ 1419 MKF_FrontPassengerHeating 0;
BA_ "GenSigSendType" SG_ 1419 MKF_FrontPassengerHeating 3;
BA_ "EventTrans" SG_ 1419 MKF_FrontDriverHeating 0;
BA_ "GenSigSendType" SG_ 1419 MKF_FrontDriverHeating 3;
BA_ "EventTrans" SG_ 1419 MKF_DriverFans 0;
BA_ "GenSigSendType" SG_ 1419 MKF_DriverFans 3;
BA_ "EventTrans" SG_ 1419 MKF_PassengerFans 0;
BA_ "GenSigSendType" SG_ 1419 MKF_PassengerFans 3;
BA_ "EventTrans" SG_ 1420 MKF_DriverAirFlowZone 0;
BA_ "GenSigSendType" SG_ 1420 MKF_DriverAirFlowZone 3;
BA_ "EventTrans" SG_ 1420 MKF_DriverTemperature 0;
BA_ "GenSigSendType" SG_ 1420 MKF_DriverTemperature 3;
BA_ "EventTrans" SG_ 1420 MKF_PassengerAirFlowZone 0;
BA_ "GenSigSendType" SG_ 1420 MKF_PassengerAirFlowZone 3;
BA_ "EventTrans" SG_ 1420 MKF_PassengerTemperature 0;
BA_ "GenSigSendType" SG_ 1420 MKF_PassengerTemperature 3;
BA_ "EventTrans" SG_ 1420 MKF_RearExtendedClimate 0;
BA_ "GenSigSendType" SG_ 1420 MKF_RearExtendedClimate 3;
BA_ "EventTrans" SG_ 1420 MKF_AirConditionCompressor 0;
BA_ "GenSigSendType" SG_ 1420 MKF_AirConditionCompressor 3;
BA_ "EventTrans" SG_ 1420 MKF_MonoMode 0;
BA_ "GenSigSendType" SG_ 1420 MKF_MonoMode 3;
BA_ "EventTrans" SG_ 1420 MKF_BlowerSpeed10L 0;
BA_ "GenSigSendType" SG_ 1420 MKF_BlowerSpeed10L 3;
BA_ "EventTrans" SG_ 1420 MKF_AirRecirculation 0;
BA_ "GenSigSendType" SG_ 1420 MKF_AirRecirculation 3;
BA_ "EventTrans" SG_ 1420 MKF_RearDefrostCommand 0;
BA_ "GenSigSendType" SG_ 1420 MKF_RearDefrostCommand 3;
BA_ "EventTrans" SG_ 1420 MKF_MaxDefrostCommand 0;
BA_ "GenSigSendType" SG_ 1420 MKF_MaxDefrostCommand 3;
BA_ "EventTrans" SG_ 1422 MKF_RLHeating 0;
BA_ "GenSigSendType" SG_ 1422 MKF_RLHeating 3;
BA_ "EventTrans" SG_ 1422 MKF_RLFans 0;
BA_ "GenSigSendType" SG_ 1422 MKF_RLFans 3;
BA_ "EventTrans" SG_ 1422 MKF_RRHeating 0;
BA_ "GenSigSendType" SG_ 1422 MKF_RRHeating 3;
BA_ "EventTrans" SG_ 1422 MKF_RRFans 0;
BA_ "GenSigSendType" SG_ 1422 MKF_RRFans 3;
BA_ "EventTrans" SG_ 1423 MKF_RLAirFlowZone 0;
BA_ "GenSigSendType" SG_ 1423 MKF_RLAirFlowZone 3;
BA_ "EventTrans" SG_ 1423 MKF_RLTemperature 0;
BA_ "GenSigSendType" SG_ 1423 MKF_RLTemperature 3;
BA_ "EventTrans" SG_ 1423 MKF_RRAirFlowZone 0;
BA_ "GenSigSendType" SG_ 1423 MKF_RRAirFlowZone 3;
BA_ "EventTrans" SG_ 1423 MKF_RRTemperature 0;
BA_ "GenSigSendType" SG_ 1423 MKF_RRTemperature 3;
BA_ "EventTrans" SG_ 1423 MKF_RBlowerSpeed10L 0;
BA_ "GenSigSendType" SG_ 1423 MKF_RBlowerSpeed10L 3;
BA_ "EventTrans" SG_ 1425 MKR_RLHeating 0;
BA_ "GenSigSendType" SG_ 1425 MKR_RLHeating 3;
BA_ "EventTrans" SG_ 1425 MKR_RLFans 0;
BA_ "GenSigSendType" SG_ 1425 MKR_RLFans 3;
BA_ "EventTrans" SG_ 1425 MKR_RRHeating 0;
BA_ "GenSigSendType" SG_ 1425 MKR_RRHeating 3;
BA_ "EventTrans" SG_ 1425 MKR_RRFans 0;
BA_ "GenSigSendType" SG_ 1425 MKR_RRFans 3;
BA_ "EventTrans" SG_ 1426 MKR_RLAirFlowZone 0;
BA_ "GenSigSendType" SG_ 1426 MKR_RLAirFlowZone 3;
BA_ "EventTrans" SG_ 1426 MKR_RLTemperature 0;
BA_ "GenSigSendType" SG_ 1426 MKR_RLTemperature 3;
BA_ "EventTrans" SG_ 1426 MKR_RRAirFlowZone 0;
BA_ "GenSigSendType" SG_ 1426 MKR_RRAirFlowZone 3;
BA_ "EventTrans" SG_ 1426 MKR_RRTemperature 0;
BA_ "GenSigSendType" SG_ 1426 MKR_RRTemperature 3;
BA_ "EventTrans" SG_ 1426 MKR_RearAirConditionCompressor 0;
BA_ "GenSigSendType" SG_ 1426 MKR_RearAirConditionCompressor 3;
BA_ "EventTrans" SG_ 1426 MKR_RRAutoMode 0;
BA_ "GenSigSendType" SG_ 1426 MKR_RRAutoMode 3;
BA_ "EventTrans" SG_ 1426 MKR_RLAutoMode 0;
BA_ "GenSigSendType" SG_ 1426 MKR_RLAutoMode 3;
BA_ "EventTrans" SG_ 1426 MKR_RSBlowerSpeed10L 0;
BA_ "GenSigSendType" SG_ 1426 MKR_RSBlowerSpeed10L 3;
BA_ "EventTrans" SG_ 1426 MKR_RearExtendedClimate 0;
BA_ "GenSigSendType" SG_ 1426 MKR_RearExtendedClimate 3;
BA_ "NodeLayerModules" BU_ NCL "Osek_TP.dll,FiatNM_B.dll,CANoeILNLFiat.dll";
BA_ "NodeLayerModules" BU_ NAG "Osek_TP.dll,FiatNM_B.dll,CANoeILNLFiat.dll";
BA_ "NodeLayerModules" BU_ NCP "Osek_TP.dll,FiatNM_B.dll,CANoeILNLFiat.dll";
BA_ "NodeLayerModules" BU_ NPR "Osek_TP.dll,CANoeILNLFiat.dll";
BA_ "NodeLayerModules" BU_ NSP "Osek_TP.dll,CANoeILNLFiat.dll";
BA_ "NodeLayerModules" BU_ NVO "Osek_TP.dll,CANoeILNLFiat.dll";
BA_ "NodeLayerModules" BU_ PLG "Osek_TP.dll,CANoeILNLFiat.dll";
BA_ "NodeLayerModules" BU_ BCM "Osek_TP.dll,FiatNM_B.dll,CANoeILNLFiat.dll";
BA_ "NodeLayerModules" BU_ RSL "Osek_TP.dll,FiatNM_B.dll,CANoeILNLFiat.dll";
BA_ "NodeLayerModules" BU_ RSR "Osek_TP.dll,FiatNM_B.dll,CANoeILNLFiat.dll";
BA_ "NodeLayerModules" BU_ SGW "Osek_TP.dll,CANoeILNLFiat.dll";
BA_ "NodeLayerModules" BU_ KHD "Osek_TP.dll,FiatNM_B.dll,CANoeILNLFiat.dll";
BA_ "NodeLayerModules" BU_ N3P "Osek_TP.dll,CANoeILNLFiat.dll";
BA_ "NodeLayerModules" BU_ ELR "Osek_TP.dll,FiatNM_B.dll,CANoeILNLFiat.dll";
BA_ "NodeLayerModules" BU_ ELL "Osek_TP.dll,FiatNM_B.dll,CANoeILNLFiat.dll";
BA_ "NodeLayerModules" BU_ ERL "Osek_TP.dll,FiatNM_B.dll,CANoeILNLFiat.dll";
BA_ "NodeLayerModules" BU_ ERR "Osek_TP.dll,FiatNM_B.dll,CANoeILNLFiat.dll";
BA_ "NodeLayerModules" BU_ NAP "Osek_TP.dll,FiatNM_B.dll,CANoeILNLFiat.dll";
BA_ "NodeLayerModules" BU_ RSH "Osek_TP.dll,FiatNM_B.dll,CANoeILNLFiat.dll";
VAL_ 222 LwsAngle 65535 "Invalid" ;
VAL_ 222 LwsSpeed 4095 "Invalid" ;
VAL_ 222 LwsCalibration 0 "Not_calibrated" 1 "Calibrated" ;
VAL_ 222 LWSFailSts 0 "Fail_not_Present" 1 "Fail_Present_Ignition_Latched" 2 "Fail_Present_Recoverable" 3 "FailPresentBatteryDisconnection" ;
VAL_ 222 LwsNEWCalibration 0 "Not_Active" 1 "Active" ;
VAL_ 359 IgnPosSts 0 "Initialization" 1 "IGN_LK" 2 "Shutdown_req" 3 "ACC" 4 "RUN" 5 "START" 6 "Not_used" 7 "SNA" ;
VAL_ 359 ValidKeySts 0 "CUST_IMMOB_KEY_DEFAULT" 1 "CUST_IMMOB_KEY_VALID" 2 "Not_used" 3 "SNA" ;
VAL_ 359 CustKeyInIgnSts 0 "CUST_KEY_DEFAULT" 1 "CUST_KEY_NOT_IN_IGNITION" 2 "CUST_KEY_IN_IGNITION" 3 "SNA" ;
VAL_ 359 RFFuncReq 0 "NO_BASIC_REQUEST" 1 "UNLOCK_BUTTON_Single_Pressure" 2 "UNLOCK_BUTTON_Double_Pressure" 3 "UNLOCK_BUTTON_Long_Pressure" 4 "LOCK_BUTTON_Single_Pressure" 5 "LOCK_BUTTON_Double_Pressure" 6 "LOCK_BUTTON_Long_Pressure" 7 "TRUNK_BUTTON_Single_Pressure" 8 "TRUNK_BUTTON_Double_Pressure" 9 "TRUNK_BUTTON_long_Pressure" 10 "BUTTON_D_Single_Pressure" 11 "BUTTON_D_Double_Pressure" 12 "BUTTON_D_long_Pressure" 13 "ALL_UNLOCK_REQUEST" 14 "BUTTON_A_Single_Pressure" 15 "BUTTON_A_Double_Pressure" 16 "BUTTON_A_Long_Pressure" 17 "BUTTON_B_Single_Pressure" 18 "BUTTON_B_Double_Pressure" 19 "BUTTON_B_Long_Pressure" 20 "BUTTON_C_Single_Pressure" 21 "BUTTON_C_Double_Pressure" 22 "BUTTON_C_Long_Pressure" 23 "Left_Unlatch_Switch_Actuation" 24 "Right_Unlatch_Switch_Actuation" 25 "Left_Lock_Switch_Actuation" 26 "Right_Lock_Switch_Actuation" 27 "Ext_Trunk_Open_Switch_Actuation" 28 "Button_C_Button_D_Single_Pressure" 29 "Button_C_Button_D_Long_Pressure" 30 "Charging_Open_Switch_Actuation" 31 "SNA" ;
VAL_ 359 RFFobNum 0 "FOB_DEFAULT" 1 "FOB_1" 2 "FOB_2" 3 "FOB_3" 4 "FOB_4" 5 "FOB_5" 6 "FOB_6" 7 "FOB_7" 8 "FOB_8" 9 "Not_used" 10 "Not_used" 11 "Not_used" 12 "Not_used" 13 "Not_used" 14 "Not_used" 15 "Not_used" ;
VAL_ 359 RFRearFuncReq 0 "NO_BASIC_REQUEST" 1 "RearLeftUnlatchSwitchActuation" 2 "RearRightUnlatchSwitchActuation" 3 "RearLeftLockSwitchActuation" 4 "RearRightLockSwitchActuation" 5 "Not_used" 6 "Not_used" 7 "SNA" ;
VAL_ 359 FobSearchResult 0 "No_Action" 1 "No_Action_ExteriorRear" 2 "No_Action_ExteriorLeft" 3 "No_Action_ExteriorRight" 4 "No_Action_Interior" 5 "Invalid" 6 "Invalid" 7 "Invalid" 8 "Interior" 9 "Invalid" 10 "Invalid" 11 "Invalid" 12 "Invalid" 13 "Invalid" 14 "Invalid" 15 "Invalid" 16 "No_Action_Trunk" 17 "Invalid" 18 "Invalid" 19 "Invalid" 20 "Invalid" 21 "Invalid" 22 "Invalid" 23 "Invalid" 24 "Invalid" 25 "Invalid" 26 "Invalid" 27 "Invalid" 28 "Invalid" 29 "Invalid" 30 "Invalid" 31 "Invalid" 32 "Fault" 33 "Fault" 34 "Fault" 35 "Fault" 36 "Fault" 37 "Fault" 38 "Fault" 39 "Fault" 40 "Fault" 41 "Fault" 42 "Fault" 43 "Fault" 44 "Fault" 45 "Fault" 46 "Fault" 47 "Fault" 48 "Fault" 49 "Fault" 50 "Fault" 51 "Fault" 52 "Fault" 53 "Fault" 54 "Fault" 55 "Fault" 56 "Fault" 57 "Fault" 58 "Fault" 59 "Fault" 60 "Fault" 61 "Fault" 62 "Fault" 63 "Fault" 64 "In_Progress" 65 "In_Progress" 66 "In_Progress" 67 "In_Progress" 68 "In_Progress" 69 "In_Progress" 70 "In_Progress" 71 "In_Progress" 72 "In_Progress" 73 "In_Progress" 74 "In_Progress" 75 "In_Progress" 76 "In_Progress" 77 "In_Progress" 78 "In_Progress" 79 "In_Progress" 80 "In_Progress" 81 "In_Progress" 82 "In_Progress" 83 "In_Progress" 84 "In_Progress" 85 "In_Progress" 86 "In_Progress" 87 "In_Progress" 88 "In_Progress" 89 "In_Progress" 90 "In_Progress" 91 "In_Progress" 92 "In_Progress" 93 "In_Progress" 94 "In_Progress" 95 "In_Progress" 96 "In_Progress" 97 "In_Progress" 98 "In_Progress" 99 "In_Progress" 100 "In_Progress" 101 "In_Progress" 102 "In_Progress" 103 "In_Progress" 104 "In_Progress" 105 "In_Progress" 106 "In_Progress" 107 "In_Progress" 108 "In_Progress" 109 "In_Progress" 110 "In_Progress" 111 "In_Progress" 112 "In_Progress" 113 "In_Progress" 114 "In_Progress" 115 "In_Progress" 116 "In_Progress" 117 "In_Progress" 118 "In_Progress" 119 "In_Progress" 120 "In_Progress" 121 "In_Progress" 122 "In_Progress" 123 "In_Progress" 124 "In_Progress" 125 "In_Progress" 126 "In_Progress" 127 "In_Progress" 128 "Complete_Key_not_found" 129 "Complete_ExteriorRear" 130 "Complete_ExteriorLeft" 131 "Invalid" 132 "Complete_ExteriorRight" 133 "Invalid" 134 "Invalid" 135 "Invalid" 136 "Complete_Interior" 137 "Invalid" 138 "Invalid" 139 "Invalid" 140 "Invalid" 141 "Invalid" 142 "Invalid" 143 "Invalid" 144 "Complete_Trunk" 145 "Invalid" 146 "Invalid" 147 "Invalid" 148 "Invalid" 149 "Invalid" 150 "Invalid" 151 "Invalid" 152 "Complete_TrunkInterior" 153 "Invalid" 154 "Invalid" 155 "Invalid" 156 "Invalid" 157 "Invalid" 158 "Invalid" 159 "Invalid" 160 "Fault" 161 "Fault" 162 "Fault" 163 "Fault" 164 "Fault" 165 "Fault" 166 "Fault" 167 "Fault" 168 "Fault" 169 "Fault" 170 "Fault" 171 "Fault" 172 "Fault" 173 "Fault" 174 "Fault" 175 "Fault" 176 "Fault" 177 "Fault" 178 "Fault" 179 "Fault" 180 "Fault" 181 "Fault" 182 "Fault" 183 "Fault" 184 "Fault" 185 "Fault" 186 "Fault" 187 "Fault" 188 "Fault" 189 "Fault" 190 "Fault" 191 "Fault" 192 "TimeOut" 193 "TimeOut" 194 "TimeOut" 195 "TimeOut" 196 "TimeOut" 197 "TimeOut" 198 "TimeOut" 199 "TimeOut" 200 "TimeOut" 201 "TimeOut" 202 "TimeOut" 203 "TimeOut" 204 "TimeOut" 205 "TimeOut" 206 "TimeOut" 207 "TimeOut" 208 "TimeOut" 209 "TimeOut" 210 "TimeOut" 211 "TimeOut" 212 "TimeOut" 213 "TimeOut" 214 "TimeOut" 215 "TimeOut" 216 "TimeOut" 217 "TimeOut" 218 "TimeOut" 219 "TimeOut" 220 "TimeOut" 221 "TimeOut" 222 "TimeOut" 223 "TimeOut" 224 "TimeOut" 225 "TimeOut" 226 "TimeOut" 227 "TimeOut" 228 "TimeOut" 229 "TimeOut" 230 "TimeOut" 231 "TimeOut" 232 "TimeOut" 233 "TimeOut" 234 "TimeOut" 235 "TimeOut" 236 "TimeOut" 237 "TimeOut" 238 "TimeOut" 239 "TimeOut" 240 "TimeOut" 241 "TimeOut" 242 "TimeOut" 243 "TimeOut" 244 "TimeOut" 245 "TimeOut" 246 "TimeOut" 247 "TimeOut" 248 "TimeOut" 249 "TimeOut" 250 "TimeOut" 251 "TimeOut" 252 "TimeOut" 253 "TimeOut" 254 "TimeOut" 255 "TimeOut" ;
VAL_ 359 RFReq 0 "REQUESTOR_DEFAULT" 1 "REQUESTOR_RKE" 2 "REQUESTOR_PE" 3 "REQUESTOR_REMOTESTART" 4 "REQUESTOR_UCONNECT" 5 "REQUESTOR_WalkAway" 6 "REQUESTOR_PE_KICKBOOT" 7 "SNA" ;
VAL_ 359 EmergencyShutdown 0 "Not_Active" 1 "Active" ;
VAL_ 359 FobSearchFault 0 "NO_FAULT" 1 "FAULT" ;
VAL_ 359 HMIPowerOnReq 0 "Not_Active" 1 "Active" ;
VAL_ 359 FOBInterferenceAvoid 0 "Not_Active" 1 "Active" ;
VAL_ 359 DriverEnginOffRequest 0 "Not_active" 1 "Active" ;
VAL_ 359 FobSearchResult_LongPressure 0 "No_Action" 1 "Research_in_progress" 2 "Not_Found" 3 "Found_ExteriorRear" 4 "Found_ExteriorLeft" 5 "Found_Exterior_Right" 6 "Found_Interior" 7 "Found_Trunk" ;
VAL_ 359 FobSearchExteriorRear 0 "NO_FOB_IN_ZONE" 1 "FOB_IN_ZONE" ;
VAL_ 359 FobSearchExteriorLeft 0 "NO_FOB_IN_ZONE" 1 "FOB_IN_ZONE" ;
VAL_ 359 FobSearchExteriorRight 0 "NO_FOB_IN_ZONE" 1 "FOB_IN_ZONE" ;
VAL_ 359 FobSearchInterior 0 "NO_FOB_IN_ZONE" 1 "FOB_IN_ZONE" ;
VAL_ 359 FobSearchTrunk 0 "NO_FOB_IN_ZONE" 1 "FOB_IN_ZONE" ;
VAL_ 359 FobSearchStatus 0 "NO_ACTION" 1 "IN_PROGRESS" 2 "COMPLETE" 3 "TIMEOUT" ;
VAL_ 359 KeyCommandReq 0 "Unlock" 1 "Lock" ;
VAL_ 359 NPE_ActuationReq 0 "No_Request" 1 "Insert_Key_Request" 2 "PowerOn_Request" 3 "PowerOff_Request" ;
VAL_ 384 FrontWiperServicePositionSts 0 "Not_Active" 1 "Active" ;
VAL_ 384 FrontWindWiperCarWashErrSts 0 "Not_Active" 1 "Active" ;
VAL_ 384 RearWindowWiperMotorErrorSts 0 "Not_Active" 1 "Active" ;
VAL_ 384 RearWindowWiperSts 0 "Not_Active" 1 "Active" ;
VAL_ 384 FrontWindshieldWiperMotErrSts 0 "Not_Active" 1 "Active" ;
VAL_ 384 NightDaySts 0 "Day" 1 "Night" ;
VAL_ 384 RearFogLightSts 0 "OFF" 1 "ON" ;
VAL_ 384 AHBFeature 0 "OFF" 1 "ON" ;
VAL_ 384 LowBeamSts 0 "OFF" 1 "ON" ;
VAL_ 384 HighBeamSts 0 "OFF" 1 "ON" ;
VAL_ 384 LHParkTailLightSts 0 "OFF" 1 "ON" ;
VAL_ 384 RHParkTailLightSts 0 "OFF" 1 "ON" ;
VAL_ 384 LHRTurnLightFailSts 0 "Fail_Not_Present" 1 "Fail_Present" ;
VAL_ 384 RHRTurnLightFailSts 0 "Fail_Not_Present" 1 "Fail_Present" ;
VAL_ 384 EXT_LGH_ParkingLightCmd 0 "Off" 1 "Left" 2 "Right" 3 "All" ;
VAL_ 384 RHeatedWindowSts 0 "OFF" 1 "ON" ;
VAL_ 384 RHTurnSignalSts 0 "OFF" 1 "ON" ;
VAL_ 384 LHTurnSignalSts 0 "OFF" 1 "ON" ;
VAL_ 384 RHRearFogLightFailSts 0 "Fail_Not_Present" 1 "Fail_Present" ;
VAL_ 384 LHRearFogLightFailSts 0 "Fail_Not_Present" 1 "Fail_Present" ;
VAL_ 384 RHStopLightFailSts 0 "Fail_Not_Present" 1 "Fail_Present" ;
VAL_ 384 LHStopLightFailSts 0 "Fail_Not_Present" 1 "Fail_Present" ;
VAL_ 384 LHFTurnLightFailSts 0 "Fail_Not_Present" 1 "Fail_Present" ;
VAL_ 384 RHFTurnLightFailSts 0 "Fail_Not_Present" 1 "Fail_Present" ;
VAL_ 384 WindStopperSts 0 "No_Movement" 1 "WindStopper_Opened" 2 "Capote_in_Movement" 3 "Rear_Seat_Belt_Fastened" 4 "Max_Speed_excided" 5 "Seat_Back_Folding" 6 "Not_used" 7 "Fail_Present" ;
VAL_ 384 PlateLightFailSts 0 "Fail_Not_Present" 1 "Fail_Present" ;
VAL_ 384 LHRParkTailLightFailSts 0 "Fail_Not_Present" 1 "Fail_Present" ;
VAL_ 384 RHRParkTailLightFailSts 0 "Fail_Not_Present" 1 "Fail_Present" ;
VAL_ 384 ExternalLightsSts 0 "AutoDay" 1 "AutoNight" 2 "ManualDay" 3 "ManualNight" ;
VAL_ 384 RearFog_Button 0 "Not_Active" 1 "Dir_1_Pressed" 2 "Dir_2_Pressed" 3 "Not_Used" ;
VAL_ 384 ParkingFeedbackLed 0 "LED_off" 1 "not_used" 2 "State_LED_on" 3 "Backlight_LED_on" ;
VAL_ 416 VPSDriverDoorKeySwitchOrFobCntrl 0 "Key_Switch_not_turned" 1 "Open_direction_released" 2 "Open_direction_turned_continous" 3 "Not_used" 4 "Open_direction_turned_twice" 5 "Not_used" 6 "Not_used" 7 "Not_used" 8 "Open_direction_turned_once" 9 "Not_used" 10 "Not_used" 11 "Not_used" 12 "Not_used" 13 "Not_used" 14 "Not_used" 15 "Not_used" 16 "Close_direction_released" 17 "Not_used" 18 "Not_used" 19 "Not_used" 20 "Not_used" 21 "Not_used" 22 "Not_used" 23 "Not_used" 24 "Not_used" 25 "Not_used" 26 "Not_used" 27 "Not_used" 28 "Not_used" 29 "Not_used" 30 "Not_used" 31 "Not_used" 32 "Close_direction_turned_continous" 33 "Not_used" 34 "Not_used" 35 "Not_used" 36 "Not_used" 37 "Not_used" 38 "Not_used" 39 "Not_used" 40 "Not_used" 41 "Not_used" 42 "Not_used" 43 "Not_used" 44 "Not_used" 45 "Not_used" 46 "Not_used" 47 "Not_used" 48 "Not_used" 49 "Not_used" 50 "Not_used" 51 "Not_used" 52 "Not_used" 53 "Not_used" 54 "Not_used" 55 "Not_used" 56 "Not_used" 57 "Not_used" 58 "Not_used" 59 "Not_used" 60 "Not_used" 61 "Not_used" 62 "Not_used" 63 "Not_used" 64 "Close_direction_turned_twice" 65 "Not_used" 66 "Not_used" 67 "Not_used" 68 "Not_used" 69 "Not_used" 70 "Not_used" 71 "Not_used" 72 "Not_used" 73 "Not_used" 74 "Not_used" 75 "Not_used" 76 "Not_used" 77 "Not_used" 78 "Not_used" 79 "Not_used" 80 "Not_used" 81 "Not_used" 82 "Not_used" 83 "Not_used" 84 "Not_used" 85 "Not_used" 86 "Not_used" 87 "Not_used" 88 "Not_used" 89 "Not_used" 90 "Not_used" 91 "Not_used" 92 "Not_used" 93 "Not_used" 94 "Not_used" 95 "Not_used" 96 "Not_used" 97 "Not_used" 98 "Not_used" 99 "Not_used" 100 "Not_used" 101 "Not_used" 102 "Not_used" 103 "Not_used" 104 "Not_used" 105 "Not_used" 106 "Not_used" 107 "Not_used" 108 "Not_used" 109 "Not_used" 110 "Not_used" 111 "Not_used" 112 "Not_used" 113 "Not_used" 114 "Not_used" 115 "Not_used" 116 "Not_used" 117 "Not_used" 118 "Not_used" 119 "Not_used" 120 "Not_used" 121 "Not_used" 122 "Not_used" 123 "Not_used" 124 "Not_used" 125 "Not_used" 126 "Not_used" 127 "Not_used" 128 "Close_direction_turned_once" 129 "Not_used" 130 "Not_used" 131 "Not_used" 132 "Not_used" 133 "Not_used" 134 "Not_used" 135 "Not_used" 136 "Not_used" 137 "Not_used" 138 "Not_used" 139 "Not_used" 140 "Not_used" 141 "Not_used" 142 "Not_used" 143 "Not_used" 144 "Not_used" 145 "Not_used" 146 "Not_used" 147 "Not_used" 148 "Not_used" 149 "Not_used" 150 "Not_used" 151 "Not_used" 152 "Not_used" 153 "Not_used" 154 "Not_used" 155 "Not_used" 156 "Not_used" 157 "Not_used" 158 "Not_used" 159 "Not_used" 160 "Not_used" 161 "Not_used" 162 "Not_used" 163 "Not_used" 164 "Not_used" 165 "Not_used" 166 "Not_used" 167 "Not_used" 168 "Not_used" 169 "Not_used" 170 "Not_used" 171 "Not_used" 172 "Not_used" 173 "Not_used" 174 "Not_used" 175 "Not_used" 176 "Not_used" 177 "Not_used" 178 "Not_used" 179 "Not_used" 180 "Not_used" 181 "Not_used" 182 "Not_used" 183 "Not_used" 184 "Not_used" 185 "Not_used" 186 "Not_used" 187 "Not_used" 188 "Not_used" 189 "Not_used" 190 "Not_used" 191 "Not_used" 192 "Not_used" 193 "Not_used" 194 "Not_used" 195 "Not_used" 196 "Not_used" 197 "Not_used" 198 "Not_used" 199 "Not_used" 200 "Not_used" 201 "Not_used" 202 "Not_used" 203 "Not_used" 204 "Not_used" 205 "Not_used" 206 "Not_used" 207 "Not_used" 208 "Not_used" 209 "Not_used" 210 "Not_used" 211 "Not_used" 212 "Not_used" 213 "Not_used" 214 "Not_used" 215 "Not_used" 216 "Not_used" 217 "Not_used" 218 "Not_used" 219 "Not_used" 220 "Not_used" 221 "Not_used" 222 "Not_used" 223 "Not_used" 224 "Not_used" 225 "Not_used" 226 "Not_used" 227 "Not_used" 228 "Not_used" 229 "Not_used" 230 "Not_used" 231 "Not_used" 232 "Not_used" 233 "Not_used" 234 "Not_used" 235 "Not_used" 236 "Not_used" 237 "Not_used" 238 "Not_used" 239 "Not_used" 240 "Not_used" 241 "Not_used" 242 "Not_used" 243 "Not_used" 244 "Not_used" 245 "Not_used" 246 "Not_used" 247 "Not_used" 248 "Not_used" 249 "Not_used" 250 "Not_used" 251 "Not_used" 252 "Not_used" 253 "Not_used" 254 "Not_used" 255 "Not_used" ;
VAL_ 416 VPSAIAlarmCauseCntrl 0 "Not_Active" 1 "Active" ;
VAL_ 416 VPSUSAlarmCauseCntrl 0 "Not_Active" 1 "Active" ;
VAL_ 416 VPSBonnetAlarmCauseCntrl 0 "Not_Active" 1 "Active" ;
VAL_ 416 VPSTrunkAlarmCauseCntrl 0 "Not_Active" 1 "Active" ;
VAL_ 416 VPSDoorsAlarmCauseCntrl 0 "Not_Active" 1 "Active" ;
VAL_ 416 VPSAlarmFailCntrl 0 "Fail_Not_Present" 1 "Fail_Present" ;
VAL_ 416 VPSCIDNotFoundCntrl 0 "CID_Found" 1 "CID_Not_Found" ;
VAL_ 416 VPSElectricalAlarmCauseCntrl 0 "Not_Active" 1 "Active" ;
VAL_ 499 KHDFailSts 0 "Fail_Not_Present" 1 "Fail_Present" ;
VAL_ 499 KeyHolderPosition 0 "Intermediate" 1 "Position1" 2 "Position2" 3 "Position3" 4 "not_used" 5 "not_used" 6 "not_used" 7 "Undefined" ;
VAL_ 499 KeyPresenceSts 0 "Nothing_Detected" 1 "NFC_Detected" 2 "KeyPresent" 3 "not_used" ;
VAL_ 518 VRD_RH 0 "Initialization" ;
VAL_ 518 LH_WheelDirectionSts 0 "Standstill_no_direction_detected" 1 "Forward" 2 "Backward" 3 "Invalid" ;
VAL_ 518 VRD_LHValidData 0 "Valid" 1 "Not_valid" ;
VAL_ 518 RH_WheelDirectionSts 0 "Standstill_no_direction_detected" 1 "Forward" 2 "Backward" 3 "Invalid" ;
VAL_ 518 VRD_RHValidData 0 "Valid" 1 "Not_valid" ;
VAL_ 518 VRD_LH 0 "Initialization" ;
VAL_ 518 VehicleDirection 0 "Standstill" 1 "Forward" 2 "Backward" 3 "Not_Available" ;
VAL_ 524 VehicleSpeed_ASILxFailSts 0 "Fail_not_present" 1 "Fail_present" ;
VAL_ 524 VehicleSpeedVSOSigFailSts 0 "Fail_not_present" 1 "Fail_present" ;
VAL_ 524 NFR_Speed_FA_FailSts 0 "Fail_not_present" 1 "Fail_present" ;
VAL_ 524 NFRCruiseEnabler 0 "CC_Enabled" 1 "CC_Not_Enabled" ;
VAL_ 550 VRD_RV 0 "Initialization" ;
VAL_ 550 LV_WheelDirectionSts 0 "Standstill_no_direction_detected" 1 "Forward" 2 "Backward" 3 "Invalid" ;
VAL_ 550 VRD_LVValidData 0 "Valid" 1 "Not_valid" ;
VAL_ 550 RV_WheelDirectionSts 0 "Standstill_no_direction_detected" 1 "Forward" 2 "Backward" 3 "Invalid" ;
VAL_ 550 VRD_RVValidData 0 "Valid" 1 "Not_valid" ;
VAL_ 550 VRD_LV 0 "Initialization" ;
VAL_ 599 SBR2RowCentralSeatBuckleFailSts 0 "Fail_Not_Present" 1 "Fail_Present" 2 "Not_used" 3 "SNA" ;
VAL_ 599 SBR2RowCentralSeatConfigSts 0 "Seat_Not_Checked" 1 "Seat_Checked" ;
VAL_ 599 AirBagFailSts 0 "Fail_Not_Present_Lamp_Off" 1 "Fail_Not_Present_Lamp_Flashing" 2 "Fail_Present_Lamp_On" 3 "Not_used" ;
VAL_ 599 SBR1RowDriverSeatFailSts 0 "Fail_Not_Present" 1 "Fail_Present" 2 "Not_used" 3 "SNA" ;
VAL_ 599 SBR1RowDriverSeatConfigSts 0 "Seat_Not_Checked" 1 "Seat_Checked" ;
VAL_ 599 SBR2RowCentralSeatSts 0 "Seat_Belt_Fasten" 1 "Seat_Belt_Not_Fasten" 2 "Seat_Safe" 3 "Seat_Not_Safe" 4 "Not_used" 5 "Not_used" 6 "Not_used" 7 "SNA" ;
VAL_ 599 SBR1RowCentralSeatPPDFailSts 0 "Fail_Not_Present" 1 "Fail_Present" 2 "Not_used" 3 "SNA" ;
VAL_ 599 SBR1RowPsngrSeatPPDFailSts 0 "Fail_Not_Present" 1 "Fail_Present" 2 "Not_used" 3 "SNA" ;
VAL_ 599 SBR1RowPsngrSeatBuckleFailSts 0 "Fail_Not_Present" 1 "Fail_Present" 2 "Not_used" 3 "SNA" ;
VAL_ 599 SBR1RowPsngrSeatConfigSts 0 "Seat_Not_Checked" 1 "Seat_Checked" ;
VAL_ 599 SBR1RowDriverSeatSts 0 "Seat_Belt_Fasten" 1 "Seat_Belt_Not_Fasten" 2 "Not_used" 3 "SNA" ;
VAL_ 599 SBR2RowLeftSeatSts 0 "Seat_Belt_Fasten" 1 "Seat_Belt_Not_Fasten" 2 "Not_used" 3 "SNA" ;
VAL_ 599 SBR2RowRightSeatFailSts 0 "Fail_Not_Present" 1 "Fail_Present" 2 "Not_used" 3 "SNA" ;
VAL_ 599 SBR2RowLeftSeatFailSts 0 "Fail_Not_Present" 1 "Fail_Present" 2 "Not_used" 3 "SNA" ;
VAL_ 599 SBR1RowPsngrSeatSts 0 "Seat_Belt_Fasten" 1 "Seat_Belt_Not_Fasten" 2 "Seat_Safe" 3 "Seat_Not_Safe" 4 "Not_used" 5 "Not_used" 6 "Not_used" 7 "SNA" ;
VAL_ 599 CrashOutputSts 0 "No_crash" 1 "Front_Pretensioner" 2 "Front_First_Level" 4 "Front_Second_Level" 8 "Passenger_Side" 16 "Driver_Side" 32 "Rear" 64 "Rollover" 128 "Pedestrian" ;
VAL_ 599 SBR2RowRightSeatSts 0 "Seat_Belt_Fasten" 1 "Seat_Belt_Not_Fasten" 2 "Not_used" 3 "SNA" ;
VAL_ 599 CrashOutputValidData 0 "Valid" 1 "Not_Valid" ;
VAL_ 599 AirBagWarningPADLampOnSts 0 "PADLampON_OK" 1 "PADLampON_Fail" ;
VAL_ 599 AirBagWarningPADLampOffSts 0 "PADLampOFF_OK" 1 "PADLampOFF_Fail" ;
VAL_ 599 SBR2RowRightSeatConfigSts 0 "Seat_Not_Checked" 1 "Seat_Checked" ;
VAL_ 599 SBR2RowLeftSeatConfigSts 0 "Seat_Not_Checked" 1 "Seat_Checked" ;
VAL_ 599 Ppd_psngr_info 0 "passenger_absent" 1 "passenger_present" 2 "PPD_Fault" 3 "PPD_device_not_present" ;
VAL_ 599 AirBagWarningLampSts 0 "Lamp_OK" 1 "Lamp_in_Fail" ;
VAL_ 599 AirBagWarningPADPassengerAirbagS 0 "PassengerAirbag_OK" 1 "PassengerAirbag_Fail" ;
VAL_ 631 ETXV2_Sts 0 "Not active by VCU" 1 "Not active by driver" 2 "Not used" 3 "Active" ;
VAL_ 631 Cabin_Energy_Deactivation_PopUp 0 "No_visualization" 1 "Pre_warning_message" 2 "Turn_Off_loads_message" 3 "Not_used" ;
VAL_ 631 ETXV1_Sts 0 "Not active by VCU" 1 "Not active by driver" 2 "Not used" 3 "Active" ;
VAL_ 631 InputHeaterCore_FlowRate 63 "SNA" ;
VAL_ 631 CabinPrecondReq 0 "No_Request" 1 "Activation" ;
VAL_ 631 T_InHeaterCore 127 "SNA" ;
VAL_ 631 CabinPrecondSts 0 "Not_Active" 1 "Active" 2 "Active_TargetReached" ;
VAL_ 631 HVACSts 0 "Off" 1 "On" ;
VAL_ 631 CabinPrecondProgress 255 "SNA" ;
VAL_ 631 CabinEstTimeToTarget 127 "SNA" ;
VAL_ 641 EDriveSts 0 "Off" 1 "Prepare_E_Drive" 2 "E_Drive" 3 "Stop_E_Drive" ;
VAL_ 641 EngineSts 0 "Engine_OFF" 1 "Engine_ON" 2 "Engine_cranking" 3 "Engine_Shut_down" ;
VAL_ 641 StopStartSts 0 "Off" 1 "On" 2 "Engine_Restart" 3 "Stop_Request" ;
VAL_ 647 T_InFrontEvapHVAC 127 "SNA" ;
VAL_ 647 T_inFrontEvapHVACFailSts 0 "Not_Present" 1 "Present" ;
VAL_ 647 T_InRearEvapHVAC 127 "SNA" ;
VAL_ 647 T_inRearEvapHVACFailSts 0 "Not_Present" 1 "Present" ;
VAL_ 647 ClimateRearAirFlow 127 "SNA" ;
VAL_ 647 CoolDown 0 "Not_Active" 1 "Active" ;
VAL_ 647 T_outFrontEvapHVAC 1023 "SNA" ;
VAL_ 647 T_outFrontEvapHVACFailSts 0 "Not_Present" 1 "Present" ;
VAL_ 647 T_outRearEvapHVAC 1023 "SNA" ;
VAL_ 647 T_outRearEvapHVACFailSts 0 "Not_Present" 1 "Present" ;
VAL_ 647 ClimateFrontAirFlow 127 "SNA" ;
VAL_ 648 NCL_MinimumFlow 31 "SNA" ;
VAL_ 648 T_TargetInHeaterCore 127 "SNA" ;
VAL_ 648 T_TargetOutEvapHVAC 31 "SNA" ;
VAL_ 648 Heating_Req 0 "Not_Active" 1 "Active" ;
VAL_ 648 AC_Req_Rear 0 "Not_Active" 1 "Active" ;
VAL_ 648 AC_Req_Front 0 "Not_Active" 1 "Active" ;
VAL_ 651 ActualGearForDisplay 0 "Not_coded" 1 "_1st_gear" 2 "_2nd_gear" 3 "_3rd_gear" 4 "_4th_gear" 5 "_5th_gear" 6 "_6th_gear" 7 "_7th_gear" 8 "'8th gear'" 9 "Not_used" 10 "Not_used" 11 "'P'" 12 "'D'" 13 "'L'" 14 "'R'" 15 "'N'" ;
VAL_ 651 VPSTrunkSts 0 "Closed_Unlocked" 1 "Closed_Locked" 2 "Open_Unlocked" 3 "Open_Locked" ;
VAL_ 671 SuspensionSetupSts 0 "Follow_Manettino_Sts" 1 "Position_1" 2 "Position_2" 3 "Position_3" 4 "Not_used" 5 "Not_used" 6 "Not_used" 7 "Status_already_selected" ;
VAL_ 671 SuspensionSystemInfoForDisplay 0 "No_Info" 1 "Fault" 2 "Degraded" 3 "Not_Available" 4 "Critical_Fault" 5 "Not_Used" 6 "Not_Used" 7 "Not_Used" ;
VAL_ 671 SuspensionSetupInfoForDisplay 0 "No_Visualization" 1 "position_1" 2 "position_2" 4 "position_3" 5 "Not_used" 6 "Not_used" 7 "Status_Already_Selected" ;
VAL_ 672 VehicleSpeedFailSts 0 "Fail_Not_Present" 1 "Fail_Present" ;
VAL_ 673 EngineSts 0 "Engine_OFF" 1 "Engine_ON" 2 "Engine_cranking" 3 "Engine_Shut_down" ;
VAL_ 673 StopStartSts 0 "Off" 1 "On" 2 "Engine_Restart" 3 "Stop_Request" ;
VAL_ 673 EDriveSts 0 "Off" 1 "Prepare_E_Drive" 2 "E_Drive" 3 "Stop_E_Drive" ;
VAL_ 684 LWS_Angle 32767 "Invalid" ;
VAL_ 684 LWS_OK 0 "Not_Valid" 1 "Valid" ;
VAL_ 761 GearLeverPositionforNPE 0 "P" 1 "N" 2 "R" 3 "D" 4 "Not_used" 5 "Unknown" 6 "Transition" 7 "Not_used" ;
VAL_ 761 GearLeverFailForNPE 0 "No_Fail" 1 "Fail" ;
VAL_ 764 JoystickMovement 0 "No_Movement" 1 "Move_Left" 2 "Move_Right" 3 "Move_Up" 4 "Move_Down" 5 "Pushed_In" 6 "Pulled_Out" 7 "Not_used" 8 "Not_used" 9 "Not_used" 10 "Not_used" 11 "Not_used" 12 "Not_used" 13 "Not_used" 14 "Not_used" 15 "Not_used" ;
VAL_ 764 Right_Mirror_Button 0 "Not_Active" 1 "Active" ;
VAL_ 764 Left_Mirror_Button 0 "Not_Active" 1 "Active" ;
VAL_ 764 Fold_Unfold_Button 0 "Not Active" 1 "Active" ;
VAL_ 764 Steering_Adj_Button 0 "Not_Active" 1 "Active" ;
VAL_ 765 AvasAlertSound 0 "Off" 1 "On" ;
VAL_ 765 AVASFailSts 0 "Fail_not_present" 1 "Fail_Present" ;
VAL_ 865 EngineSpeedValidData 0 "Valid" 1 "Not_valid" ;
VAL_ 865 CylCutEnabled 0 "Cyl_Cut_not_enabled_for_DCT" 1 "Cyl_Cut_enabled_for_DCT" ;
VAL_ 865 VehDriverReqTrqValidData 0 "Valid" 1 "Not_valid" ;
VAL_ 873 PLGSts 0 "Not_Used" 1 "Manually_opening" 2 "Automatic_opening" 3 "Open" 4 "Manually_closing" 5 "Automatic_closing" 6 "Close" 7 "GaragePosition" 8 "UpperEndPosition" 9 "Antipinch" 10 "GaragePositionCONFIRMED" 11 "GaragePositionCANCELLED" 12 "Not_Used" 13 "Not_Used" 14 "Not_Used" 15 "Not_Used" ;
VAL_ 873 PLGInfoForDisplay 0 "No_Message" 1 "System_Malfuction" 2 "Obstacle_Detection" 3 "Manual_Close_Required" 4 "PLG_Open_Reminder" 5 "PLG_Open" 6 "Not_Used" 7 "Not_Used" 8 "Not_Used" 9 "Not_Used" 10 "Not_Used" 11 "Not_Used" 12 "Not_Used" 13 "Not_Used" 14 "Not_Used" 15 "Not_Used" ;
VAL_ 873 PLGPositionValidData 0 "Valid" 1 "Not_valid" ;
VAL_ 873 PLGBlockingDetection 0 "Not_detected" 1 "detected" ;
VAL_ 873 PLGFailSts 0 "No_fail" 1 "fail" 2 "Not_Used" 3 "Not_Used" ;
VAL_ 873 PLGButtonSts 0 "Not_Active" 1 "Active" ;
VAL_ 873 PLGAlert 0 "No_Chime" 1 "Single_Chime" 2 "Double_Chime" 3 "Garage_Chime" ;
VAL_ 873 PLGCloseLock 0 "Not_Active" 1 "Active" ;
VAL_ 896 SysEOLSts 0 "EOL_Ready" 1 "EOL_Not_Ready" ;
VAL_ 896 InternalLightSts 0 "Not_active" 1 "Active" ;
VAL_ 896 VehicleNotInUseSignaling 0 "Not_Active" 1 "Active" ;
VAL_ 896 InternalBacklightStsKeyOff 0 "OFF" 1 "ON" ;
VAL_ 896 BrakePadWearSts 0 "OK" 1 "NOT_OK" ;
VAL_ 896 WishWashSts 0 "OFF" 1 "ON" ;
VAL_ 896 PsngrDoorSts 0 "Closed" 1 "Open" ;
VAL_ 896 PLGCommand2 0 "No_Command" 1 "Stop_Movement" 2 "Not_used" 3 "Not_used" ;
VAL_ 896 RhatchSts 0 "Closed" 1 "Open" ;
VAL_ 896 BonnetSts 0 "Closed" 1 "Open" ;
VAL_ 896 ReverseGearBCSts 0 "Not_inserted" 1 "Inserted" ;
VAL_ 896 KeySts 0 "Data_not_valid" 1 "STOP" 2 "PARK" 3 "Not_used" 4 "ON" 5 "Not_used" 6 "Not_used" 7 "Not_used" 8 "Not_used" 9 "Not_used" 10 "Not_used" 11 "Not_used" 12 "CRANK_ON" 13 "Not_used" 14 "Not_used" 15 "Not_used" ;
VAL_ 896 NBCFISSts 0 "Not_active" 1 "Active" ;
VAL_ 896 FuelLevelFailSts 0 "Fail_Not_Present" 1 "Fail_Present" ;
VAL_ 896 LowFuelWarningSts 0 "OFF" 1 "ON" ;
VAL_ 896 FuelLevel 255 "FaultValue_F149" ;
VAL_ 896 IMMOCodeWarningLightSts 1 "Flashing_code" 2 "Flashing_code" 3 "Flashing_code" 4 "Flashing_code" 5 "Flashing_code" 6 "Flashing_code" 7 "Flashing_code" 8 "Flashing_code" 9 "Flashing_code" 10 "Flashing_code" 11 "Flashing_code" 12 "Flashing_code" 13 "Flashing_code" 14 "Flashing_code" 15 "Flashing_code" 16 "Flashing_code" 17 "Flashing_code" 18 "Flashing_code" ;
VAL_ 896 TurnIndicatorSts 0 "Center" 1 "Left" 2 "Right" 3 "SNA" ;
VAL_ 896 RainSensorFailSts 0 "Fail_Not_Present" 1 "Fail_Present" ;
VAL_ 904 ExternalTemperature 0 "FaultValue" ;
VAL_ 904 DriverAntiPinchFailSts 0 "Fail_Not_Present" 1 "Fail_Present" ;
VAL_ 904 PsngrAntiPinchFailSts 0 "Fail_Not_Present" 1 "Fail_Present" ;
VAL_ 904 ExternalTemperatureFailSts 0 "Fail_Not_Present" 1 "Fail_Present" ;
VAL_ 904 DriverHRWindowsUpSts 0 "Not_active" 1 "Active" ;
VAL_ 904 DriverHRWindowsDownSts 0 "Not_active" 1 "Active" ;
VAL_ 904 DriverCmdCompleteCntrl 0 "Not_active" 1 "Active" ;
VAL_ 904 FoldMirrorSts 0 "Unfolded" 1 "Folded" ;
VAL_ 904 DriverWindowSts 0 "Open" 1 "Close" 2 "Middle" 3 "Running_Up" 4 "Running_Down" 5 "Reverse" 6 "Short_drop" 7 "SNA" ;
VAL_ 904 E_LatchDriverFailSts 0 "Fail_Not_Present" 1 "Fail_Present" ;
VAL_ 904 WLMDriverFailSts 0 "Fail_Not_Present" 1 "Fail_Present" ;
VAL_ 906 MaxDefrostSts 0 "OFF" 1 "ON" ;
VAL_ 906 RHeatedWindowCntrl 0 "Not_Active" 1 "Active" ;
VAL_ 906 PowerModeSts 0 "Standard_Power" 1 "Logistic_Mode_ON" 2 "Not_used" 3 "Not_used" ;
VAL_ 906 ADAS_heater 0 "Denied" 1 "Allowed" ;
VAL_ 906 FogRisk 0 "Disable" 1 "Enable" ;
VAL_ 906 AirQualityIndex 0 "No_visual_feedback" 1 "_1" 2 "_2" 3 "_3" 4 "_4" 5 "_5" 6 "_6" 7 "_7" 8 "_8" 9 "_9" 10 "_10" 11 "_11" 12 "_12" 13 "_13" 14 "_14" 15 "_15" 16 "_16" 17 "_17" 18 "_18" 19 "_19" 20 "_20" 21 "_21" 22 "_22" 23 "_23" 24 "_24" 25 "_25" 26 "_26" 27 "_27" 28 "_28" 29 "_29" 30 "_30" 31 "_31" 32 "_32" 33 "_33" 34 "_34" 35 "_35" 36 "_36" 37 "_37" 38 "_38" 39 "_39" 40 "_40" 41 "_41" 42 "_42" 43 "_43" 44 "_44" 45 "_45" 46 "_46" 47 "_47" 48 "_48" 49 "_49" 50 "_50" 51 "_51" 52 "_52" 53 "_53" 54 "_54" 55 "_55" 56 "_56" 57 "_57" 58 "_58" 59 "_59" 60 "_60" 61 "_61" 62 "_62" 63 "_63" 64 "_64" 65 "_65" 66 "_66" 67 "_67" 68 "_68" 69 "_69" 70 "_70" 71 "_71" 72 "_72" 73 "_73" 74 "_74" 75 "_75" 76 "_76" 77 "_77" 78 "_78" 79 "_79" 80 "_80" 81 "_81" 82 "_82" 83 "_83" 84 "_84" 85 "_85" 86 "_86" 87 "_87" 88 "_88" 89 "_89" 90 "_90" 91 "_91" 92 "_92" 93 "_93" 94 "_94" 95 "_95" 96 "_96" 97 "_97" 98 "_98" 99 "_99" 100 "_100" 101 "_101" 102 "_102" 103 "_103" 104 "_104" 105 "_105" 106 "_106" 107 "_107" 108 "_108" 109 "_109" 110 "_110" 111 "_111" 112 "_112" 113 "_113" 114 "_114" 115 "_115" 116 "_116" 117 "_117" 118 "_118" 119 "_119" 120 "_120" 121 "_121" 122 "_122" 123 "_123" 124 "_124" 125 "_125" 126 "_126" 127 "_127" 128 "_128" 129 "_129" 130 "_130" 131 "_131" 132 "_132" 133 "_133" 134 "_134" 135 "_135" 136 "_136" 137 "_137" 138 "_138" 139 "_139" 140 "_140" 141 "_141" 142 "_142" 143 "_143" 144 "_144" 145 "_145" 146 "_146" 147 "_147" 148 "_148" 149 "_149" 150 "_150" 151 "_151" 152 "_152" 153 "_153" 154 "_154" 155 "_155" 156 "_156" 157 "_157" 158 "_158" 159 "_159" 160 "_160" 161 "_161" 162 "_162" 163 "_163" 164 "_164" 165 "_165" 166 "_166" 167 "_167" 168 "_168" 169 "_169" 170 "_170" 171 "_171" 172 "_172" 173 "_173" 174 "_174" 175 "_175" 176 "_176" 177 "_177" 178 "_178" 179 "_179" 180 "_180" 181 "_181" 182 "_182" 183 "_183" 184 "_184" 185 "_185" 186 "_186" 187 "_187" 188 "_188" 189 "_189" 190 "_190" 191 "_191" 192 "_192" 193 "_193" 194 "_194" 195 "_195" 196 "_196" 197 "_197" 198 "_198" 199 "_199" 200 "_200" 201 "_201" 202 "_202" 203 "_203" 204 "_204" 205 "_205" 206 "_206" 207 "_207" 208 "_208" 209 "_209" 210 "_210" 211 "_211" 212 "_212" 213 "_213" 214 "_214" 215 "_215" 216 "_216" 217 "_217" 218 "_218" 219 "_219" 220 "_220" 221 "_221" 222 "_222" 223 "_223" 224 "_224" 225 "_225" 226 "_226" 227 "_227" 228 "_228" 229 "_229" 230 "_230" 231 "_231" 232 "_232" 233 "_233" 234 "_234" 235 "_235" 236 "_236" 237 "_237" 238 "_238" 239 "_239" 240 "_240" 241 "_241" 242 "_242" 243 "_243" 244 "_244" 245 "_245" 246 "_246" 247 "_247" 248 "_248" 249 "_249" 250 "_250" 251 "_251" 252 "_252" 253 "_253" 254 "_254" 255 "_255" 256 "_256" 257 "_257" 258 "_258" 259 "_259" 260 "_260" 261 "_261" 262 "_262" 263 "_263" 264 "_264" 265 "_265" 266 "_266" 267 "_267" 268 "_268" 269 "_269" 270 "_270" 271 "_271" 272 "_272" 273 "_273" 274 "_274" 275 "_275" 276 "_276" 277 "_277" 278 "_278" 279 "_279" 280 "_280" 281 "_281" 282 "_282" 283 "_283" 284 "_284" 285 "_285" 286 "_286" 287 "_287" 288 "_288" 289 "_289" 290 "_290" 291 "_291" 292 "_292" 293 "_293" 294 "_294" 295 "_295" 296 "_296" 297 "_297" 298 "_298" 299 "_299" 300 "_300" 301 "_301" 302 "_302" 303 "_303" 304 "_304" 305 "_305" 306 "_306" 307 "_307" 308 "_308" 309 "_309" 310 "_310" 311 "_311" 312 "_312" 313 "_313" 314 "_314" 315 "_315" 316 "_316" 317 "_317" 318 "_318" 319 "_319" 320 "_320" 321 "_321" 322 "_322" 323 "_323" 324 "_324" 325 "_325" 326 "_326" 327 "_327" 328 "_328" 329 "_329" 330 "_330" 331 "_331" 332 "_332" 333 "_333" 334 "_334" 335 "_335" 336 "_336" 337 "_337" 338 "_338" 339 "_339" 340 "_340" 341 "_341" 342 "_342" 343 "_343" 344 "_344" 345 "_345" 346 "_346" 347 "_347" 348 "_348" 349 "_349" 350 "_350" 351 "_351" 352 "_352" 353 "_353" 354 "_354" 355 "_355" 356 "_356" 357 "_357" 358 "_358" 359 "_359" 360 "_360" 361 "_361" 362 "_362" 363 "_363" 364 "_364" 365 "_365" 366 "_366" 367 "_367" 368 "_368" 369 "_369" 370 "_370" 371 "_371" 372 "_372" 373 "_373" 374 "_374" 375 "_375" 376 "_376" 377 "_377" 378 "_378" 379 "_379" 380 "_380" 381 "_381" 382 "_382" 383 "_383" 384 "_384" 385 "_385" 386 "_386" 387 "_387" 388 "_388" 389 "_389" 390 "_390" 391 "_391" 392 "_392" 393 "_393" 394 "_394" 395 "_395" 396 "_396" 397 "_397" 398 "_398" 399 "_399" 400 "_400" 401 "_401" 402 "_402" 403 "_403" 404 "_404" 405 "_405" 406 "_406" 407 "_407" 408 "_408" 409 "_409" 410 "_410" 411 "_411" 412 "_412" 413 "_413" 414 "_414" 415 "_415" 416 "_416" 417 "_417" 418 "_418" 419 "_419" 420 "_420" 421 "_421" 422 "_422" 423 "_423" 424 "_424" 425 "_425" 426 "_426" 427 "_427" 428 "_428" 429 "_429" 430 "_430" 431 "_431" 432 "_432" 433 "_433" 434 "_434" 435 "_435" 436 "_436" 437 "_437" 438 "_438" 439 "_439" 440 "_440" 441 "_441" 442 "_442" 443 "_443" 444 "_444" 445 "_445" 446 "_446" 447 "_447" 448 "_448" 449 "_449" 450 "_450" 451 "_451" 452 "_452" 453 "_453" 454 "_454" 455 "_455" 456 "_456" 457 "_457" 458 "_458" 459 "_459" 460 "_460" 461 "_461" 462 "_462" 463 "_463" 464 "_464" 465 "_465" 466 "_466" 467 "_467" 468 "_468" 469 "_469" 470 "_470" 471 "_471" 472 "_472" 473 "_473" 474 "_474" 475 "_475" 476 "_476" 477 "_477" 478 "_478" 479 "_479" 480 "_480" 481 "_481" 482 "_482" 483 "_483" 484 "_484" 485 "_485" 486 "_486" 487 "_487" 488 "_488" 489 "_489" 490 "_490" 491 "_491" 492 "_492" 493 "_493" 494 "_494" 495 "_495" 496 "_496" 497 "_497" 498 "_498" 499 "_499" 500 "_500" 501 "Not_used" 502 "Not_used" 503 "Not_used" 504 "Not_used" 505 "Not_used" 506 "Not_used" 507 "Not_used" 508 "Not_used" 509 "Not_used" 510 "Not_used" 511 "Not_used" ;
VAL_ 906 NCL_RimHeatingCommand 0 "Not_Active" 1 "Active" ;
VAL_ 906 NPRActivationReq 0 "Not_Active" 1 "Active" ;
VAL_ 906 NCL_FrontPassengerHeating 0 "Not_Active" 1 "Heat_Level1" 2 "Heat_Level2" 3 "Heat_Level3" ;
VAL_ 906 NCL_PassengerFans 0 "Not_Active" 1 "Fan_Level1" 2 "Fan_Level2" 3 "Fan_Level3" ;
VAL_ 906 NCL_FrontDriverHeating 0 "Not_Active" 1 "Heat_Level1" 2 "Heat_Level2" 3 "Heat_Level3" ;
VAL_ 906 NCL_DriverFans 0 "Not_Active" 1 "Fan_Level1" 2 "Fan_Level2" 3 "Fan_Level3" ;
VAL_ 906 NCL_RRHeating 0 "Not_Active" 1 "Heat_Level1" 2 "Heat_Level2" 3 "Heat_Level3" ;
VAL_ 906 NCL_RRFans 0 "Not_Active" 1 "Fan_Level1" 2 "Fan_Level2" 3 "Fan_Level3" ;
VAL_ 906 NCL_RLHeating 0 "Not_Active" 1 "Heat_Level1" 2 "Heat_Level2" 3 "Heat_Level3" ;
VAL_ 906 NCL_RLFans 0 "Not_Active" 1 "Fan_Level1" 2 "Fan_Level2" 3 "Fan_Level3" ;
VAL_ 952 FrameNumber 0 "frame_1" 1 "frame_2" 2 "not_used" 3 "not_used" ;
VAL_ 952 TotalFrameNumber 0 "not_used" 1 "two_frames" 2 "not_used" 3 "not_used" ;
VAL_ 952 NSPFailSts 0 "No_Fail" 1 "Front_Failure" 2 "Rear_Failure" 3 "System_failure" ;
VAL_ 952 NSPControlSts 0 "System_Active_Rear_AND_Front" 1 "Only_Front_sensors_are_active" 2 "Only_Rear_sensors_are_active" 3 "System_Not_active" ;
VAL_ 952 LHNSPBuzzerReqSts 0 "Not_Active" 1 "Active" ;
VAL_ 952 LHLateralcolour 0 "no_colour" 1 "green" 2 "yellow" 3 "red" ;
VAL_ 952 RHNSPBuzzerReqSts 0 "Not_Active" 1 "Active" ;
VAL_ 952 LHCentralcolour 0 "no_colour" 1 "green" 2 "yellow" 3 "red" ;
VAL_ 952 CNSPBuzzerReqSts 0 "Not_Active" 1 "Active" ;
VAL_ 952 RHCentralcolour 0 "no_colour" 1 "green" 2 "yellow" 3 "red" ;
VAL_ 952 RHLateralcolour 0 "no_colour" 1 "green" 2 "yellow" 3 "red" ;
VAL_ 952 CapoteMovement 0 "Disabled" 1 "Enabled" 2 "Checking" 3 "Not_used" ;
VAL_ 952 NSPBuzzerRepetitionRate 0 "_3_beep_sec" 1 "_6_beep_sec" 2 "_9_beep_sec" 3 "Continuous" ;
VAL_ 960 ExternalLightSensorSts 0 "Not_Active" 1 "Active" ;
VAL_ 960 FuelFlapSts 0 "Closed" 1 "Opened" ;
VAL_ 960 TyrePressureSystemFailSts 0 "Fail_Not_Present" 1 "Fail_Present" ;
VAL_ 960 Night_E_DaySensorFailSts 0 "Fail_Not_Present" 1 "Fail_Present" ;
VAL_ 960 RHRTyrePressureSts 0 "Fail_Not_Present" 1 "Low_Pressure_Soft_warning" 2 "Flat_Tyre_Hard_warning" 3 "High_Temperature" ;
VAL_ 960 LHRTyrePressureSts 0 "Fail_Not_Present" 1 "Low_Pressure_Soft_warning" 2 "Flat_Tyre_Hard_warning" 3 "High_Temperature" ;
VAL_ 960 RHFTyrePressureSts 0 "Fail_Not_Present" 1 "Low_Pressure_Soft_warning" 2 "Flat_Tyre_Hard_warning" 3 "High_Temperature" ;
VAL_ 960 LHFTyrePressureSts 0 "Fail_Not_Present" 1 "Low_Pressure_Soft_warning" 2 "Flat_Tyre_Hard_warning" 3 "High_Temperature" ;
VAL_ 960 LeftChildLockCntrl 0 "Not_Active" 1 "Active" ;
VAL_ 960 RechargeFlapDisplayInfo 0 "Recharge_Flap_Open" 1 "Recharge_Flap_Close" 2 "Inpossible_to_open_Flap" 3 "Epb_not_inserrted" 4 "ImpossibleToOpenChargingFlap" 5 "EPBUnavailableNoCharging" 6 "ChargingFlapOpenPleaseCloseIt" 7 "No_Message" 8 "Opening_Not_Allowed" 9 "End_Of_Capote_Cycle" 10 "Not_used" 11 "Not_used" 12 "Not_used" 13 "Not_used" 14 "Not_used" 15 "Not_used" ;
VAL_ 960 PLGBlink_Fbk 0 "Blink_Not_Completed" 1 "Blink_Completed" ;
VAL_ 960 RimHeatingFbk 0 "Not_Active" 1 "Active" 2 "Fail_Present" 3 "Not_used" ;
VAL_ 960 DriverSide 0 "Left_side_driver_Not_Programmed" 1 "Right_side_driver" ;
VAL_ 960 RHatchStsForNCP 0 "Closed" 1 "Open" ;
VAL_ 960 PowerModeSts 0 "Standard_Power" 1 "Logistic_Mode_ON" 2 "Not_used" 3 "Not_used" ;
VAL_ 960 TrunkCinchSts 0 "Extended" 1 "Retracted" 2 "Intermediate" 3 "Error" ;
VAL_ 960 RightChildLockCntrl 0 "Not_Active" 1 "Active" ;
VAL_ 960 PLGCommandSource 0 "No_Command" 1 "RF" 2 "External" 3 "Internal" ;
VAL_ 960 CIDOnBoard 0 "CIDNOTOnBoard" 1 "CIDOnBoard" ;
VAL_ 960 RHatchStsForPLG 0 "Closed" 1 "OPEN" ;
VAL_ 960 PLGCommand 0 "OPENCommandNotPresent" 1 "OPENCommand" 2 "OPENCtoUpperEndPosition" 3 "CLOSECommand" ;
VAL_ 961 UserPresence 0 "NotPresent" 1 "NotUsed" 2 "Present" 3 "NotUsed" ;
VAL_ 961 RearCeilingLightsSts 0 "All_Off" 1 "All_On" 2 "Left_On" 3 "Right_On" ;
VAL_ 961 LCC_RearDefrostCommand 0 "OFF" 1 "ON" ;
VAL_ 961 LaunchLeverPos 0 "Not_Pulled" 1 "Pulled" 2 "not_used" 3 "not_used" ;
VAL_ 961 FollowMeHomeEnable_Fbk 0 "INIT" 1 "Not_Enable" 2 "_30_sec" 3 "_60_sec" 4 "_90_sec" 5 "_120_sec" 6 "_150_sec" 7 "_180_sec" 8 "_210_sec" 9 "not_used" 10 "not_used" 11 "not_used" 12 "not_used" 13 "not_used" 14 "not_used" 15 "not_used" ;
VAL_ 961 VehicleSts 0 "Wake_Up" 1 "Comfort" 2 "KeyON" 3 "KeyON_PWTStarting" 4 "KeyON_PWTShutdown" 5 "KeyON_PWTON" 6 "KeyOFF_PWTMoving" ;
VAL_ 961 RearRightWindowSwitch 0 "Active" 1 "Not_Active" ;
VAL_ 961 RearLeftWindowSwitch 0 "Active" 1 "Not_Active" ;
VAL_ 961 Deactivation_DoorOpening_Led 0 "Off" 1 "On" ;
VAL_ 961 LCC_MaxDefrostCommand 0 "OFF" 1 "ON" ;
VAL_ 961 LaunchLeverFailSts 0 "No_Fail" 1 "Fail" ;
VAL_ 961 LowBeam_Button 0 "Not_Active" 1 "Dir_1_Pressed" 2 "Dir_2_Pressed" 3 "Not_Used" ;
VAL_ 961 PlugReleaseReq 0 "Not_Active" 1 "Active" ;
VAL_ 961 RearSeats 0 "Absent" 1 "2 positions" 2 "3 positions" 3 "Not_Used" ;
VAL_ 961 AHBSts 0 "Not_Armed" 1 "Day_Armed_Not_Engaged" 2 "Night_Armed_Not_Engaged" 3 "Armed_Engaged" ;
VAL_ 961 RearFog_Button 0 "Not_Active" 1 "Dir_1_Pressed" 2 "Dir_2_Pressed" 3 "Not_Used" ;
VAL_ 961 MirrorRHFailSts 0 "Fail_Not_Present" 1 "Fail_Present" ;
VAL_ 961 MirrorLHFailSts 0 "Fail_Not_Present" 1 "Fail_Present" ;
VAL_ 961 RearSeatsRightBackrestSts 0 "Unfolded" 1 "Folded" ;
VAL_ 961 RearSeatsLeftBackrestSts 0 "Unfolded" 1 "Folded" ;
VAL_ 963 ElectricSteeringLamp_FailSts 0 "OFF_Fail_not_present" 1 "OFF_Fail_present" 2 "ON_Fail_not_present" 3 "Not_used" ;
VAL_ 963 InternalLightLevel 0 "Level_1" 1 "Level_2" 2 "Level_3" 3 "Level_4" 4 "Level_5" 5 "Level_6" 6 "Level_7" 7 "Level_8" 8 "Level_9" 9 "Level_10" 10 "Level_11" 11 "Level_12" 12 "Level_13" 13 "Level_14" 14 "Level_15" 15 "Level_16" ;
VAL_ 963 InternalLightLevelForDisplay 0 "Level_1" 1 "Level_2" 2 "Level_3" 3 "Level_4" 4 "Level_5" 5 "Level_6" 6 "Level_7" 7 "Level_8" 8 "Level_9" 9 "Level_10" 10 "Level_11" 11 "Level_12" 12 "Level_13" 13 "Level_14" 14 "Level_15" 15 "Level_16" ;
VAL_ 964 AudioModeDownCntrl 0 "Not_Active" 1 "Active" ;
VAL_ 964 AudioModeUpCntrl 0 "Not_Active" 1 "Active" ;
VAL_ 964 VolumeButtonPushSts 0 "Not_Pressed" 1 "Pressed" ;
VAL_ 964 FlashBeamSwitchSts 0 "Not_Active" 1 "Active" ;
VAL_ 964 LdirectionSwitchSts 0 "Not_Active" 1 "Active" ;
VAL_ 964 RdirectionSwitchSts 0 "Not_Active" 1 "Active" ;
VAL_ 964 LChangeLaneSts 0 "Not_Active" 1 "Active" ;
VAL_ 964 RChangeLaneSts 0 "Not_Active" 1 "Active" ;
VAL_ 964 RearWindowWasherSwitchSts 0 "Not_Active" 1 "Active" ;
VAL_ 964 RearWindowWiperSwitchSts 0 "Not_Active" 1 "Active" ;
VAL_ 964 HighBeamSwitchSts 0 "Not_Active" 1 "Active" ;
VAL_ 964 VolumeRotation 0 "Volume_Encoder_NO_rotation" 1 "VolumeEncoderClockwiseRot" 2 "VolumeEncoderCounterClockwiseRot" 3 "Not_used" ;
VAL_ 965 ADAS_OnOffSts 0 "Not_Pressed" 1 "Pressed" ;
VAL_ 965 RimTemperature 255 "Fault_Value" ;
VAL_ 967 NIT_LifterButtonValidData 0 "Valid" 1 "Not_Valid" ;
VAL_ 967 NIT_LifterLongPressRqt 0 "Not_Active" 1 "Active" ;
VAL_ 967 AQS_Conditions 0 "initialization" 1 "city_mode" 2 "highway_mode" 3 "tunnel_mode" 4 "country_mode" 5 "Not_used" 6 "Not_used" 7 "Invalid" ;
VAL_ 967 NIT_LifterShortPressRqt 0 "Not_Active" 1 "Active" ;
VAL_ 967 Alert_RCTA 0 "Off" 1 "On" ;
VAL_ 969 CapoteBuzzerReq 0 "None" 1 "Operation_inhibited_or_standby" 2 "End_of_opening_closing_sequence" 3 "Capote_failure" ;
VAL_ 969 CapoteFailSts 0 "Fail_Not_Present" 1 "FailPresent" 2 "Not_used" 3 "Not_used" ;
VAL_ 969 TrunkReleaseReqCntrl 0 "Not_active" 1 "Active" ;
VAL_ 969 CapoteSts 0 "Closed" 1 "Opened" 2 "Closing" 3 "Opening" 4 "Middle" 5 "Not_used" 6 "Not_used" 7 "Not_used" ;
VAL_ 969 FrontWindowsEnable 0 "Disabled" 1 "Enabled" ;
VAL_ 969 TrunkEnable 0 "Disabled" 1 "Enabled" ;
VAL_ 969 CapoteInfoForDisplay 0 "code_0000_None" 1 "code_0001_see_F045" 2 "code_0010_see_F045" 3 "code_0011_see_F045" 4 "code_0100_see_F045" 5 "code_0101_see_F045" 6 "code_0110_see_F045" 7 "code_0111_see_F045" 8 "code_1000_see_F045" 9 "code_1001_see_F045" 10 "code_1010_see_F045" 11 "code_1011_see_F045" 12 "code_1100_see_F045" 13 "code_1101_see_F045" 14 "code_1110_see_F045" 15 "code_1111_see_F045" 16 "code_10000_see_F045" 17 "code_10001_see_F045" 18 "code_10010_see_F045" 19 "code_10011_see_F045" 20 "code_10100_see_F045" 21 "code_10101_see_F045" 22 "code_10110_see_F045" 23 "code 010111 - see F045" 24 "code 011000 - see F045" 25 "code 011001 - see F045" 26 "code 011010 - see F045" 27 "code 011011 - see F045" 28 "code 011100 - see F045" 29 "code 011101 - see F045" 30 "code 011110 - see F045" 31 "code 011111 - see F045" 32 "code 100000 - see F045" 33 "code 100001 - see F045" 34 "code 100010 - see F045" 35 "code 100011 - see F045" 36 "code 100100 - see F045" 37 "code 100101 - see F045" 38 "code 100110 - see F045" 39 "code 100111 - see F045" 40 "code 101000 - see F045" 41 "code 101001 - see F045" 42 "code 101010 - see F045" 43 "code 101011 - see F045" 44 "code 101100 - see F045" 45 "code 101101 - see F045" 46 "code 101110 - see F045" 47 "code 101111 - see F045" 48 "code 110000 - see F045" 49 "code 110001 - see F045" 50 "code 110010 - see F045" 51 "code 110011 - see F045" 52 "code 110100 - see F045" 53 "code 110101 - see F045" 54 "code 110110 - see F045" 55 "code 110111 - see F045" 56 "code 111000 - see F045" 57 "code 111001 - see F045" 58 "code 111010 - see F045" 59 "code 111011 - see F045" 60 "code 111100 - see F045" 61 "code 111101 - see F045" 62 "code 111110 - see F045" 63 "code 111111 - see F045" ;
VAL_ 969 DriverHRWindowsSts 0 "Completely_Open" 1 "Middle_Position" 2 "No_Command" 3 "Completely_Closed" ;
VAL_ 969 FrontWindowsMovementCmd 0 "No_Command" 1 "UP_to_Short_Drop" 2 "Up_Movement" 3 "Down_Movement" ;
VAL_ 969 CapoteStsForDisplay 0 "None" 1 "see_F045" 2 "see_F045" 3 "see_F045" 4 "see_F045" 5 "see_F045" 6 "see_F045" 7 "see_F045" 8 "see_F045" 9 "see_F045" 10 "see_F045" 11 "see_F045" 12 "see_F045" 13 "see_F045" 14 "see_F045" 15 "see_F045" ;
VAL_ 969 ObstacleDetectionSts 0 "Not_Active" 1 "Active" 2 "Inhibited" 3 "Not_used" ;
VAL_ 969 PowerModeSts 0 "Standard_Power" 1 "Logistic_Mode_ON" 2 "Not_used" 3 "Not_used" ;
VAL_ 969 PsgnrHRWindowInitializedSts 0 "Not_initialized" 1 "Initialized" ;
VAL_ 969 DriverHRWindowInitializedSts 0 "Not_initialized" 1 "Initialized" ;
VAL_ 969 AutomaticDownCntrl 0 "Not_Active" 1 "Active" ;
VAL_ 969 PsgnrHRWindowsSts 0 "Completely_Open" 1 "Middle_Position" 2 "No_Command" 3 "Completely_Closed" ;
VAL_ 969 BackWindowInitializedSts 0 "Not_initialized" 1 "Initialized" ;
VAL_ 969 BackWindowSts 0 "Completely_Open" 1 "Middle_position" 2 "No_Command" 3 "Completely_Closed" ;
VAL_ 969 NCPAutoStopFailSts 0 "Fail_Not_Present" 1 "Fail_Present" ;
VAL_ 969 NCPAutoStopEnableSts 0 "Disable" 1 "Enable" ;
VAL_ 969 NCPAutoStopStaySts 0 "RecrankEngine" 1 "RemainStop" ;
VAL_ 969 PowerStrikerUpEnable 0 "Disabled" 1 "Enabled" ;
VAL_ 969 TonneauCoverSts 0 "TC_Closed" 1 "TC_Opened" 2 "TC_Intermediate" 3 "TC_Moving" ;
VAL_ 970 NPS_FrontSensorButtonSts 0 "Not_Pressed" 1 "Pressed" ;
VAL_ 971 STS_LH_OsHandle_Lock_Active 0 "Not_Active" 1 "Active" ;
VAL_ 971 STS_LH_OsHandle_Active 0 "Not_Active" 1 "Active" ;
VAL_ 971 STS_LH_CinchStatus 0 "Not_Enabled" 1 "Enabled" ;
VAL_ 971 STS_LH_DoorStatus 0 "SNA" 1 "Closed" 2 "Ajar" 3 "Opened" ;
VAL_ 971 STS_LH_FailSts 0 "Not_Active" 1 "Active" ;
VAL_ 971 STS_LH_Latch 0 "Init" 1 "Unlocked" 2 "Locked" 3 "SNA" ;
VAL_ 971 STS_LH_DB_HomeSensor 0 "DB_FALSE" 1 "DB_TRUE" ;
VAL_ 971 STS_LH_DB_ClockFail 0 "DB_FALSE" 1 "DB_TRUE" ;
VAL_ 971 ELLCrashSts 0 "Not_Active" 1 "Active" ;
VAL_ 971 STS_LH_HandleSpeedFailSts 0 "Fail_Not_Present" 1 "Fail_Present" ;
VAL_ 971 STS_LH_ShortDropMode 0 "Not_Enabled" 1 "Enabled" ;
VAL_ 971 STS_LH_PowerModeSts 0 "Standard_Power" 1 "Logistic_Mode_On" 2 "Not_Used" 3 "Not_Used" ;
VAL_ 971 STS_LH_IsHandle_Active 0 "Not_Active" 1 "Active" ;
VAL_ 971 STS_LH_DB_CinchStatus 0 "DB_FALSE" 1 "DB_TRUE" ;
VAL_ 971 STS_LH_DB_GStatusTEFault 0 "DB_FALSE" 1 "DB_TRUE" ;
VAL_ 971 STS_LH_DB_ADC_DataReliable 0 "DB_FALSE" 1 "DB_TRUE" ;
VAL_ 972 STS_RH_OsHandle_Lock_Active 0 "Not_Active" 1 "Active" ;
VAL_ 972 STS_RH_OsHandle_Active 0 "Not_Active" 1 "Active" ;
VAL_ 972 STS_RH_CinchStatus 0 "Not_Enabled" 1 "Enabled" ;
VAL_ 972 STS_RH_DoorStatus 0 "SNA" 1 "Closed" 2 "Ajar" 3 "Opened" ;
VAL_ 972 STS_RH_FailSts 0 "Not_Active" 1 "Active" ;
VAL_ 972 STS_RH_Latch 0 "Init" 1 "Unlocked" 2 "Locked" 3 "SNA" ;
VAL_ 972 STS_RH_DB_HomeSensor 0 "DB_FALSE" 1 "DB_TRUE" ;
VAL_ 972 STS_RH_DB_ClockFail 0 "DB_FALSE" 1 "DB_TRUE" ;
VAL_ 972 ELRCrashSts 0 "Not_Active" 1 "Active" ;
VAL_ 972 STS_RH_HandleSpeedFailSts 0 "Fail_Not_Present" 1 "Fail_Present" ;
VAL_ 972 STS_RH_ShortDropMode 0 "Not_Enabled" 1 "Enabled" ;
VAL_ 972 STS_RH_PowerModeSts 0 "Standard_Power" 1 "Logistic_Mode_On" 2 "Not_Used" 3 "Not_Used" ;
VAL_ 972 STS_RH_IsHandle_Active 0 "Not_Active" 1 "Active" ;
VAL_ 972 STS_RH_DB_CinchStatus 0 "DB_FALSE" 1 "DB_TRUE" ;
VAL_ 972 STS_RH_DB_GStatusTEFault 0 "DB_FALSE" 1 "DB_TRUE" ;
VAL_ 972 STS_RH_DB_ADC_DataReliable 0 "DB_FALSE" 1 "DB_TRUE" ;
VAL_ 973 STS_LV_OsHandle_Lock_Active 0 "Not_Active" 1 "Active" ;
VAL_ 973 STS_LV_OsHandle_Active 0 "Not_Active" 1 "Active" ;
VAL_ 973 STS_LV_CinchStatus 0 "Not_Enabled" 1 "Enabled" ;
VAL_ 973 STS_LV_DoorStatus 0 "SNA" 1 "Closed" 2 "Ajar" 3 "Opened" ;
VAL_ 973 STS_LV_FailSts 0 "Not_Active" 1 "Active" ;
VAL_ 973 STS_LV_Latch 0 "Init" 1 "Unlocked" 2 "Locked" 3 "SNA" ;
VAL_ 973 STS_LV_PowerDoorSts 0 "SNA" 1 "Closed" 2 "Ajar" 3 "Opened" 4 "Manual_Opening" 5 "Automatic_Opening" 6 "Manual_Closing" 7 "Automatic_Closing" 8 "OpenEndPosition" 9 "Antipinch_Executed" 10 "OpenWarning" 11 "Presented" 12 "Not_Used" 13 "Not_Used" 14 "Not_Used" 15 "Not_Used" ;
VAL_ 973 STS_LV_ShortDropMode 0 "Not_Enabled" 1 "Enabled" ;
VAL_ 973 STS_LV_IsHandle_Active 0 "Not_Active" 1 "Active" ;
VAL_ 973 STS_LV_PowerDoorPosValidData 0 "Valid" 1 "Not_Valid" ;
VAL_ 973 ERLCrashSts 0 "Not_Active" 1 "Active" ;
VAL_ 973 STS_LV_HandleSpeedFailSts 0 "Fail_Not_Present" 1 "Fail_Present" ;
VAL_ 973 STS_LV_PDFailSts 0 "Not_Active" 1 "Active" ;
VAL_ 973 STS_LV_ChildLockFailSts 0 "Not_Active" 1 "Active" ;
VAL_ 973 STS_LV_DoorAlert 0 "No_chime" 1 "Single_chime" 2 "Double_chime" 3 "Not_Used" ;
VAL_ 973 STS_LV_ChildLock_Feedback 0 "Not_Enabled" 1 "Enabled" ;
VAL_ 973 STS_LV_ISwitch_Active 0 "Not_Active" 1 "Active" ;
VAL_ 973 STS_LV_DB_ADC_DataReliable 0 "DB_FALSE" 1 "DB_TRUE" ;
VAL_ 973 STS_LV_DB_AccFailSts_FrozenData 0 "DB_FALSE" 1 "DB_TRUE" ;
VAL_ 973 STS_LV_DB_ChildLockMemFail 0 "DB_FALSE" 1 "DB_TRUE" ;
VAL_ 973 STS_LV_DB_AccFailSts_WrongMode 0 "DB_FALSE" 1 "DB_TRUE" ;
VAL_ 973 STS_LV_DB_HomeSensor 0 "DB_FALSE" 1 "DB_TRUE" ;
VAL_ 973 STS_LV_DB_AccFailSts_NoAnswer 0 "DB_FALSE" 1 "DB_TRUE" ;
VAL_ 973 STS_LV_DB_ClockFail 0 "DB_FALSE" 1 "DB_TRUE" ;
VAL_ 973 LReleaseReq 0 "Not_Active" 1 "Active" ;
VAL_ 973 STS_LV_DB_AccFailSts_StProcFail 0 "DB_FALSE" 1 "DB_TRUE" ;
VAL_ 973 STS_LV_DB_FbDriveMode 0 "PDU_FEEDBACK_OFF" 1 "PDU_FEEDBACK_ACC" 2 "PDU_FEEDBACK_CONST" 3 "PDU_FEEDBACK_DEC" 4 "PDU_FEEDBACK_BLOCK" 5 "Not_Used" 6 "Not_Used" 7 "Not_Used" ;
VAL_ 973 STS_LV_DB_DoorEngaged 0 "DB_FALSE" 1 "DB_TRUE" ;
VAL_ 973 STS_LV_DB_OSSwitchClose 0 "DB_FALSE" 1 "DB_TRUE" ;
VAL_ 973 STS_LV_DB_CinchStatus 0 "DB_FALSE" 1 "DB_TRUE" ;
VAL_ 973 STS_LV_DB_GStatusTEFault 0 "DB_FALSE" 1 "DB_TRUE" ;
VAL_ 973 STS_LV_DB_PDUIssue 0 "PDU_OK" 1 "PDU_ACC_ISSUE" 2 "PDU_GDU_DISABLE_HW" 3 "PDU_POWER_ON_OPEN_DOOR" 4 "PDU_HALL_POS_ISSUE" 5 "PDU_CURRENT_SENSE_ISSUE" 6 "PDU_DTC_MOTOR_FAULT" 7 "PDU_HALL_SENSOR_HS_OFF" ;
VAL_ 973 STS_LV_DB_PDUActive 0 "DB_FALSE" 1 "DB_TRUE" ;
VAL_ 974 STS_RV_OsHandle_Lock_Active 0 "Not_Active" 1 "Active" ;
VAL_ 974 STS_RV_OsHandle_Active 0 "Not_Active" 1 "Active" ;
VAL_ 974 STS_RV_CinchStatus 0 "Not_Enabled" 1 "Enabled" ;
VAL_ 974 STS_RV_DoorStatus 0 "SNA" 1 "Closed" 2 "Ajar" 3 "Opened" ;
VAL_ 974 STS_RV_FailSts 0 "Not_Active" 1 "Active" ;
VAL_ 974 STS_RV_Latch 0 "Init" 1 "Unlocked" 2 "Locked" 3 "SNA" ;
VAL_ 974 STS_RV_PowerDoorSts 0 "SNA" 1 "Closed" 2 "Ajar" 3 "Opened" 4 "Manual_Opening" 5 "Automatic_Opening" 6 "Manual_Closing" 7 "Automatic_Closing" 8 "OpenEndPosition" 9 "Antipinch_Executed" 10 "OpenWarning" 11 "Presented" 12 "Not_Used" 13 "Not_Used" 14 "Not_Used" 15 "Not_Used" ;
VAL_ 974 STS_RV_ShortDropMode 0 "Not_Enabled" 1 "Enabled" ;
VAL_ 974 STS_RV_IsHandle_Active 0 "Not_Active" 1 "Active" ;
VAL_ 974 STS_RV_PowerDoorPosValidData 0 "Valid" 1 "Not_Valid" ;
VAL_ 974 ERRCrashSts 0 "Not_Active" 1 "Active" ;
VAL_ 974 STS_RV_HandleSpeedFailSts 0 "Fail_Not_Present" 1 "Fail_Present" ;
VAL_ 974 STS_RV_PDFailSts 0 "Not_Active" 1 "Active" ;
VAL_ 974 STS_RV_ChildLockFailSts 0 "Not_Active" 1 "Active" ;
VAL_ 974 STS_RV_DoorAlert 0 "No_chime" 1 "Single_chime" 2 "Double_chime" 3 "Not_Used" ;
VAL_ 974 STS_RV_ChildLock_Feedback 0 "Not_Enabled" 1 "Enabled" ;
VAL_ 974 STS_RV_ISwitch_Active 0 "Not_Active" 1 "Active" ;
VAL_ 974 STS_RV_DB_ADC_DataReliable 0 "DB_FALSE" 1 "DB_TRUE" ;
VAL_ 974 STS_RV_DB_AccFailSts_FrozenData 0 "DB_FALSE" 1 "DB_TRUE" ;
VAL_ 974 STS_RV_DB_ChildLockMemFail 0 "DB_FALSE" 1 "DB_TRUE" ;
VAL_ 974 STS_RV_DB_AccFailSts_WrongMode 0 "DB_FALSE" 1 "DB_TRUE" ;
VAL_ 974 STS_RV_DB_HomeSensor 0 "DB_FALSE" 1 "DB_TRUE" ;
VAL_ 974 STS_RV_DB_AccFailSts_NoAnswer 0 "DB_FALSE" 1 "DB_TRUE" ;
VAL_ 974 STS_RV_DB_ClockFail 0 "DB_FALSE" 1 "DB_TRUE" ;
VAL_ 974 RReleaseReq 0 "Not_Active" 1 "Active" ;
VAL_ 974 STS_RV_DB_AccFailSts_StProcFail 0 "DB_FALSE" 1 "DB_TRUE" ;
VAL_ 974 STS_RV_DB_FbDriveMode 0 "PDU_FEEDBACK_OFF" 1 "PDU_FEEDBACK_ACC" 2 "PDU_FEEDBACK_CONST" 3 "PDU_FEEDBACK_DEC" 4 "PDU_FEEDBACK_BLOCK" 5 "Not_Used" 6 "Not_Used" 7 "Not_Used" ;
VAL_ 974 STS_RV_DB_DoorEngaged 0 "DB_FALSE" 1 "DB_TRUE" ;
VAL_ 974 STS_RV_DB_OSSwitchClose 0 "DB_FALSE" 1 "DB_TRUE" ;
VAL_ 974 STS_RV_DB_CinchStatus 0 "DB_FALSE" 1 "DB_TRUE" ;
VAL_ 974 STS_RV_DB_GStatusTEFault 0 "DB_FALSE" 1 "DB_TRUE" ;
VAL_ 974 STS_RV_DB_PDUIssue 0 "PDU_OK" 1 "PDU_ACC_ISSUE" 2 "PDU_GDU_DISABLE_HW" 3 "PDU_POWER_ON_OPEN_DOOR" 4 "PDU_HALL_POS_ISSUE" 5 "PDU_CURRENT_SENSE_ISSUE" 6 "PDU_DTC_MOTOR_FAULT" 7 "PDU_HALL_SENSOR_HS_OFF" ;
VAL_ 974 STS_RV_DB_PDUActive 0 "DB_FALSE" 1 "DB_TRUE" ;
VAL_ 975 STS_LH_ShortDropFeedback 0 "Not_Active" 1 "Active" ;
VAL_ 975 RChildlockCommandDoorSts 0 "Not_Active" 1 "Active" ;
VAL_ 975 LChildlockCommandDoorSts 0 "Not_Active" 1 "Active" ;
VAL_ 975 NBC_RV_Unlock 0 "Not_Active" 1 "Active" ;
VAL_ 975 NBC_LV_Unlock 0 "Not_Active" 1 "Active" ;
VAL_ 975 NBC_RH_Unlock 0 "Not_Active" 1 "Active" ;
VAL_ 975 NBC_LH_Unlock 0 "Not_Active" 1 "Active" ;
VAL_ 975 NBC_Lock 0 "Not_Active" 1 "Active" ;
VAL_ 975 STS_RV_ShortDropFeedback 0 "Not_Active" 1 "Active" ;
VAL_ 975 STS_LV_ShortDropFeedback 0 "Not_Active" 1 "Active" ;
VAL_ 975 STS_RH_ShortDropFeedback 0 "Not_Active" 1 "Active" ;
VAL_ 977 PsngrAntiPinchFailSts 0 "Fail_Not_Present" 1 "Fail_Present" ;
VAL_ 977 WLMPsngrFailSts 0 "Fail_Not_Present" 1 "Fail_Present" ;
VAL_ 977 PsgnrCmdCompleteCntrl 0 "Not_active" 1 "Active" ;
VAL_ 977 PsgnrHRWindowsUpSts 0 "Not_active" 1 "Active" ;
VAL_ 977 PsgnrHRWindowsDownSts 0 "Not_active" 1 "Active" ;
VAL_ 977 PsngrWindowSts 0 "Open" 1 "Close" 2 "Middle" 3 "Running_Up" 4 "Running_Down" 5 "Reverse" 6 "Short_drop" 7 "SNA" ;
VAL_ 977 E_LatchPsngrFailSts 0 "Fail_Not_Present" 1 "Fail_Present" ;
VAL_ 978 EasyEntryFbk 0 "Init" 1 "Off" 2 "SteeringWheel" 3 "SteeringWheel_Seat" ;
VAL_ 978 NAGSeatAngleBackRest 0 "Wait" 1 "OK" 2 "Fail" 3 "Antipanic" ;
VAL_ 978 Steering_Adj_Selection_Fbk_Led 0 "OFF" 1 "ON" ;
VAL_ 978 DriverUserAction 0 "Not_Active" 1 "Active" ;
VAL_ 978 NAGSeatTiltingPosition 0 "Wait" 1 "OK" 2 "Fail" 3 "Antipanic" ;
VAL_ 978 NAGSeatSlidingPosition 0 "Wait" 1 "OK" 2 "Fail" 3 "Antipanic" ;
VAL_ 983 NAPSeatAngleBackRest 0 "Wait" 1 "OK" 2 "Fail" 3 "Antipanic" ;
VAL_ 983 PassengerUserAction 0 "Not_Active" 1 "Active" ;
VAL_ 983 NAPSeatSlidingPosition 0 "Wait" 1 "OK" 2 "Fail" 3 "Antipanic" ;
VAL_ 983 NAPSeatTiltingPosition 0 "Wait" 1 "OK" 2 "Fail" 3 "Antipanic" ;
VAL_ 992 SoSe_SunInt_2D_Le 241 "not_used" 242 "not_used" 243 "not_used" 244 "not_used" 245 "not_used" 246 "not_used" 247 "not_used" 248 "not_used" 249 "not_used" 250 "not_used" 251 "not_used" 252 "initial_value" 253 "Value_exceeds_limit" 254 "SolarLeftDiodeFailure" 255 "Not_used" ;
VAL_ 992 RsErr_HumSense 0 "Fail_Not_Present" 1 "Fail_Present" ;
VAL_ 992 Ext_Sensor_Brightness_Valid_Data 0 "Valid" 1 "Not_Valid" ;
VAL_ 992 LinFailure 0 "Fail_Not_Present" 1 "Fail_Present" ;
VAL_ 992 SoSe_SunInt_2D_Ri 241 "not_used" 242 "not_used" 243 "not_used" 244 "not_used" 245 "not_used" 246 "not_used" 247 "not_used" 248 "not_used" 249 "not_used" 250 "not_used" 251 "not_used" 252 "initial_value" 253 "Value_exceeds_limit" 254 "SolarRightDiodeFailure" 255 "Not_used" ;
VAL_ 992 GLASS_TEMP 251 "Not_used" 252 "Not_ready" 253 "Value_exceeds_limits" 254 "Error" 255 "SNA" ;
VAL_ 992 DewpointTemp 251 "Not_used" 252 "Not_ready" 253 "Value_exceeds_limits" 254 "Error" 255 "SNA" ;
VAL_ 992 REL_HUMIDITY 201 "Not_used" 202 "Not_used" 203 "Not_used" 204 "Not_used" 205 "Not_used" 206 "Not_used" 207 "Not_used" 208 "Not_used" 209 "Not_used" 210 "Not_used" 211 "Not_used" 212 "Not_used" 213 "Not_used" 214 "Not_used" 215 "Not_used" 216 "Not_used" 217 "Not_used" 218 "Not_used" 219 "Not_used" 220 "Not_used" 221 "Not_used" 222 "Not_used" 223 "Not_used" 224 "Not_used" 225 "Not_used" 226 "Not_used" 227 "Not_used" 228 "Not_used" 229 "Not_used" 230 "Not_used" 231 "Not_used" 232 "Not_used" 233 "Not_used" 234 "Not_used" 235 "Not_used" 236 "Not_used" 237 "Not_used" 238 "Not_used" 239 "Not_used" 240 "Not_used" 241 "Not_used" 242 "Not_used" 243 "Not_used" 244 "Not_used" 245 "Not_used" 246 "Not_used" 247 "Not_used" 248 "Not_used" 249 "Not_used" 250 "Not_used" 251 "Not_used" 252 "Not_ready" 253 "Value_exceeds_limits" 254 "Error" 255 "SNA" ;
VAL_ 992 External_Sensor_Brightness_Level 65532 "Init" 65533 "Value_exceeds_limit" 65534 "Error" ;
VAL_ 1024 LongAcceleration 4095 "Invalid_value" ;
VAL_ 1024 AXSStat 0 "Signal_in_specification_limits" 1 "Temporary_signal_error" 2 "Permanent_signal_error" 3 "Sensor_element_in_initialization" ;
VAL_ 1024 LatAcceleration 4095 "Invalid_value" ;
VAL_ 1024 AYSStat 0 "Signal_in_specification_limits" 1 "Temporary_signal_error" 2 "Permanent_signal_error" 3 "Sensor_element_in_initialization" ;
VAL_ 1024 YawRate 4095 "Invalid_value" ;
VAL_ 1024 YRSStat 0 "Signal_in_specification_limits" 1 "Temporary_signal_error" 2 "Permanent_signal_error" 3 "Sensor_element_in_initialization" ;
VAL_ 1034 DisplayUserAction 0 "No_Action" 1 "Action" ;
VAL_ 1034 PowerModeSts 0 "Standard_Power" 1 "Logistic_Mode_ON" 2 "Not_used" 3 "Not_used" ;
VAL_ 1034 RightChildLockButton 0 "Not_Pressed" 1 "Pressed" ;
VAL_ 1034 LeftChildLockButton 0 "Not_Pressed" 1 "Pressed" ;
VAL_ 1034 Carwash_Rqt 0 "No_Req" 1 "Req" ;
VAL_ 1035 CeremonySts_IDC 0 "Not_Active" 1 "Active" 2 "Completed" 3 "Not_Used" ;
VAL_ 1035 ETA_to_Dest 2047 "SNA" ;
VAL_ 1035 Ecall_IDCMuteReq 0 "Not_Active" 1 "Active" ;
VAL_ 1035 ETA_to_EVSE 2047 "SNA" ;
VAL_ 1035 HMISts 0 "HMI_OFF" 1 "HMI_ON" 2 "HMI_PowerOn" ;
VAL_ 1035 CabinModeSts 0 "Not_Enabled" 1 "Enabled" ;
VAL_ 1035 IDC_CommandSts 0 "No_Action" 1 "PowerOn_Action" 2 "PowerOff_Action" 3 "not_used" ;
VAL_ 1035 IDC_VisualizationSts 0 "No_Visualization" 1 "Insert_Key" 2 "Key_Not_Found" 3 "not_used" ;
VAL_ 1214 LVB_SOCSts 0 "OK" 1 "FLT" ;
VAL_ 1214 LVB_SOC 127 "SNA" ;
VAL_ 1214 LVB_MaxCellsTemp 255 "SNA" ;
VAL_ 1214 LVB_SOH 127 "SNA" ;
VAL_ 1214 LVB_MaxCellsTempFailsts 0 "Fail_not_Present" 1 "Fail_Present" ;
VAL_ 1214 RecirculationReq 0 "No_Req" 1 "Req" ;
VAL_ 1214 LVB_Relay_Status 0 "CLS" 1 "OPN_REQ" 2 "OPN" 3 "SNA" ;
VAL_ 1313 STS_DRS_DriverLatchsts 0 "init" 1 "Unlocked" 2 "Locked" 3 "SNA" ;
VAL_ 1313 STS_DRS_PsngrDoorSts 0 "SNA" 1 "close" 2 "Ajar" 3 "Open" ;
VAL_ 1313 STS_DRS_DriverDoorSts 0 "SNA" 1 "close" 2 "Ajar" 3 "Open" ;
VAL_ 1313 STS_DRS_VPSTrunkSts 0 "Closed_Unlocked" 1 "Closed_Locked" 2 "Open_Unlocked" 3 "Open_Locked" ;
VAL_ 1313 STS_DRS_RearRightLatchsts 0 "init" 1 "Unlocked" 2 "Locked" 3 "SNA" ;
VAL_ 1313 STS_DRS_RearLeftDoorSts 0 "SNA" 1 "close" 2 "Ajar" 3 "Open" ;
VAL_ 1313 STS_DRS_RearRightDoorSts 0 "SNA" 1 "close" 2 "Ajar" 3 "Open" ;
VAL_ 1313 STS_DRS_PsngrLatchsts 0 "init" 1 "Unlocked" 2 "Locked" 3 "SNA" ;
VAL_ 1313 STS_DRS_PsngrWindowSts 0 "Open" 1 "Close" 2 "Middle" 3 "Running_Up" 4 "Running_Down" 5 "Reverse" 6 "Short_drop" 7 "SNA" ;
VAL_ 1313 STS_DRS_DriverWindowSts 0 "Open" 1 "Close" 2 "Middle" 3 "Running_Up" 4 "Running_Down" 5 "Reverse" 6 "Short_drop" 7 "SNA" ;
VAL_ 1313 STS_DRS_VPSLockValidData 0 "Valid" 1 "Not_Valid" ;
VAL_ 1313 STS_DRS_RearLeftLatchsts 0 "init" 1 "Unlocked" 2 "Locked" 3 "SNA" ;
VAL_ 1313 TrunkInternalButton 0 "Not_Active" 1 "Active" ;
VAL_ 1313 STS_DRS_RearRightWindowSts 0 "Open" 1 "Close" 2 "Middle" 3 "Running_Up" 4 "Running_Down" 5 "Reverse" 6 "Short_drop" 7 "SNA" ;
VAL_ 1313 STS_DRS_RearLeftWindowSts 0 "Open" 1 "Close" 2 "Middle" 3 "Running_Up" 4 "Running_Down" 5 "Reverse" 6 "Short_drop" 7 "SNA" ;
VAL_ 1313 Interior_Lock 0 "Not_Active" 1 "Active" ;
VAL_ 1313 VPSDoorSts 0 "Locked_External" 1 "Locked_Internal" 2 "Unlocked_External" 3 "Unlocked_Internal" ;
VAL_ 1313 LockUnlockDoors_Button 0 "Not_Pressed" 1 "Pressed" ;
VAL_ 1313 TrunkExternalButton 0 "Not_Active" 1 "Active" ;
VAL_ 1318 HazardActRqt 0 "Hazard_Off" 1 "Hazard_On" ;
VAL_ 1318 StopLightActRqt 0 "Stop_Light_switched_OFF" 1 "Stop_Light_switched_ON" ;
VAL_ 1318 BrakePedalSts 0 "Not_Pressed" 1 "Pressed" ;
VAL_ 1318 BrakePedalValidData 0 "Valid_QM" 1 "Not_valid" 2 "Valid_ASIL" 3 "Not_used" ;
VAL_ 1318 BrakePressureActualValidData 0 "Valid_QM" 1 "Not_valid" 2 "Valid_ASIL" 3 "Not_used" ;
VAL_ 1318 DriverBrkPressureRqtValidData 0 "Valid_QM" 1 "Not_valid" 2 "Valid_ASIL" 3 "Not_used" ;
VAL_ 1318 BrakePressureTargetValidData 0 "Valid_QM" 1 "Not_valid" 2 "Valid_ASIL" 3 "Not_used" ;
VAL_ 1318 BrakeRodStrokeValidData 0 "Valid_QM" 1 "Not_valid" 2 "Valid_ASIL" 3 "Not_used" ;
VAL_ 1351 HALF_CHIME_TYPESts 0 "None" 1 "Audio_01" 2 "Audio_02" 3 "Audio_03" 4 "Audio_04" 5 "Audio_05" 6 "Half_Chime" 7 "not_used" 8 "not_used" 9 "not_used" 10 "not_used" 11 "not_used" 12 "not_used" 13 "not_used" 14 "not_used" 15 "SNA" ;
VAL_ 1351 TSR_Fault 0 "OFF" 1 "ON" ;
VAL_ 1351 TSR_ON 0 "OFF" 1 "ON" ;
VAL_ 1351 LDWSystemSts 0 "OFF" 1 "ON" 2 "Init" 3 "Not_used" ;
VAL_ 1351 StatusLKA 0 "OFF" 1 "LKA_ON" 2 "LDW_ON" 3 "Init" ;
VAL_ 1351 LDWSensitivitySts 0 "Early" 1 "Med" 2 "Late" 3 "Init" ;
VAL_ 1351 HALF_RF_CHIME_RQSts 0 "False" 1 "True" ;
VAL_ 1351 HALF_LF_CHIME_RQSts 0 "False" 1 "True" ;
VAL_ 1351 TSA_ON 0 "Init" 1 "OFF" 2 "Visual" 3 "Visual_Acoustic" ;
VAL_ 1351 HandsOnSts 0 "OFF" 1 "Yellow" 2 "Red" 3 "Green" 4 "NO_HANDS_ON_STR_WHEEL_YELLOW" 5 "NO_HANDS_ON_STR_WHEEL_RED" 6 "NoDisplay" 7 "Not_Valid" ;
VAL_ 1351 StatusDDA 0 "Init" 1 "Enable" 2 "Not_Enable" 3 "not_used" ;
VAL_ 1351 ADAS_Unavailable_Camera 0 "No_Code" 1 "Camera_Blinded_ADAS_unavailable" 2 "Camera_Fail_ADAS_unavailable" 3 "SNA" ;
VAL_ 1351 TSAMainSign2Fbk 0 "Init" 1 "OFF" 2 "ON" 3 "Not_used" ;
VAL_ 1351 TSASignChangeFbk 0 "Init" 1 "OFF" 2 "ON" 3 "Not_used" ;
VAL_ 1351 DDAW_Level 0 "None" 1 "Level_1" 2 "Level_2" 3 "Level_3" 4 "Level_4" 5 "Level_5" 6 "Level_6" 7 "Level_7" 8 "Level_8" 9 "Level_9" 10 "Level_10" 11 "Not_used" 12 "Not_used" 13 "Not_used" 14 "Not_used" 15 "Not_used" ;
VAL_ 1351 DrowsinessSts 0 "LAMP_ON" 1 "LAMP_OFF" 2 "Failure" 3 "Not_Available" ;
VAL_ 1351 LDWWarningType_fbk 0 "Acoustic" 1 "Vibration" 2 "Acoustic_Vibration" 3 "Init" ;
VAL_ 1351 DisplaySts 0 "LaneSense_OFF" 1 "LaneSense_ON_HF_NotA" 2 "SingleLine_Left" 3 "SingleLine_Right" 4 "ON_HF_NotA_NHTSA_on_Left" 5 "ON_HF_NotA_NHTSA_on_Right" 6 "ON_HF_Armed" 7 "ON_HF_Left_SingleLine_Left" 8 "ON_HF_Left_Side" 9 "ON_HF_Right_SingleLine_Right" 10 "ON_HF_Right_Side" 11 "ON_HF_Left_NHTSA_Left" 12 "ON_HF_Right_NHTSA_Right" 13 "ON" 14 "ON_HF_LKA_on_Left" 15 "ON_HF_LKA_on_Right" 16 "Not_used" 17 "LKA_UNAVAILABLE" 18 "Not_used" 19 "Not_used" 20 "Not_used" 21 "Not_used" 22 "Not_used" 23 "Not_used" 24 "Not_used" 25 "Not_used" 26 "Not_used" 27 "Not_used" 28 "Not_used" 29 "Not_used" 30 "Not_used" 31 "Not_used" 32 "Not_used" 33 "Not_used" 34 "Not_used" 35 "Not_used" 36 "Not_used" 37 "Not_used" 38 "Not_used" 39 "Not_used" 40 "Not_used" 41 "Not_used" 42 "Not_used" 43 "Not_used" 44 "Not_used" 45 "Not_used" 46 "Not_used" 47 "Not_used" 48 "Not_used" 49 "Not_used" 50 "Not_used" 51 "Not_used" 52 "Not_used" 53 "Not_used" 54 "Not_used" 55 "Not_used" 56 "Not_used" 57 "Not_used" 58 "Not_used" 59 "Not_used" 60 "Not_used" 97 "ON_HF_NotA_NoHands" 98 "SingleLine_Left_marker_NoHands" 99 "SingleLine_Right_marker_NoHands" 100 "ON_HF_NotA_NHTSA_on_Left_NoHand" 101 "ON_HF_NotA_NHTSA_on_Right_NoHand" 102 "ON_HF_Armed_NoHands" 103 "ON_HF_Left_SingleLineLeft_NoHand" 104 "ON_HF_Left_NoHands" 105 "ON_HF_Right_SingleLine_R_NoHand" 106 "ON_HF_Right_NoHands" 107 "ON_HF_Left_NHTSA_on_Left_NoHand" 108 "ON_HF_Right_NHTSA_on_R_NoHand" 109 "Not_used" 110 "Not_used" 111 "Not_used" 112 "Not_used" 113 "Not_used" 114 "Not_used" 115 "Not_used" 116 "Not_used" 117 "Not_used" 118 "Not_used" 119 "Not_used" 120 "Not_used" 121 "Not_used" 122 "Not_used" 123 "Not_used" 124 "Not_used" 125 "Not_used" 126 "Not_used" 127 "Not_used" 128 "Not_used" 129 "Not_used" 130 "Not_used" 131 "Not_used" 132 "Not_used" 133 "Not_used" 134 "Not_used" 135 "Not_used" 136 "Not_used" 137 "Not_used" 138 "Not_used" 139 "Not_used" 140 "Not_used" 141 "Not_used" 142 "Not_used" 143 "Not_used" 144 "Not_used" 145 "Not_used" 146 "Not_used" 147 "Not_used" 148 "Not_used" 149 "Not_used" 150 "Not_used" 151 "Not_used" 152 "Not_used" 153 "Not_used" 154 "Not_used" 155 "Not_used" 156 "Not_used" 157 "Not_used" 158 "Not_used" 159 "Not_used" 160 "Sensor_Blinded" 161 "LaneSense_Temp_Unavailable" 162 "Blinded_LaneSense_AHBC_ON" 163 "Not_used" 164 "Not_used" 165 "Not_used" 166 "Not_used" 167 "Not_used" 168 "Not_used" 169 "Not_used" 170 "Not_used" 171 "Not_used" 172 "Not_used" 173 "Not_used" 174 "Not_used" 175 "Not_used" 176 "Not_used" 177 "Not_used" 178 "Not_used" 179 "Not_used" 180 "Not_used" 181 "Not_used" 182 "Not_used" 183 "Not_used" 184 "Not_used" 185 "Not_used" 186 "Not_used" 187 "Not_used" 188 "Not_used" 189 "Not_used" 190 "Not_used" 191 "Not_used" 192 "Not_used" 193 "Not_used" 194 "Not_used" 195 "Not_used" 196 "Not_used" 197 "Not_used" 198 "Not_used" 199 "Not_used" 200 "Not_used" 201 "Not_used" 202 "Not_used" 203 "Not_used" 204 "Not_used" 205 "Not_used" 206 "Not_used" 207 "Not_used" 208 "Not_used" 209 "Not_used" 210 "Not_used" 211 "Not_used" 212 "Not_used" 213 "Not_used" 214 "Not_used" 215 "Not_used" 216 "Not_used" 217 "Not_used" 218 "Not_used" 219 "Not_used" 220 "Not_used" 221 "Not_used" 222 "Not_used" 223 "Not_used" 224 "Not_used" 225 "Not_used" 226 "Not_used" 227 "Not_used" 228 "Not_used" 229 "Not_used" 230 "Not_used" 231 "Not_used" 232 "Not_used" 233 "Not_used" 234 "Not_used" 235 "Not_used" 236 "Not_used" 237 "Not_used" 238 "Not_used" 239 "Not_used" 240 "LaneSense_Fault" 241 "Not_used" 242 "Not_used" 243 "Not_used" 244 "Not_used" 245 "Not_used" 246 "Not_used" 247 "Not_used" 248 "Not_used" 249 "Not_used" 250 "Not_used" 251 "Not_used" 252 "Not_used" 253 "Not_used" 254 "Not_used" 255 "SNA" ;
VAL_ 1351 SensorBlinded 0 "OFF" 1 "ON" ;
VAL_ 1351 AHBFault 0 "OFF" 1 "ON" ;
VAL_ 1351 AHB_ON 0 "OFF" 1 "ON" ;
VAL_ 1351 TSR_Sts 0 "init" 1 "Operative" ;
VAL_ 1351 HALF_heaterSts 0 "Inactive" 1 "Active" ;
VAL_ 1351 DDAW_Index 511 "SNA" ;
VAL_ 1366 RSRRearSeatWarning 0 "Off" 1 "Stop_LongPressButton" 2 "Stop_Antipinch" 3 "Not_used" ;
VAL_ 1366 RSRInterferenceLogic 0 "Off" 1 "On" ;
VAL_ 1366 RSRUserAction 0 "Not_Active" 1 "Active" ;
VAL_ 1366 RSRSeatWarning 0 "Off" 1 "Stop_LongPressButton" 2 "Stop_Antipinch" 3 "Not_used" ;
VAL_ 1366 RSRCapsizingDown 0 "Off" 1 "On" ;
VAL_ 1366 RSRCapsizingUp 0 "Off" 1 "On" ;
VAL_ 1366 RSRSts 0 "Normal_Operation" 1 "Antipanic" 2 "Fail_Present" 3 "Not_used" ;
VAL_ 1367 RSLRearSeatWarning 0 "Off" 1 "Stop_LongPressButton" 2 "Stop_Antipinch" 3 "Not_used" ;
VAL_ 1367 RSLInterferenceLogic 0 "Off" 1 "ON" ;
VAL_ 1367 RSLUserAction 0 "Not_Active" 1 "Active" ;
VAL_ 1367 RSLSeatWarning 0 "Off" 1 "Stop_LongPressButton" 2 "Stop_Antipinch" 3 "Not_used" ;
VAL_ 1367 RSLCapsizingDown 0 "Off" 1 "On" ;
VAL_ 1367 RSLCapsizingUp 0 "Off" 1 "On" ;
VAL_ 1367 RSLSts 0 "Normal_Operation" 1 "Antipanic" 2 "Fail_Present" 3 "Not_used" ;
VAL_ 1369 RearLeftAntiPinchFailSts 0 "Fail_not_Present" 1 "Fail_Present" ;
VAL_ 1369 RearRightAntiPinchFailSts 0 "Fail_not_Present" 1 "Fail_Present" ;
VAL_ 1369 WMRRFailSts 0 "Fail_not_Present" 1 "Fail_Present" ;
VAL_ 1369 WMRLFailsts 0 "Fail_Not_Present" 1 "Fail_Present" ;
VAL_ 1381 RearSeatLeftUserAction 0 "Not_Active" 1 "Active" ;
VAL_ 1381 RearSeatLeftBackrestFailSts 0 "Fail_Not_Present" 1 "Fail_Present" ;
VAL_ 1381 RearSeatRightUserAction 0 "Not_Active" 1 "Active" ;
VAL_ 1381 RearSeatRightBackrestFailSts 0 "Fail_Not_Present" 1 "Fail_Present" ;
VAL_ 1419 MKF_FrontPassengerHeating 0 "Not_active" 1 "Heat_level_1" 2 "Heat_level_2" 3 "Heat_level_3" ;
VAL_ 1419 MKF_FrontDriverHeating 0 "Not_active" 1 "Heat_level_1" 2 "Heat_level_2" 3 "Heat_level_3" ;
VAL_ 1419 MKF_DriverFans 0 "Not_active" 1 "Fan_level_1" 2 "Fan_level_2" 3 "Fan_level_3" ;
VAL_ 1419 MKF_PassengerFans 0 "Not_active" 1 "Fan_level_1" 2 "Fan_level_2" 3 "Fan_level_3" ;
VAL_ 1420 MKF_DriverAirFlowZone 0 "BLevel" 1 "Vent" 2 "HiLevel" 3 "Defrost" 4 "Heat" 5 "Floor" 6 "All" 7 "Auto" ;
VAL_ 1420 MKF_PassengerAirFlowZone 0 "BLevel" 1 "Vent" 2 "HiLevel" 3 "Defrost" 4 "Heat" 5 "Floor" 6 "All" 7 "Auto" ;
VAL_ 1420 MKF_RearExtendedClimate 0 "Not_Active" 1 "Active" ;
VAL_ 1420 MKF_AirConditionCompressor 0 "OFF" 1 "ON" ;
VAL_ 1420 MKF_MonoMode 0 "OFF" 1 "ON" ;
VAL_ 1420 MKF_BlowerSpeed10L 0 "OFF" 1 "Blower_Level_1" 2 "Blower_Level_2" 3 "Blower_Level_3" 4 "Blower_Level_4" 5 "Blower_Level_5" 6 "Blower_Level_6" 7 "Blower_Level_7" 8 "Blower_Level_8" 9 "AUTO" 10 "Not_used" 11 "Not_used" 12 "Not_used" 13 "Not_used" 14 "Not_used" 15 "Not_used" ;
VAL_ 1420 MKF_AirRecirculation 0 "OFF" 1 "ON" ;
VAL_ 1420 MKF_RearDefrostCommand 0 "OFF" 1 "ON" ;
VAL_ 1420 MKF_MaxDefrostCommand 0 "OFF" 1 "ON" ;
VAL_ 1422 MKF_RLHeating 0 "Not_active" 1 "Heat_level_1" 2 "Heat_level_2" 3 "Heat_level_3" ;
VAL_ 1422 MKF_RLFans 0 "Not_active" 1 "Fan_level_1" 2 "Fan_level_2" 3 "Fan_level_3" ;
VAL_ 1422 MKF_RRHeating 0 "Not_active" 1 "Heat_level_1" 2 "Heat_level_2" 3 "Heat_level_3" ;
VAL_ 1422 MKF_RRFans 0 "Not_active" 1 "Fan_level_1" 2 "Fan_level_2" 3 "Fan_level_3" ;
VAL_ 1423 MKF_RLAirFlowZone 0 "Vent" 1 "Floor" 2 "All" 3 "Auto" 4 "not_used" 5 "not_used" 6 "not_used" 7 "not_used" ;
VAL_ 1423 MKF_RRAirFlowZone 0 "Vent" 1 "Floor" 2 "All" 3 "Auto" 4 "not_used" 5 "not_used" 6 "not_used" 7 "not_used" ;
VAL_ 1423 MKF_RBlowerSpeed10L 0 "OFF" 1 "Blower_Level_1" 2 "Blower_Level_2" 3 "Blower_Level_3" 4 "Blower_Level_4" 5 "Blower_Level_5" 6 "Blower_Level_6" 7 "Blower_Level_7" 8 "Blower_Level_8" 9 "AUTO" 10 "Not_used" 11 "Not_used" 12 "Not_used" 13 "Not_used" 14 "Not_used" 15 "Not_used" ;
VAL_ 1425 MKR_RLHeating 0 "Not_active" 1 "Heat_level_1" 2 "Heat_level_2" 3 "Heat_level_3" ;
VAL_ 1425 MKR_RLFans 0 "Not_active" 1 "Fan_level_1" 2 "Fan_level_2" 3 "Fan_level_3" ;
VAL_ 1425 MKR_RRHeating 0 "Not_active" 1 "Heat_level_1" 2 "Heat_level_2" 3 "Heat_level_3" ;
VAL_ 1425 MKR_RRFans 0 "Not_active" 1 "Fan_level_1" 2 "Fan_level_2" 3 "Fan_level_3" ;
VAL_ 1426 MKR_RLAirFlowZone 0 "BLevel" 1 "Vent" 2 "HiLevel" 3 "Defrost" 4 "Heat" 5 "Floor" 6 "All" 7 "Auto" ;
VAL_ 1426 MKR_RRAirFlowZone 0 "BLevel" 1 "Vent" 2 "HiLevel" 3 "Defrost" 4 "Heat" 5 "Floor" 6 "All" 7 "Auto" ;
VAL_ 1426 MKR_RearAirConditionCompressor 0 "OFF" 1 "ON" ;
VAL_ 1426 MKR_RRAutoMode 0 "OFF" 1 "ON" ;
VAL_ 1426 MKR_RLAutoMode 0 "OFF" 1 "ON" ;
VAL_ 1426 MKR_RSBlowerSpeed10L 0 "OFF" 1 "Blower_Level_1" 2 "Blower_Level_2" 3 "Blower_Level_3" 4 "Blower_Level_4" 5 "Blower_Level_5" 6 "Blower_Level_6" 7 "Blower_Level_7" 8 "Blower_Level_8" 9 "AUTO" 10 "Not_used" 11 "Not_used" 12 "Not_used" 13 "Not_used" 14 "Not_used" 15 "Not_used" ;
VAL_ 1426 MKR_RearExtendedClimate 0 "Not_Active" 1 "Active" ;
SIG_GROUP_ 671 SUSPENSION_INFO_SigGroup 1 : CRC_SUSPENSION_INFO MsgCnt_SUSPENSION_INFO SuspensionSetupInfoForDisplay SuspensionSetupSts SuspensionSystemInfoForDisplay;
